VERSION "HNNBNNNYNNNNNNNNNNNNNNNNNNNNNNNNNNNNNNNNNN/4/%%%/4/'%**4NNN///"

NS_ :

BS_:

BU_: BAP_Tester BCM1 Gateway Gateway_PAG Klima_MSB Lift_VA VAS_L VAS_R

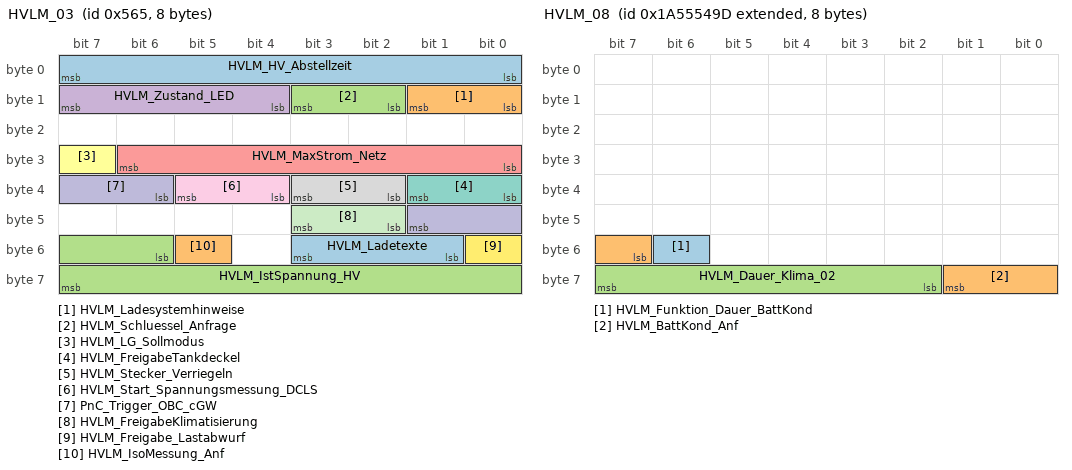
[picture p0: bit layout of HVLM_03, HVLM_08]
BO_ 1381 HVLM_03: 8 Gateway
 SG_ HVLM_HV_Abstellzeit : 0|8@1+ (4,0) [0|1012] "Unit_Minut"  Vector__XXX
 SG_ HVLM_Ladesystemhinweise : 8|2@1+ (1.0,0.0) [0.0|3] ""  Vector__XXX
 SG_ HVLM_Schluessel_Anfrage : 10|2@1+ (1.0,0.0) [0.0|3] ""  Vector__XXX
 SG_ HVLM_Zustand_LED : 12|4@1+ (1.0,0.0) [0.0|15] ""  Vector__XXX
 SG_ HVLM_MaxStrom_Netz : 24|7@1+ (0.5,0) [0.0|62.5] "Unit_Amper"  Vector__XXX
 SG_ HVLM_LG_Sollmodus : 31|1@1+ (1.0,0.0) [0.0|1] ""  Vector__XXX
 SG_ HVLM_FreigabeTankdeckel : 32|2@1+ (1.0,0.0) [0.0|3] ""  Vector__XXX
 SG_ HVLM_Stecker_Verriegeln : 34|2@1+ (1.0,0.0) [0.0|3] ""  Vector__XXX
 SG_ HVLM_Start_Spannungsmessung_DCLS : 36|2@1+ (1.0,0.0) [0.0|3] ""  Vector__XXX
 SG_ PnC_Trigger_OBC_cGW : 38|4@1+ (1.0,0.0) [0.0|15] ""  Vector__XXX
 SG_ HVLM_FreigabeKlimatisierung : 42|2@1+ (1.0,0.0) [0.0|3] ""  BCM1,Klima_MSB
 SG_ HVLM_Freigabe_Lastabwurf : 48|1@1+ (1.0,0.0) [0.0|1] ""  Vector__XXX
 SG_ HVLM_Ladetexte : 49|3@1+ (1.0,0.0) [0.0|7] ""  Vector__XXX
 SG_ HVLM_IsoMessung_Anf : 53|1@1+ (1.0,0.0) [0.0|1] ""  Vector__XXX
 SG_ HVLM_IstSpannung_HV : 54|10@1+ (1,0) [0|1021] "Unit_Volt"  Vector__XXX

BO_ 1340 HVLM_04: 8 Gateway
 SG_ HVLM_04_CRC : 0|8@1+ (1,0) [0|255] ""  Vector__XXX
 SG_ HVLM_04_BZ : 8|4@1+ (1,0) [0|15] ""  Vector__XXX
 SG_ HVLM_STH_Betriebsmodus : 12|3@1+ (1.0,0.0) [0.0|7] ""  BCM1,Klima_MSB
 SG_ HVLM_Standklima_Timer_Status : 15|1@1+ (1.0,0.0) [0.0|1] ""  BCM1,Klima_MSB
 SG_ HVLM_HVEM_MaxLeistung : 16|9@1+ (50,0) [0|25450] "Unit_Watt"  Vector__XXX
 SG_ HVLM_Status_Netz : 25|1@1+ (1.0,0.0) [0.0|1] ""  Vector__XXX
 SG_ HVLM_Anf_Ladescreen : 26|1@1+ (1.0,0.0) [0.0|1] ""  Vector__XXX
 SG_ HVLM_Ladeart : 27|2@1+ (1.0,0.0) [0.0|3] ""  Vector__XXX
 SG_ HVLM_VK_STH_Einsatz : 29|3@1+ (1.0,0.0) [0.0|7] ""  BCM1
 SG_ HVLM_VK_Modus : 32|2@1+ (1.0,0.0) [0.0|3] ""  BCM1,Klima_MSB
 SG_ HVLM_IstModus_02 : 34|2@1+ (1.0,0.0) [0.0|3] ""  Vector__XXX
 SG_ HVLM_HV_Anf : 36|2@1+ (1.0,0.0) [0.0|3] ""  Vector__XXX
 SG_ HVLM_Fehlerstatus : 38|3@1+ (1.0,0.0) [0.0|7] ""  Vector__XXX
 SG_ HVLM_Anforderung_HMS : 41|3@1+ (1.0,0.0) [0.0|7] ""  Vector__XXX
 SG_ HVLM_Parken_beibehalten_HMS : 44|2@1+ (1.0,0.0) [0.0|3] ""  Vector__XXX
 SG_ HVLM_Status_Tankklappe : 46|2@1+ (1.0,0.0) [0.0|3] ""  Vector__XXX
 SG_ HVLM_AWC_Sollmodus : 48|3@1+ (1.0,0.0) [0.0|7] ""  Vector__XXX
 SG_ HVLM_Stecker_Status : 51|2@1+ (1.0,0.0) [0.0|3] ""  Vector__XXX
 SG_ HVLM_LadeAnforderung : 53|3@1+ (1.0,0.0) [0.0|7] ""  Vector__XXX
 SG_ HVLM_MaxBatLadestromHV : 56|8@1+ (1,0) [0|253] "Unit_Amper"  Vector__XXX

BO_ 2589283485 HVLM_08: 8 Gateway
 SG_ HVLM_Funktion_Dauer_BattKond : 54|1@1+ (1.0,0.0) [0.0|1] ""  Vector__XXX
 SG_ HVLM_BattKond_Anf : 55|3@1+ (1.0,0.0) [0.0|7] ""  Vector__XXX
 SG_ HVLM_Dauer_Klima_02 : 58|6@1+ (1,0) [0|60] "Unit_Minut"  BCM1,Klima_MSB

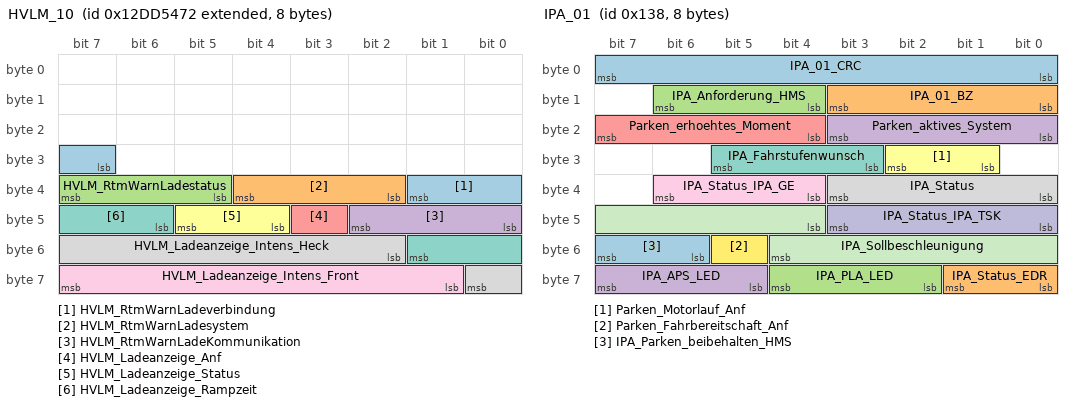
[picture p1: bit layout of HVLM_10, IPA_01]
BO_ 2463978610 HVLM_10: 8 Gateway
 SG_ HVLM_RtmWarnLadeverbindung : 31|3@1+ (1.0,0.0) [0.0|7] ""  Vector__XXX
 SG_ HVLM_RtmWarnLadesystem : 34|3@1+ (1.0,0.0) [0.0|7] ""  Vector__XXX
 SG_ HVLM_RtmWarnLadestatus : 37|3@1+ (1.0,0.0) [0.0|7] ""  Vector__XXX
 SG_ HVLM_RtmWarnLadeKommunikation : 40|3@1+ (1.0,0.0) [0.0|7] ""  Vector__XXX
 SG_ HVLM_Ladeanzeige_Anf : 43|1@1+ (1.0,0.0) [0.0|1] ""  BCM1
 SG_ HVLM_Ladeanzeige_Status : 44|2@1+ (1.0,0.0) [0.0|3] ""  BCM1
 SG_ HVLM_Ladeanzeige_Rampzeit : 46|4@1+ (50,0) [0|750] "Unit_MilliSecon"  Vector__XXX
 SG_ HVLM_Ladeanzeige_Intens_Heck : 50|7@1+ (1,0) [0|100] "Unit_PerCent"  Vector__XXX
 SG_ HVLM_Ladeanzeige_Intens_Front : 57|7@1+ (1,0) [0|100] "Unit_PerCent"  Vector__XXX

BO_ 1524 Innenlicht_11: 8 BCM1
 SG_ IL_Dimmung_V_Tuerkontur : 0|8@1+ (1,0) [0|100] "Unit_PerCent"  Gateway,Gateway_PAG
 SG_ IL_Dimmung_H_Tuerkontur : 8|8@1+ (1,0) [0|100] "Unit_PerCent"  Gateway,Gateway_PAG
 SG_ IL_Dimmung_Tuerinnengriff : 16|8@1+ (1,0) [0|100] "Unit_PerCent"  Gateway,Gateway_PAG
 SG_ IL_Dimmung_Umfeldbel : 24|8@1+ (1,0) [0|100] "Unit_PerCent"  Gateway,Gateway_PAG
 SG_ IL_Bel_FS_Ausstieg : 32|1@1+ (1.0,0.0) [0.0|1] ""  Gateway,Gateway_PAG
 SG_ IL_Bel_BFS_Ausstieg : 33|1@1+ (1.0,0.0) [0.0|1] ""  Gateway,Gateway_PAG
 SG_ IL_Bel_HFS_Ausstieg : 34|1@1+ (1.0,0.0) [0.0|1] ""  Gateway,Gateway_PAG
 SG_ IL_Bel_HBFS_Ausstieg : 35|1@1+ (1.0,0.0) [0.0|1] ""  Gateway,Gateway_PAG
 SG_ BCM1_Innenlicht_gedimmt_V : 36|1@1+ (1.0,0.0) [0.0|1] ""  Gateway,Gateway_PAG
 SG_ BCM1_Innenlicht_gedimmt_H : 37|1@1+ (1.0,0.0) [0.0|1] ""  Gateway,Gateway_PAG
 SG_ IL_Innenlicht_aktiv : 38|1@1+ (1.0,0.0) [0.0|1] ""  Gateway,Gateway_PAG
 SG_ IL_Klemme_30G_aktiv : 39|1@1+ (1.0,0.0) [0.0|1] ""  Gateway,Gateway_PAG
 SG_ BCM1_DI_Rampe_Innenlicht : 40|1@1+ (1.0,0.0) [0.0|1] ""  Gateway,Gateway_PAG
 SG_ BCM1_DI_Rampe_Leselicht : 41|1@1+ (1.0,0.0) [0.0|1] ""  Gateway,Gateway_PAG
 SG_ BCM1_Innenlicht_H : 42|1@1+ (1.0,0.0) [0.0|1] ""  Gateway,Gateway_PAG
 SG_ BCM1_Innenlicht_V : 43|1@1+ (1.0,0.0) [0.0|1] ""  Gateway,Gateway_PAG
 SG_ BCM1_Leselicht_Anf_hl : 44|1@1+ (1.0,0.0) [0.0|1] ""  Gateway,Gateway_PAG
 SG_ BCM1_Leselicht_Anf_hr : 45|1@1+ (1.0,0.0) [0.0|1] ""  Gateway,Gateway_PAG
 SG_ BCM1_Leselicht_Anf_vl : 46|1@1+ (1.0,0.0) [0.0|1] ""  Gateway,Gateway_PAG
 SG_ BCM1_Leselicht_Anf_vr : 47|1@1+ (1.0,0.0) [0.0|1] ""  Gateway,Gateway_PAG
 SG_ BCM1_Leuchten_Aus : 48|1@1+ (1.0,0.0) [0.0|1] ""  Gateway,Gateway_PAG
 SG_ AMB_Charisma_FahrPr : 49|4@1+ (1.0,0.0) [0.0|15] ""  Gateway,Gateway_PAG
 SG_ AMB_Charisma_Status : 53|2@1+ (1.0,0.0) [0.0|3] ""  Gateway,Gateway_PAG
 SG_ IL_Dimmung_Lautspr : 56|8@1+ (1,0) [0|100] "Unit_PerCent"  Gateway,Gateway_PAG

BO_ 312 IPA_01: 8 Gateway
 SG_ IPA_01_CRC : 0|8@1+ (1,0) [0|255] ""  Vector__XXX
 SG_ IPA_01_BZ : 8|4@1+ (1,0) [0|15] ""  Vector__XXX
 SG_ IPA_Anforderung_HMS : 12|3@1+ (1.0,0.0) [0.0|7] ""  Vector__XXX
 SG_ Parken_aktives_System : 16|4@1+ (1.0,0.0) [0.0|15] ""  BCM1
 SG_ Parken_erhoehtes_Moment : 20|4@1+ (1.0,0.0) [0.0|15] ""  Vector__XXX
 SG_ Parken_Motorlauf_Anf : 25|2@1+ (1.0,0.0) [0.0|3] ""  Vector__XXX
 SG_ IPA_Fahrstufenwunsch : 27|3@1+ (1.0,0.0) [0.0|7] ""  Vector__XXX
 SG_ IPA_Status : 32|4@1+ (1.0,0.0) [0.0|15] ""  Vector__XXX
 SG_ IPA_Status_IPA_GE : 36|3@1+ (1.0,0.0) [0.0|7] ""  Vector__XXX
 SG_ IPA_Status_IPA_TSK : 40|4@1+ (1.0,0.0) [0.0|15] ""  BCM1
 SG_ IPA_Sollbeschleunigung : 44|9@1+ (0.01,-4.11) [-4.10|1.00] "Unit_MeterPerSeconSquar"  Vector__XXX
 SG_ Parken_Fahrbereitschaft_Anf : 53|1@1+ (1.0,0.0) [0.0|1] ""  Vector__XXX
 SG_ IPA_Parken_beibehalten_HMS : 54|2@1+ (1.0,0.0) [0.0|3] ""  Vector__XXX
 SG_ IPA_Status_EDR : 56|2@1+ (1.0,0.0) [0.0|3] ""  Vector__XXX
 SG_ IPA_PLA_LED : 58|3@1+ (1.0,0.0) [0.0|7] ""  BCM1
 SG_ IPA_APS_LED : 61|3@1+ (1.0,0.0) [0.0|7] ""  BCM1

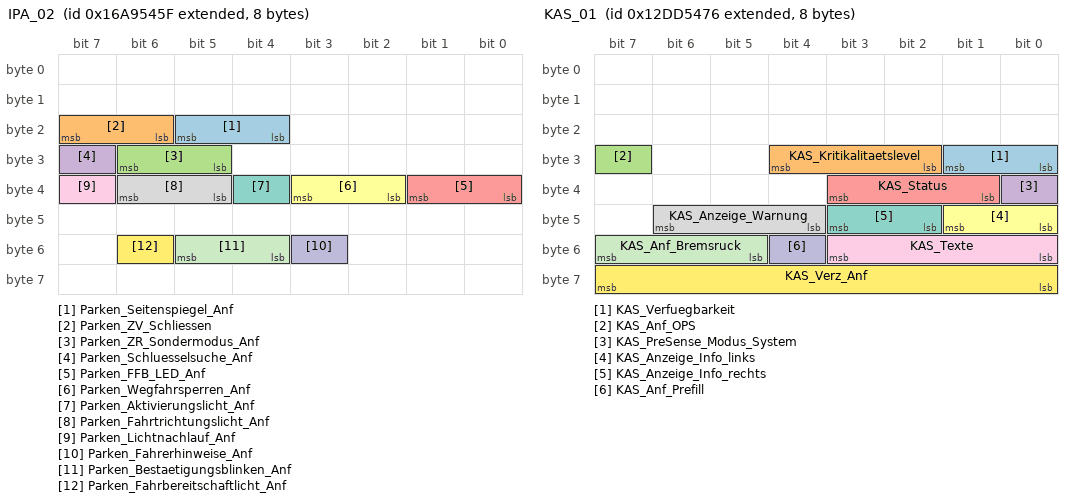
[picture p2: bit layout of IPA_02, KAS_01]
BO_ 2527679583 IPA_02: 8 Gateway
 SG_ Parken_Seitenspiegel_Anf : 20|2@1+ (1.0,0.0) [0.0|3] ""  Vector__XXX
 SG_ Parken_ZV_Schliessen : 22|2@1+ (1.0,0.0) [0.0|3] ""  Vector__XXX
 SG_ Parken_ZR_Sondermodus_Anf : 29|2@1+ (1.0,0.0) [0.0|3] ""  Vector__XXX
 SG_ Parken_Schluesselsuche_Anf : 31|1@1+ (1.0,0.0) [0.0|1] ""  Vector__XXX
 SG_ Parken_FFB_LED_Anf : 32|2@1+ (1.0,0.0) [0.0|3] ""  Vector__XXX
 SG_ Parken_Wegfahrsperren_Anf : 34|2@1+ (1.0,0.0) [0.0|3] ""  Vector__XXX
 SG_ Parken_Aktivierungslicht_Anf : 36|1@1+ (1.0,0.0) [0.0|1] ""  BCM1
 SG_ Parken_Fahrtrichtungslicht_Anf : 37|2@1+ (1.0,0.0) [0.0|3] ""  BCM1
 SG_ Parken_Lichtnachlauf_Anf : 39|1@1+ (1.0,0.0) [0.0|1] ""  BCM1
 SG_ Parken_Fahrerhinweise_Anf : 51|1@1+ (1.0,0.0) [0.0|1] ""  Vector__XXX
 SG_ Parken_Bestaetigungsblinken_Anf : 52|2@1+ (1.0,0.0) [0.0|3] ""  BCM1
 SG_ Parken_Fahrbereitschaftlicht_Anf : 54|1@1+ (1.0,0.0) [0.0|1] ""  BCM1

BO_ 1806 ISO_BCM1_Req: 8 Gateway
 SG_ ISO_BCM1_Req_Data : 0|64@1+ (1.0,0.0) [0.0|18446744073709551615] ""  BCM1

BO_ 1912 ISO_BCM1_Resp: 8 BCM1
 SG_ ISO_BCM1_Resp_Data : 0|64@1+ (1.0,0.0) [0.0|18446744073709551615] ""  Gateway,Gateway_PAG

BO_ 1792 ISO_Funktionaler_Req_All: 8 Gateway
 SG_ ISO_ALL_01_Req_Data : 0|64@1+ (1.0,0.0) [0.0|18446744073709551615] ""  BCM1,Klima_MSB,Lift_VA,VAS_L,VAS_R

BO_ 1862 ISO_Klima_Req: 8 Gateway
 SG_ ISO_Klima_Req_Data : 0|64@1+ (1.0,0.0) [0.0|18446744073709551615] ""  Klima_MSB

BO_ 1968 ISO_Klima_Resp: 8 Klima_MSB
 SG_ ISO_Klima_Resp_Data : 0|64@1+ (1.0,0.0) [0.0|18446744073709551615] ""  Gateway,Gateway_PAG

BO_ 1881 ISO_Lift_Req: 8 Gateway
 SG_ ISO_Lift_Req_Data : 0|64@1+ (1,0) [0|18446744073709551615] "Unit_None"  Lift_VA

BO_ 1987 ISO_Lift_Resp: 8 Lift_VA
 SG_ ISO_Lift_Resp_Data : 0|64@1+ (1,0) [0|18446744073709551615] "Unit_None"  Gateway,Gateway_PAG

BO_ 2549874840 ISOx_DMD_L_Req: 8 Gateway
 SG_ ISOx_DMD_L_Req_Data : 0|64@1+ (1.0,0.0) [0.0|18446744073709551615] ""  BCM1

BO_ 2550005912 ISOx_DMD_L_Resp: 8 BCM1
 SG_ ISOx_DMD_L_Resp_Data : 0|64@1+ (1.0,0.0) [0.0|18446744073709551615] ""  Gateway,Gateway_PAG

BO_ 2549874841 ISOx_DMD_R_Req: 8 Gateway
 SG_ ISOx_DMD_R_Req_Data : 0|64@1+ (1.0,0.0) [0.0|18446744073709551615] ""  BCM1

BO_ 2550005913 ISOx_DMD_R_Resp: 8 BCM1
 SG_ ISOx_DMD_R_Resp_Data : 0|64@1+ (1.0,0.0) [0.0|18446744073709551615] ""  Gateway,Gateway_PAG

BO_ 2549874818 ISOx_LCM_L_Req: 8 Gateway
 SG_ ISOx_LCM_L_Req_Data : 0|64@1+ (1.0,0.0) [0.0|18446744073709551615] ""  BCM1

BO_ 2550005890 ISOx_LCM_L_Resp: 8 BCM1
 SG_ ISOx_LCM_L_Resp_Data : 0|64@1+ (1.0,0.0) [0.0|18446744073709551615] ""  Gateway,Gateway_PAG

BO_ 2549874819 ISOx_LCM_R_Req: 8 Gateway
 SG_ ISOx_LCM_R_Req_Data : 0|64@1+ (1.0,0.0) [0.0|18446744073709551615] ""  BCM1

BO_ 2550005891 ISOx_LCM_R_Resp: 8 BCM1
 SG_ ISOx_LCM_R_Resp_Data : 0|64@1+ (1.0,0.0) [0.0|18446744073709551615] ""  Gateway,Gateway_PAG

BO_ 2549874838 ISOx_LED_LM_L_Req: 8 Gateway
 SG_ ISOx_LED_LM_L_Req_Data : 0|64@1+ (1.0,0.0) [0.0|18446744073709551615] ""  BCM1

BO_ 2550005910 ISOx_LED_LM_L_Resp: 8 BCM1
 SG_ ISOx_LED_LM_L_Resp_Data : 0|64@1+ (1.0,0.0) [0.0|18446744073709551615] ""  Gateway,Gateway_PAG

BO_ 2549874839 ISOx_LED_LM_R_Req: 8 Gateway
 SG_ ISOx_LED_LM_R_Req_Data : 0|64@1+ (1.0,0.0) [0.0|18446744073709551615] ""  BCM1

BO_ 2550005911 ISOx_LED_LM_R_Resp: 8 BCM1
 SG_ ISOx_LED_LM_R_Resp_Data : 0|64@1+ (1.0,0.0) [0.0|18446744073709551615] ""  Gateway,Gateway_PAG

BO_ 2549874884 ISOx_VAS_L_Req: 8 Gateway
 SG_ ISOx_VAS_L_Req_Data : 0|64@1+ (1.0,0.0) [0.0|18446744073709551615] ""  VAS_L

BO_ 2550005956 ISOx_VAS_L_Resp: 8 VAS_L
 SG_ ISOx_VAS_L_Resp_Data : 0|64@1+ (1.0,0.0) [0.0|18446744073709551615] ""  Gateway,Gateway_PAG

BO_ 2549874885 ISOx_VAS_R_Req: 8 Gateway
 SG_ ISOx_VAS_R_Req_Data : 0|64@1+ (1.0,0.0) [0.0|18446744073709551615] ""  VAS_R

BO_ 2550005957 ISOx_VAS_R_Resp: 8 VAS_R
 SG_ ISOx_VAS_R_Resp_Data : 0|64@1+ (1.0,0.0) [0.0|18446744073709551615] ""  Gateway,Gateway_PAG

BO_ 2549874843 ISOx_zDML_Req: 8 Gateway
 SG_ ISOx_zDML_Req_Data : 0|64@1+ (1.0,0.0) [0.0|18446744073709551615] ""  BCM1

BO_ 2550005915 ISOx_zDML_Resp: 8 BCM1
 SG_ ISOx_zDML_Resp_Data : 0|64@1+ (1.0,0.0) [0.0|18446744073709551615] ""  Gateway,Gateway_PAG

BO_ 2463978614 KAS_01: 8 Gateway
 SG_ KAS_Verfuegbarkeit : 24|2@1+ (1.0,0.0) [0.0|3] ""  Vector__XXX
 SG_ KAS_Kritikalitaetslevel : 26|3@1+ (1.0,0.0) [0.0|7] ""  BCM1
 SG_ KAS_Anf_OPS : 31|1@1+ (1.0,0.0) [0.0|1] ""  BCM1
 SG_ KAS_PreSense_Modus_System : 32|1@1+ (1.0,0.0) [0.0|1] ""  Vector__XXX
 SG_ KAS_Status : 33|3@1+ (1.0,0.0) [0.0|7] ""  Vector__XXX
 SG_ KAS_Anzeige_Info_links : 40|2@1+ (1.0,0.0) [0.0|3] ""  Vector__XXX
 SG_ KAS_Anzeige_Info_rechts : 42|2@1+ (1.0,0.0) [0.0|3] ""  Vector__XXX
 SG_ KAS_Anzeige_Warnung : 44|3@1+ (1.0,0.0) [0.0|7] ""  Vector__XXX
 SG_ KAS_Texte : 48|4@1+ (1.0,0.0) [0.0|15] ""  Vector__XXX
 SG_ KAS_Anf_Prefill : 52|1@1+ (1.0,0.0) [0.0|1] ""  Vector__XXX
 SG_ KAS_Anf_Bremsruck : 53|3@1+ (1.0,0.0) [0.0|7] ""  Vector__XXX
 SG_ KAS_Verz_Anf : 56|8@1+ (0.079,-19.987) [-19.987|0.000] "Unit_MeterPerSeconSquar"  Vector__XXX

BO_ 497 Kessy_11: 8 Gateway
 SG_ KY_IDG_in_Reichweite : 12|1@1+ (1.0,0.0) [0.0|1] ""  Vector__XXX
 SG_ KY_Auf_Taste : 13|1@1+ (1.0,0.0) [0.0|1] ""  Vector__XXX
 SG_ KY_HDF_Taste : 14|1@1+ (1.0,0.0) [0.0|1] ""  BCM1
 SG_ KY_Panik_Taste : 15|1@1+ (1.0,0.0) [0.0|1] ""  Vector__XXX
 SG_ KY_Zu_Taste : 16|1@1+ (1.0,0.0) [0.0|1] ""  Vector__XXX
 SG_ KY_FT_Entriegelung_Autorisiert : 17|1@1+ (1.0,0.0) [0.0|1] ""  BCM1
 SG_ KY_FT_Verriegelung_Autorisiert : 18|1@1+ (1.0,0.0) [0.0|1] ""  Vector__XXX
 SG_ KY_BT_Entriegelung_Autorisiert : 19|1@1+ (1.0,0.0) [0.0|1] ""  Vector__XXX
 SG_ KY_BT_Verriegelung_Autorisiert : 20|1@1+ (1.0,0.0) [0.0|1] ""  Vector__XXX
 SG_ KY_HFS_Entriegelung_Autorisiert : 21|1@1+ (1.0,0.0) [0.0|1] ""  Vector__XXX
 SG_ KY_HFS_Verriegelung_Autorisiert : 22|1@1+ (1.0,0.0) [0.0|1] ""  Vector__XXX
 SG_ KY_HBFS_Entriegelung_Autorisiert : 23|1@1+ (1.0,0.0) [0.0|1] ""  Vector__XXX
 SG_ KY_HBFS_Verriegelung_Autorisiert : 24|1@1+ (1.0,0.0) [0.0|1] ""  Vector__XXX
 SG_ KY_Front_Entr_Autorisiert : 25|1@1+ (1.0,0.0) [0.0|1] ""  BCM1
 SG_ KY_Front_Verr_Autorisiert : 26|1@1+ (1.0,0.0) [0.0|1] ""  BCM1
 SG_ KY_HD_Entriegelung_Autorisiert : 27|1@1+ (1.0,0.0) [0.0|1] ""  Vector__XXX
 SG_ KY_HD_Verriegelung_Autorisiert : 28|1@1+ (1.0,0.0) [0.0|1] ""  Vector__XXX
 SG_ KY_Bereich : 29|3@1+ (1.0,0.0) [0.0|7] ""  BCM1
 SG_ KY_Position : 32|3@1+ (1.0,0.0) [0.0|7] ""  BCM1
 SG_ KY_ZV_Signatur : 35|11@1+ (1,0) [0|2047] "Unit_None"  Vector__XXX
 SG_ Schluesselnr_Personalisierung : 46|4@1+ (1.0,0.0) [0.0|15] ""  BCM1,Klima_MSB
 SG_ FFB_FDF_Taste : 50|1@1+ (1.0,0.0) [0.0|1] ""  BCM1
 SG_ FFB_Joker_Taste : 51|1@1+ (1.0,0.0) [0.0|1] ""  BCM1
 SG_ FFB_Park_Taste : 52|1@1+ (1.0,0.0) [0.0|1] ""  Vector__XXX
 SG_ FFB_Remotestart_Taste : 53|1@1+ (1.0,0.0) [0.0|1] ""  Vector__XXX
 SG_ FBS_Aktivierung_Pilot_Parken : 54|1@1+ (1.0,0.0) [0.0|1] ""  Vector__XXX
 SG_ KY_Schluessel_im_Fzg : 55|1@1+ (1.0,0.0) [0.0|1] ""  Vector__XXX
 SG_ KY_EasyClose_Abbruch : 56|1@1+ (1.0,0.0) [0.0|1] ""  Vector__XXX
 SG_ KY_EasyClose_Status : 57|3@1+ (1.0,0.0) [0.0|7] ""  Vector__XXX
 SG_ KY_HD_Auffahrt : 60|1@1+ (1.0,0.0) [0.0|1] ""  Vector__XXX
 SG_ KY_HD_Zufahrt : 61|1@1+ (1.0,0.0) [0.0|1] ""  Vector__XXX
 SG_ KY_LKL_1_Autorisierung : 62|1@1+ (1.0,0.0) [0.0|1] ""  Vector__XXX
 SG_ KY_LKL_2_Autorisierung : 63|1@1+ (1.0,0.0) [0.0|1] ""  Vector__XXX

BO_ 1424 Kessy_12: 8 Gateway
 SG_ FBS_Warn_Schluessel_Batt : 12|1@1+ (1.0,0.0) [0.0|1] ""  Vector__XXX
 SG_ KY_FFB_Frequenz : 13|2@1+ (1.0,0.0) [0.0|3] ""  Vector__XXX
 SG_ KY_HF_Aktiv : 15|1@1+ (1.0,0.0) [0.0|1] ""  Vector__XXX
 SG_ KY_LF_Aktiv : 16|1@1+ (1.0,0.0) [0.0|1] ""  Vector__XXX
 SG_ KY_KYL_Fahrer_Hinweise : 17|3@1+ (1.0,0.0) [0.0|7] ""  Vector__XXX
 SG_ KY_StartStopp_Info : 20|2@1+ (1.0,0.0) [0.0|3] ""  Vector__XXX
 SG_ KY_Keyless_Verbau : 22|1@1+ (1.0,0.0) [0.0|1] ""  Vector__XXX
 SG_ KY_Keyless_Go_Verbau : 23|1@1+ (1.0,0.0) [0.0|1] ""  Vector__XXX
 SG_ KY_Transponder_aktiv : 24|1@1+ (1.0,0.0) [0.0|1] ""  BCM1
 SG_ KYL_Warn_kein_Schluessel : 25|1@1+ (1.0,0.0) [0.0|1] ""  Vector__XXX
 SG_ KYL_Warn_Kessy_defekt : 26|1@1+ (1.0,0.0) [0.0|1] ""  Vector__XXX
 SG_ KYL_Warn_Notzuendschloss : 27|1@1+ (1.0,0.0) [0.0|1] ""  Vector__XXX
 SG_ KY_Fzg_Verlassen_erkannt : 28|1@1+ (1.0,0.0) [0.0|1] ""  Vector__XXX
 SG_ KY_Fzg_Zugang_erkannt : 29|1@1+ (1.0,0.0) [0.0|1] ""  Vector__XXX
 SG_ KY_Indikator_Mehrere_Schluessel : 30|1@1+ (1.0,0.0) [0.0|1] ""  Vector__XXX
 SG_ KY_NFC_Fahrer_Hinweise : 41|3@1+ (1.0,0.0) [0.0|7] ""  Vector__XXX
 SG_ KST_Wegstrecke_Challenge : 44|20@1+ (1.0,0.0) [0.0|1048575] ""  Vector__XXX

BO_ 960 Klemmen_Status_01: 4 BCM1
 SG_ Klemmen_Status_01_CRC : 0|8@1+ (1,0) [0|255] ""  BCM1,Gateway,Gateway_PAG
 SG_ Klemmen_Status_01_BZ : 8|4@1+ (1,0) [0|15] ""  BCM1,Gateway,Gateway_PAG,Lift_VA
 SG_ RSt_Fahrerhinweise : 12|4@1+ (1.0,0.0) [0.0|15] ""  Gateway,Gateway_PAG
 SG_ ZAS_Kl_S : 16|1@1+ (1.0,0.0) [0.0|1] ""  BCM1,Gateway,Gateway_PAG,Klima_MSB,VAS_L,VAS_R
 SG_ ZAS_Kl_15 : 17|1@1+ (1.0,0.0) [0.0|1] ""  BCM1,Gateway,Gateway_PAG,Klima_MSB,Lift_VA,VAS_L,VAS_R
 SG_ ZAS_Kl_X : 18|1@1+ (1.0,0.0) [0.0|1] ""  Gateway,Gateway_PAG
 SG_ ZAS_Kl_50_Startanforderung : 19|1@1+ (1.0,0.0) [0.0|1] ""  BCM1,Gateway,Gateway_PAG,Klima_MSB
 SG_ BCM_Remotestart_Betrieb : 20|1@1+ (1.0,0.0) [0.0|1] ""  BCM1,Gateway,Gateway_PAG,Klima_MSB
 SG_ ZAS_Kl_Infotainment : 21|1@1+ (1.0,0.0) [0.0|1] ""  Gateway,Gateway_PAG
 SG_ BCM_Remotestart_KL15_Anf : 22|1@1+ (1.0,0.0) [0.0|1] ""  BCM1,Gateway,Gateway_PAG
 SG_ BCM_Remotestart_MO_Start : 23|1@1+ (1.0,0.0) [0.0|1] ""  Gateway,Gateway_PAG
 SG_ KST_Warn_P1_ZST_def : 24|1@1+ (1.0,0.0) [0.0|1] ""  Gateway,Gateway_PAG
 SG_ KST_Warn_P2_ZST_def : 25|1@1+ (1.0,0.0) [0.0|1] ""  Gateway,Gateway_PAG
 SG_ KST_Fahrerhinweis_1 : 26|1@1+ (1.0,0.0) [0.0|1] ""  Gateway,Gateway_PAG
 SG_ KST_Fahrerhinweis_2 : 27|1@1+ (1.0,0.0) [0.0|1] ""  Gateway,Gateway_PAG
 SG_ BCM_Ausparken_Betrieb : 28|1@1+ (1.0,0.0) [0.0|1] ""  Gateway,Gateway_PAG
 SG_ KST_Fahrerhinweis_4 : 29|1@1+ (1.0,0.0) [0.0|1] ""  Gateway,Gateway_PAG
 SG_ KST_Fahrerhinweis_5 : 30|1@1+ (1.0,0.0) [0.0|1] ""  Gateway,Gateway_PAG
 SG_ KST_Fahrerhinweis_6 : 31|1@1+ (1.0,0.0) [0.0|1] ""  Gateway,Gateway_PAG

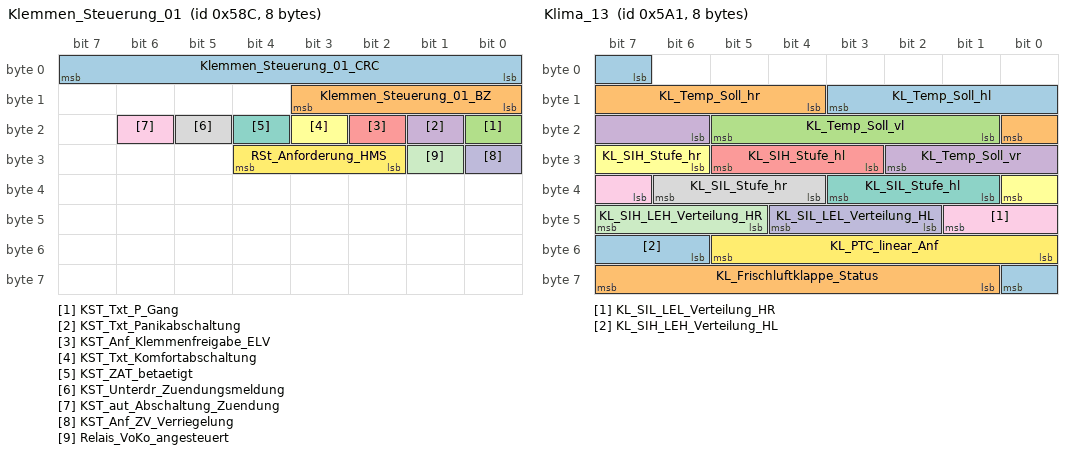
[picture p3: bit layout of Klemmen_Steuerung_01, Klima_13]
BO_ 1420 Klemmen_Steuerung_01: 8 Gateway
 SG_ Klemmen_Steuerung_01_CRC : 0|8@1+ (1,0) [0|255] ""  Vector__XXX
 SG_ Klemmen_Steuerung_01_BZ : 8|4@1+ (1,0) [0|15] ""  Vector__XXX
 SG_ KST_Txt_P_Gang : 16|1@1+ (1.0,0.0) [0.0|1] ""  Vector__XXX
 SG_ KST_Txt_Panikabschaltung : 17|1@1+ (1.0,0.0) [0.0|1] ""  Vector__XXX
 SG_ KST_Anf_Klemmenfreigabe_ELV : 18|1@1+ (1.0,0.0) [0.0|1] ""  Vector__XXX
 SG_ KST_Txt_Komfortabschaltung : 19|1@1+ (1.0,0.0) [0.0|1] ""  Vector__XXX
 SG_ KST_ZAT_betaetigt : 20|1@1+ (1.0,0.0) [0.0|1] ""  Vector__XXX
 SG_ KST_Unterdr_Zuendungsmeldung : 21|1@1+ (1.0,0.0) [0.0|1] ""  Vector__XXX
 SG_ KST_aut_Abschaltung_Zuendung : 22|1@1+ (1.0,0.0) [0.0|1] ""  BCM1
 SG_ KST_Anf_ZV_Verriegelung : 24|1@1+ (1.0,0.0) [0.0|1] ""  Vector__XXX
 SG_ Relais_VoKo_angesteuert : 25|1@1+ (1.0,0.0) [0.0|1] ""  BCM1
 SG_ RSt_Anforderung_HMS : 26|3@1+ (1.0,0.0) [0.0|7] ""  Vector__XXX

BO_ 1646 Klima_03: 8 BCM1
 SG_ KL_STL_aktiv : 0|1@1+ (1.0,0.0) [0.0|1] ""  Gateway,Gateway_PAG
 SG_ KL_STH_aktiv : 1|1@1+ (1.0,0.0) [0.0|1] ""  BCM1,Gateway,Gateway_PAG
 SG_ KL_Solarluefter_aktiv : 2|1@1+ (1.0,0.0) [0.0|1] ""  Gateway,Gateway_PAG
 SG_ KL_Umluft_Taste : 3|1@1+ (1.0,0.0) [0.0|1] ""  Gateway,Gateway_PAG
 SG_ KL_Geblaese_Fond_Status : 4|4@1+ (1.0,0.0) [0.0|15] ""  BCM1,Gateway,Gateway_PAG
 SG_ KL_STH_Ansteuerung : 8|2@1+ (1.0,0.0) [0.0|3] ""  Gateway,Gateway_PAG
 SG_ KL_STH_Betriebsdauer : 10|6@1+ (1,0) [0|60] "Unit_Minut"  Gateway,Gateway_PAG
 SG_ KL_Magnetventil : 16|1@1+ (1.0,0.0) [0.0|1] ""  Gateway,Gateway_PAG
 SG_ KL_WaPu : 17|1@1+ (1.0,0.0) [0.0|1] ""  Gateway,Gateway_PAG
 SG_ KL_Geblaese_Status : 18|4@1+ (1.0,0.0) [0.0|15] ""  BCM1,Gateway,Gateway_PAG
 SG_ KL_Restwaerme_aktiv : 22|1@1+ (1.0,0.0) [0.0|1] ""  Gateway,Gateway_PAG
 SG_ KL_Kompressorkupplung : 23|1@1+ (1.0,0.0) [0.0|1] ""  BCM1,Gateway,Gateway_PAG
 SG_ KL_BCmE_Livetip_Freigabe : 24|1@1+ (1.0,0.0) [0.0|1] ""  Gateway,Gateway_PAG
 SG_ KL_HYB_ASV_hinten_schliessen_Anf : 25|1@1+ (1.0,0.0) [0.0|1] ""  Gateway,Gateway_PAG
 SG_ KL_HYB_ASV_vorne_schliessen_Anf : 26|1@1+ (1.0,0.0) [0.0|1] ""  Gateway,Gateway_PAG
 SG_ KL_ErwVK_Zusatzrelais : 27|1@1+ (1.0,0.0) [0.0|1] ""  Gateway,Gateway_PAG
 SG_ KL_Status_Beduftung : 28|1@1+ (1.0,0.0) [0.0|1] ""  Gateway,Gateway_PAG
 SG_ KL_Status_Ionisator_Front : 29|1@1+ (1.0,0.0) [0.0|1] ""  Gateway,Gateway_PAG
 SG_ KL_STH_Timer_Status : 30|1@1+ (1.0,0.0) [0.0|1] ""  Gateway,Gateway_PAG
 SG_ KL_ErwVK_Anf : 31|1@1+ (1.0,0.0) [0.0|1] ""  BCM1,Gateway,Gateway_PAG
 SG_ KL_Innen_Temp : 32|8@1+ (0.5,-50) [-50.0|76.0] "Unit_DegreCelsi"  BCM1,Gateway,Gateway_PAG
 SG_ KL_I_Geblaese_Fond : 40|8@1+ (0.25,0) [0.00|63.50] "Unit_Amper"  Gateway,Gateway_PAG
 SG_ KL_Anf_AussenspiegelHzg : 48|1@1+ (1.0,0.0) [0.0|1] ""  Gateway,Gateway_PAG,VAS_L,VAS_R
 SG_ KL_Heizkreisventilstellung : 49|2@1+ (1.0,0.0) [0.0|3] ""  Gateway,Gateway_PAG
 SG_ KL_FSH_Automatikbetrieb : 51|1@1+ (1.0,0.0) [0.0|1] ""  Gateway,Gateway_PAG
 SG_ KL_SIH_LEH_Verteilung_VL : 52|3@1+ (1.0,0.0) [0.0|7] ""  Gateway,Gateway_PAG
 SG_ KL_SIH_LEL_Verteilung_VL : 55|3@1+ (1.0,0.0) [0.0|7] ""  BCM1,Gateway,Gateway_PAG
 SG_ KL_SIH_LEH_Verteilung_VR : 58|3@1+ (1.0,0.0) [0.0|7] ""  BCM1,Gateway,Gateway_PAG
 SG_ KL_SIH_LEL_Verteilung_VR : 61|3@1+ (1.0,0.0) [0.0|7] ""  Gateway,Gateway_PAG

BO_ 1663 Klima_05: 8 BCM1
 SG_ KL_Mod_Display_li : 0|4@1+ (1.0,0.0) [0.0|15] ""  Gateway,Gateway_PAG
 SG_ KL_Mod_Display_re : 4|4@1+ (1.0,0.0) [0.0|15] ""  Gateway,Gateway_PAG
 SG_ KL_Fondbed_vorne_aktiv : 8|1@1+ (1.0,0.0) [0.0|1] ""  Gateway,Gateway_PAG
 SG_ KL_Fond_re_reduziert : 9|1@1+ (1.0,0.0) [0.0|1] ""  Gateway,Gateway_PAG
 SG_ KL_Fond_li_reduziert : 10|1@1+ (1.0,0.0) [0.0|1] ""  Gateway,Gateway_PAG
 SG_ KL_Absperrventil_Fond : 11|1@1+ (1.0,0.0) [0.0|1] ""  Gateway,Gateway_PAG
 SG_ KL_SH_HL_Lastabschaltung : 12|2@1+ (1.0,0.0) [0.0|3] ""  Gateway,Gateway_PAG
 SG_ KL_SH_HR_Lastabschaltung : 14|2@1+ (1.0,0.0) [0.0|3] ""  Gateway,Gateway_PAG
 SG_ KL_Sollausblastemp_HL : 16|10@1+ (0.1,0) [0.0|102.2] "Unit_DegreCelsi"  Gateway,Gateway_PAG
 SG_ KL_Einheiten : 26|1@1+ (1.0,0.0) [0.0|1] ""  Gateway,Gateway_PAG
 SG_ KL_Kindersicherung : 27|1@1+ (1.0,0.0) [0.0|1] ""  Gateway,Gateway_PAG
 SG_ KL_Heizverbraucher_aus : 28|1@1+ (1.0,0.0) [0.0|1] ""  Gateway,Gateway_PAG
 SG_ KL_Heizverbraucher_Notaus : 29|1@1+ (1.0,0.0) [0.0|1] ""  Gateway,Gateway_PAG
 SG_ KL_Gebl_Verst_Abs_Modus : 30|1@1+ (1.0,0.0) [0.0|1] ""  Gateway,Gateway_PAG
 SG_ KL_Sollausblastemp_HR : 32|10@1+ (0.1,0) [0.0|102.2] "Unit_DegreCelsi"  Gateway,Gateway_PAG
 SG_ KL_ICO2_Sensor_defekt : 42|2@1+ (1.0,0.0) [0.0|3] ""  Gateway,Gateway_PAG
 SG_ KL_Umluft : 48|8@1+ (0.5,0) [0.0|100.0] "Unit_PerCent"  Gateway,Gateway_PAG
 SG_ KL_Geblaesespg_Fond : 56|8@1+ (0.1,0) [0.0|25.5] "Unit_Volt"  Gateway,Gateway_PAG

BO_ 1649 Klima_06: 8 BCM1
 SG_ KL_ZZ_Minute : 0|6@1+ (1,0) [0|59] "Unit_Minut"  Gateway,Gateway_PAG
 SG_ KL_ZZ_Status_Timer : 6|2@1+ (1.0,0.0) [0.0|3] ""  Gateway,Gateway_PAG
 SG_ KL_ZZ_Monat : 8|4@1+ (1,0) [1|12] "Unit_Month"  Gateway,Gateway_PAG
 SG_ KL_ZZ_Stunde : 16|5@1+ (1,0) [0|23] "Unit_Hours"  Gateway,Gateway_PAG
 SG_ KL_ZZ_Betriebsmodus : 21|3@1+ (1.0,0.0) [0.0|7] ""  Gateway,Gateway_PAG
 SG_ KL_ZZ_Tag : 24|5@1+ (1,0) [1|31] "Unit_Day"  Gateway,Gateway_PAG
 SG_ KL_Betriebsmodus_FH : 29|3@1+ (1.0,0.0) [0.0|7] ""  Gateway,Gateway_PAG
 SG_ KL_Stopp_Wiederstart_Anz_01 : 32|1@1+ (1.0,0.0) [0.0|1] ""  Gateway,Gateway_PAG
 SG_ KL_Stopp_Wiederstart_Anz_02 : 33|1@1+ (1.0,0.0) [0.0|1] ""  Gateway,Gateway_PAG
 SG_ KL_Stopp_Wiederstart_Anz_03 : 34|1@1+ (1.0,0.0) [0.0|1] ""  Gateway,Gateway_PAG
 SG_ KL_Stopp_Wiederstart_Anz_04 : 35|1@1+ (1.0,0.0) [0.0|1] ""  Gateway,Gateway_PAG
 SG_ KL_Stopp_Wiederstart_Anz_05 : 36|1@1+ (1.0,0.0) [0.0|1] ""  Gateway,Gateway_PAG
 SG_ KL_Stopp_Wiederstart_Anz_06 : 37|1@1+ (1.0,0.0) [0.0|1] ""  Gateway,Gateway_PAG
 SG_ KL_Stopp_Wiederstart_Anz_07 : 38|1@1+ (1.0,0.0) [0.0|1] ""  Gateway,Gateway_PAG
 SG_ KL_Stopp_Wiederstart_Anz_08 : 39|1@1+ (1.0,0.0) [0.0|1] ""  Gateway,Gateway_PAG
 SG_ KL_Stopp_Wiederstart_Anz_09 : 40|1@1+ (1.0,0.0) [0.0|1] ""  Gateway,Gateway_PAG
 SG_ KL_Stopp_Wiederstart_Anz_Std1 : 41|1@1+ (1.0,0.0) [0.0|1] ""  Gateway,Gateway_PAG
 SG_ KL_Stopp_Wiederstart_Anz_Std2 : 42|1@1+ (1.0,0.0) [0.0|1] ""  Gateway,Gateway_PAG

BO_ 1608 Klima_07: 8 BCM1
 SG_ KL_AUTO_HL_Soll : 0|1@1+ (1.0,0.0) [0.0|1] ""  Gateway,Gateway_PAG
 SG_ KL_AUTO_HR_Soll : 1|1@1+ (1.0,0.0) [0.0|1] ""  Gateway,Gateway_PAG
 SG_ KL_AC_Fond_Soll : 2|1@1+ (1.0,0.0) [0.0|1] ""  Gateway,Gateway_PAG
 SG_ KL_Fondbedienung_aktiv : 3|1@1+ (1.0,0.0) [0.0|1] ""  Gateway,Gateway_PAG
 SG_ KL_Status_Soll : 4|1@1+ (1.0,0.0) [0.0|1] ""  Gateway,Gateway_PAG
 SG_ KL_Befehlszaehler_FH : 5|3@1+ (1,0) [0|7] ""  Gateway,Gateway_PAG
 SG_ KL_Luftmenge_HR_Soll : 8|4@1+ (1,0) [0|12] ""  Gateway,Gateway_PAG
 SG_ KL_Luftmenge_HL_Soll : 12|4@1+ (1,0) [0|12] ""  Gateway,Gateway_PAG
 SG_ KL_Luftverteilung_HR_Soll : 16|4@1+ (1.0,0.0) [0.0|15] ""  Gateway,Gateway_PAG
 SG_ KL_Luftverteilung_HL_Soll : 20|4@1+ (1.0,0.0) [0.0|15] ""  Gateway,Gateway_PAG
 SG_ KL_SL_HL_Soll : 24|3@1+ (1,0) [0|6] ""  BCM1,Gateway,Gateway_PAG
 SG_ KL_SL_HR_Soll : 27|3@1+ (1,0) [0|6] ""  BCM1,Gateway,Gateway_PAG
 SG_ KL_SH_HR_Soll : 30|3@1+ (1,0) [0|6] ""  BCM1,Gateway,Gateway_PAG
 SG_ KL_SH_HL_Soll : 33|3@1+ (1,0) [0|6] ""  BCM1,Gateway,Gateway_PAG
 SG_ KL_Temp_HL_Soll : 36|5@1+ (0.5,15.5) [15.5|30.0] "Unit_DegreCelsi"  Gateway,Gateway_PAG
 SG_ KL_Temp_HR_Soll : 41|5@1+ (0.5,15.5) [15.5|30.0] "Unit_DegreCelsi"  Gateway,Gateway_PAG
 SG_ KL_Luftmenge_HR_max : 46|4@1+ (1,0) [0|12] ""  Gateway,Gateway_PAG
 SG_ KL_Luftmenge_HL_max : 50|4@1+ (1,0) [0|12] ""  Gateway,Gateway_PAG
 SG_ KL_Luftmenge_HR_offset : 54|5@1+ (1,-12) [-12|12] ""  Gateway,Gateway_PAG
 SG_ KL_Luftmenge_HL_offset : 59|5@1+ (1,-12) [-12|12] ""  Gateway,Gateway_PAG

BO_ 949 Klima_11: 8 BCM1
 SG_ KL_Drehz_Anh : 0|1@1+ (1.0,0.0) [0.0|1] ""  Gateway,Gateway_PAG
 SG_ KL_Vorwarn_Komp_ein : 1|1@1+ (1.0,0.0) [0.0|1] ""  Gateway,Gateway_PAG
 SG_ KL_AC_Schalter : 2|1@1+ (1.0,0.0) [0.0|1] ""  Gateway,Gateway_PAG
 SG_ KL_Komp_Moment_alt : 3|1@1+ (1.0,0.0) [0.0|1] ""  Gateway,Gateway_PAG
 SG_ KL_Vorwarn_Zuheizer_ein : 6|1@1+ (1.0,0.0) [0.0|1] ""  Gateway,Gateway_PAG
 SG_ KL_Zustand : 7|1@1+ (1.0,0.0) [0.0|1] ""  Gateway,Gateway_PAG
 SG_ KL_Kompressorkupplung_linear : 8|8@1+ (20,0) [0|4000] "Unit_MilliAmper"  BCM1,Gateway,Gateway_PAG
 SG_ KL_Charisma_FahrPr : 16|4@1+ (1.0,0.0) [0.0|15] ""  Gateway,Gateway_PAG
 SG_ KL_Charisma_Status : 20|2@1+ (1.0,0.0) [0.0|3] ""  Gateway,Gateway_PAG
 SG_ KL_nachtr_Stopp_Anf : 22|1@1+ (1.0,0.0) [0.0|1] ""  Gateway,Gateway_PAG
 SG_ KL_T_Charge : 23|1@1+ (1.0,0.0) [0.0|1] ""  Gateway,Gateway_PAG
 SG_ KL_Last_Kompr : 24|8@1+ (0.25,0) [0.00|63.50] "Unit_NewtoMeter"  Gateway,Gateway_PAG
 SG_ KL_Spannungs_Anf : 32|2@1+ (1.0,0.0) [0.0|3] ""  Gateway,Gateway_PAG
 SG_ KL_Thermomanagement : 34|2@1+ (1.0,0.0) [0.0|3] ""  Gateway,Gateway_PAG
 SG_ KL_StartStopp_Info : 36|2@1+ (1.0,0.0) [0.0|3] ""  Gateway,Gateway_PAG
 SG_ KL_Freilauf_Info : 38|2@1+ (1.0,0.0) [0.0|3] ""  Gateway,Gateway_PAG
 SG_ KL_Anf_KL : 40|8@1+ (0.4,0) [0.0|101.6] "Unit_PerCent"  Gateway,Gateway_PAG
 SG_ KL_el_Zuheizer_Stufe : 48|3@1+ (1.0,0.0) [0.0|7] ""  BCM1,Gateway,Gateway_PAG
 SG_ KL_Ausstattung_Klima : 51|3@1+ (1.0,0.0) [0.0|7] ""  BCM1,Gateway,Gateway_PAG
 SG_ KL_Variante_Standheizung : 54|2@1+ (1.0,0.0) [0.0|3] ""  Gateway,Gateway_PAG

BO_ 1640 Klima_12: 8 BCM1
 SG_ KL_LRH_Taster : 0|1@1+ (1.0,0.0) [0.0|1] ""  Gateway,Gateway_PAG
 SG_ KL_LRH_Stufe : 1|2@1+ (1.0,0.0) [0.0|3] ""  Gateway,Gateway_PAG
 SG_ HSH_Taster : 3|2@1+ (1.0,0.0) [0.0|3] ""  Gateway,Gateway_PAG,VAS_L,VAS_R
 SG_ FSH_Taster : 5|1@1+ (1.0,0.0) [0.0|1] ""  Gateway,Gateway_PAG,VAS_L,VAS_R
 SG_ KL_Zuheizer_Freigabe : 6|1@1+ (1.0,0.0) [0.0|1] ""  Gateway,Gateway_PAG
 SG_ KL_Beschlagsgefahr : 7|1@1+ (1.0,0.0) [0.0|1] ""  Gateway,Gateway_PAG
 SG_ KL_SIH_Soll_li : 8|3@1+ (1,0) [0|6] ""  BCM1,Gateway,Gateway_PAG
 SG_ KL_SIH_Soll_re : 11|3@1+ (1,0) [0|6] ""  BCM1,Gateway,Gateway_PAG
 SG_ KRH_Soll_li : 14|2@1+ (1.0,0.0) [0.0|3] ""  Gateway,Gateway_PAG
 SG_ KL_SIL_Soll_li : 16|3@1+ (1,0) [0|6] ""  BCM1,Gateway,Gateway_PAG
 SG_ KL_SIL_Soll_re : 19|3@1+ (1,0) [0|6] ""  BCM1,Gateway,Gateway_PAG
 SG_ KRH_Soll_re : 22|2@1+ (1.0,0.0) [0.0|3] ""  Gateway,Gateway_PAG
 SG_ KL_Geblspng_Soll : 24|8@1+ (0.05,1.45) [1.50|14.00] "Unit_Volt"  Gateway,Gateway_PAG
 SG_ KL_Geblspng_Fond_Soll : 32|8@1+ (0.05,1.45) [1.50|14.00] "Unit_Volt"  Gateway,Gateway_PAG
 SG_ KL_I_Geblaese : 40|8@1+ (0.25,0) [0.00|63.50] "Unit_Amper"  Gateway,Gateway_PAG
 SG_ KL_Kompressorstrom_soll : 48|10@1+ (1,0) [0|1021] ""  BCM1,Gateway,Gateway_PAG
 SG_ KL_Umluftklappe_Status : 58|4@1+ (1.0,0.0) [0.0|15] ""  Gateway,Gateway_PAG
 SG_ KL_PTC_Verbauinfo : 62|2@1+ (1.0,0.0) [0.0|3] ""  Gateway,Gateway_PAG

BO_ 1441 Klima_13: 8 BCM1
 SG_ KL_Temp_Soll_hl : 7|5@1+ (0.5,15.5) [15.5|30.0] "Unit_DegreCelsi"  BCM1,Gateway,Gateway_PAG
 SG_ KL_Temp_Soll_hr : 12|5@1+ (0.5,15.5) [15.5|30.0] "Unit_DegreCelsi"  BCM1,Gateway,Gateway_PAG
 SG_ KL_Temp_Soll_vl : 17|5@1+ (0.5,15.5) [15.5|30.0] "Unit_DegreCelsi"  BCM1,Gateway,Gateway_PAG
 SG_ KL_Temp_Soll_vr : 22|5@1+ (0.5,15.5) [15.5|30.0] "Unit_DegreCelsi"  BCM1,Gateway,Gateway_PAG
 SG_ KL_SIH_Stufe_hl : 27|3@1+ (1,0) [0|6] ""  Gateway,Gateway_PAG
 SG_ KL_SIH_Stufe_hr : 30|3@1+ (1,0) [0|6] ""  Gateway,Gateway_PAG
 SG_ KL_SIL_Stufe_hl : 33|3@1+ (1,0) [0|6] ""  Gateway,Gateway_PAG
 SG_ KL_SIL_Stufe_hr : 36|3@1+ (1,0) [0|6] ""  Gateway,Gateway_PAG
 SG_ KL_SIL_LEL_Verteilung_HR : 39|3@1+ (1.0,0.0) [0.0|7] ""  BCM1,Gateway,Gateway_PAG
 SG_ KL_SIL_LEL_Verteilung_HL : 42|3@1+ (1.0,0.0) [0.0|7] ""  BCM1,Gateway,Gateway_PAG
 SG_ KL_SIH_LEH_Verteilung_HR : 45|3@1+ (1.0,0.0) [0.0|7] ""  BCM1,Gateway,Gateway_PAG
 SG_ KL_PTC_linear_Anf : 48|6@1+ (50,0) [0|3100] "Unit_Watt"  Gateway,Gateway_PAG
 SG_ KL_SIH_LEH_Verteilung_HL : 54|3@1+ (1.0,0.0) [0.0|7] ""  BCM1,Gateway,Gateway_PAG
 SG_ KL_Frischluftklappe_Status : 57|7@1+ (1,0) [0|100] "Unit_PerCent"  Gateway,Gateway_PAG

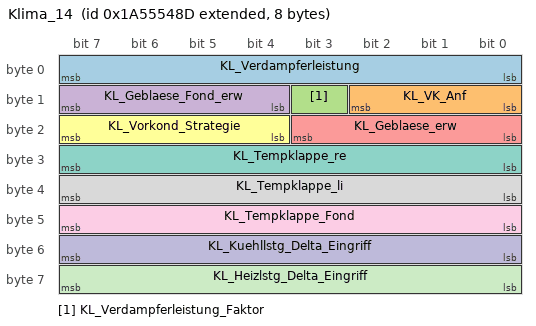
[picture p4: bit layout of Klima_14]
BO_ 2589283469 Klima_14: 8 BCM1
 SG_ KL_Verdampferleistung : 0|8@1+ (25,0) [0|6325] "Unit_Watt"  Gateway,Gateway_PAG
 SG_ KL_VK_Anf : 8|3@1+ (1.0,0.0) [0.0|7] ""  Gateway,Gateway_PAG
 SG_ KL_Verdampferleistung_Faktor : 11|1@1+ (1.0,0.0) [0.0|1] ""  Gateway,Gateway_PAG
 SG_ KL_Geblaese_Fond_erw : 12|4@1+ (1.0,0.0) [0.0|15] ""  Gateway,Gateway_PAG
 SG_ KL_Geblaese_erw : 16|4@1+ (1.0,0.0) [0.0|15] ""  Gateway,Gateway_PAG
 SG_ KL_Vorkond_Strategie : 20|4@1+ (1.0,0.0) [0.0|15] ""  Gateway,Gateway_PAG
 SG_ KL_Tempklappe_re : 24|8@1+ (0.5,0) [0.0|100.0] "Unit_PerCent"  Gateway,Gateway_PAG
 SG_ KL_Tempklappe_li : 32|8@1+ (0.5,0) [0.0|100.0] "Unit_PerCent"  Gateway,Gateway_PAG
 SG_ KL_Tempklappe_Fond : 40|8@1+ (0.5,0) [0.0|100.0] "Unit_PerCent"  Gateway,Gateway_PAG
 SG_ KL_Kuehllstg_Delta_Eingriff : 48|8@1+ (50,-6300) [-6300|6350] "Unit_Watt"  Gateway,Gateway_PAG
 SG_ KL_Heizlstg_Delta_Eingriff : 56|8@1+ (50,-6300) [-6300|6350] "Unit_Watt"  Gateway,Gateway_PAG

BO_TX_BU_ 1381 :Gateway,Gateway_PAG;
BO_TX_BU_ 1340 :Gateway,Gateway_PAG;
BO_TX_BU_ 2589283485 :Gateway,Gateway_PAG;
BO_TX_BU_ 2463978610 :Gateway,Gateway_PAG;
BO_TX_BU_ 312 :Gateway,Gateway_PAG;
BO_TX_BU_ 2527679583 :Gateway,Gateway_PAG;
BO_TX_BU_ 1806 :Gateway,Gateway_PAG;
BO_TX_BU_ 1792 :Gateway,Gateway_PAG;
BO_TX_BU_ 1862 :Gateway,Gateway_PAG;
BO_TX_BU_ 1881 :Gateway,Gateway_PAG;
BO_TX_BU_ 2549874840 :Gateway,Gateway_PAG;
BO_TX_BU_ 2549874841 :Gateway,Gateway_PAG;
BO_TX_BU_ 2549874818 :Gateway,Gateway_PAG;
BO_TX_BU_ 2549874819 :Gateway,Gateway_PAG;
BO_TX_BU_ 2549874838 :Gateway,Gateway_PAG;
BO_TX_BU_ 2549874839 :Gateway,Gateway_PAG;
BO_TX_BU_ 2549874884 :Gateway,Gateway_PAG;
BO_TX_BU_ 2549874885 :Gateway,Gateway_PAG;
BO_TX_BU_ 2549874843 :Gateway,Gateway_PAG;
BO_TX_BU_ 2463978614 :Gateway,Gateway_PAG;
BO_TX_BU_ 497 :Gateway,Gateway_PAG;
BO_TX_BU_ 1424 :Gateway,Gateway_PAG;
BO_TX_BU_ 960 :BCM1,Gateway,Gateway_PAG;
BO_TX_BU_ 1420 :Gateway,Gateway_PAG;
BO_TX_BU_ 1646 :BCM1,Klima_MSB;
BO_TX_BU_ 1649 :BCM1,Klima_MSB;
BO_TX_BU_ 1608 :BCM1,Klima_MSB;
BO_TX_BU_ 949 :BCM1,Klima_MSB;
BO_TX_BU_ 1640 :BCM1,Klima_MSB;
BO_TX_BU_ 1441 :BCM1,Klima_MSB;
BO_TX_BU_ 2589283469 :BCM1,Klima_MSB;
CM_ BO_ 1340 "CAN-Botschaft";
CM_ BO_ 2527679583 "ehemals ZFAS_01";
CM_ BO_ 2549874818 "Lichtsteuerung links am Frontlicht-CAN";
CM_ BO_ 2550005890 "Lichtsteuerung links am Frontlicht-CAN";
CM_ BO_ 2549874819 "Lichtsteuerung rechts am Frontlicht-CAN";
CM_ BO_ 2550005891 "Lichtsteuerung rechts am Frontlicht-CAN";
CM_ BO_ 2549874838 "Lichtsteuerung links am Frontlicht-CAN";
CM_ BO_ 2550005910 "Lichtsteuerung links am Frontlicht-CAN";
CM_ BO_ 2549874839 "Lichtsteuerung rechts am Frontlicht-CAN";
CM_ BO_ 2550005911 "Lichtsteuerung rechts am Frontlicht-CAN";
CM_ BO_ 960 "MQB";
CM_ BO_ 1646 "ab MQB 7.3";
CM_ BO_ 1663 "Klima";
CM_ BO_ 949 "ab MQB 7.4";
CM_ BO_ 1640 "ab MQB IS-4";

CM_ SG_ 1381 HVLM_Freigabe_Lastabwurf "Für die PHEV’s 2.0 (ertüchtigtes HV-System für Emission/Reichweite) muss zur Reduzierung von Leistungsvorhalten eine Laständerung im HV-System erkannt und ausgeregelt werden:

Im Ladebetrieb muss eine negative Laständerung der Nebenverbraucher (z.B. Hei";
CM_ SG_ 1381 HVLM_FreigabeKlimatisierung "Klimatisierung freigeben";
CM_ SG_ 1381 HVLM_FreigabeTankdeckel "Tankdeckelfreigabe";
CM_ SG_ 1381 HVLM_HV_Abstellzeit "Zeitraum zwischen HV-Deaktiviert und HV-Aktiviert";
CM_ SG_ 1381 HVLM_IsoMessung_Anf "Signalisierung an den HVK, ob während des Ladens eine Iso-Messung durchgeführt werden muss.
0 = Laden mit Isomessung
1 = Laden ohne Isomessung";
CM_ SG_ 1381 HVLM_IstSpannung_HV "Ausgangsspannung des Ladegerätes und DC-Spannung der Ladesäule. Messung zwischen den DC HV-Leitungen. ";
CM_ SG_ 1381 HVLM_Ladesystemhinweise "Anzeigen von Hinweisen zum Ladesystem.
Anzeigen, dass das Ladesystem defekt ist.";
CM_ SG_ 1381 HVLM_Ladetexte "Anzeige, ob AC- oder DC-Laden nicht möglich ist";
CM_ SG_ 1381 HVLM_LG_Sollmodus "Sollmodus AC Ladegerät";
CM_ SG_ 1381 HVLM_MaxStrom_Netz "maximal zulässiger Strom auf Primärseite (AC) des Ladegerätes
Minima aus
Vorgabe z.B. über
- intelligente Kommunikation
- Control Pilot Duty Cycle
- Widerstandskodierung Kabel (Proximity)
- Vorgabe MMI, o.ä.";
CM_ SG_ 1381 HVLM_Schluessel_Anfrage "Anforderung HVLM an BCM für Schlüsselsuche über Kessy";
CM_ SG_ 1381 HVLM_Start_Spannungsmessung_DCLS "Meldung an das BMS, dass an der DC-Ladesäule eine Messspannung aufgeschaltet wird.";
CM_ SG_ 1381 HVLM_Stecker_Verriegeln "Anforderung Steckerverriegelung";
CM_ SG_ 1381 HVLM_Zustand_LED "Zustand der Lade-LED im Kombi und Dosenbeleuchtung";
CM_ SG_ 1381 PnC_Trigger_OBC_cGW "Trigger-Signal für die UDS-Kommunikation zwischen cGW und OBC für die Funktion Plug & Charge Online";

CM_ SG_ 1340 HVLM_04_BZ "Fortlaufender Botschaftszaehler";
CM_ SG_ 1340 HVLM_04_CRC "Für MLB:
'Berechnung siehe Lastenheft 'Kommunikationsabsicherung für FlexRay und CAN''

Ab MQB und MLBevo:
'Berechnung siehe Lastenheft 'End-to-End Kommunikationsabsicherung''

Endwerte siehe Begleitdokument 'S-PDU Kennungsfolgen'";
CM_ SG_ 1340 HVLM_Anf_Ladescreen "Anforderung für Ladescreen (BEV)";
CM_ SG_ 1340 HVLM_Anforderung_HMS "Anforderung zur Verriegelung des Triebstrangs";
CM_ SG_ 1340 HVLM_AWC_Sollmodus "Sollmodus AWC Ladegerät";
CM_ SG_ 1340 HVLM_Fehlerstatus "aktueller Fehlerstatus des Ladegerätes
";
CM_ SG_ 1340 HVLM_HV_Anf "HV-Aktivierung Anforderung und Grund der Anforderung";
CM_ SG_ 1340 HVLM_HVEM_MaxLeistung "Maximal zulässige Leistung, die das HVEM vom Lader nutzen darf. Wenn das Fzg nicht über einen Lader mit dem AC Netz verbunden ist ist dieser Wert 0.";
CM_ SG_ 1340 HVLM_IstModus_02 "aktueller Modus";
CM_ SG_ 1340 HVLM_LadeAnforderung "Mitteilung des Lademanagements an das MSG ob Stecker erkannt wurde, Laden gestartet, ein autonomer Betriebszustand aktiviert, eine Relaxing Phase für die Batterie angefordert werden soll";
CM_ SG_ 1340 HVLM_Ladeart "Anzeige, ob Strom in das Fzg. fließt und wofür er verwendet wird.";
CM_ SG_ 1340 HVLM_MaxBatLadestromHV "Empfohlener HV Batterieladestrom bei einer geplanten Ladung";
CM_ SG_ 1340 HVLM_Parken_beibehalten_HMS "Anforderung den Triebstrang verriegelt zu halten";
CM_ SG_ 1340 HVLM_Standklima_Timer_Status "Signalisierung an das KBT ob mind. ein Timer zur Standklimatisierung programmiert ist";
CM_ SG_ 1340 HVLM_Status_Netz "Information, ob das Fahrzeug mit einem Stromnetz verbunden ist.";
CM_ SG_ 1340 HVLM_Status_Tankklappe "Signal zeigt aktuellen Status der Tankklappe für FuelCellUnit an.";
CM_ SG_ 1340 HVLM_Stecker_Status "Status der Steckererkennung unabhängig vom Lademodus (AC oder DC)";
CM_ SG_ 1340 HVLM_STH_Betriebsmodus "Betriebsmodus der Standheizung für Vorkonditionierung und Timerklimatisierung";
CM_ SG_ 1340 HVLM_VK_Modus "Übermittlung des aktuellen Konditionierungs-Status für HMI, Mobile Online Dienste";
CM_ SG_ 1340 HVLM_VK_STH_Einsatz "Auswahl der PHEV Standheizung";

CM_ SG_ 2589283485 HVLM_BattKond_Anf "Anforderung Batteriekonditionierung";
CM_ SG_ 2589283485 HVLM_Dauer_Klima_02 "Dauer der Innenraumklimatisierung.";
CM_ SG_ 2589283485 HVLM_Funktion_Dauer_BattKond "Funktion Dauerkonditionierung HV-Batterie.";

CM_ SG_ 2463978610 HVLM_Ladeanzeige_Anf "Lichtmuster für Charge Check
Sendeart = On Change, Zykluszeit = 500ms, Inhibitzeit = 10ms anlog des Signals im MQB (HVLM_10) auf dem A CAN";
CM_ SG_ 2463978610 HVLM_Ladeanzeige_Intens_Front "aktuelle Helligkeit für die Anzeige des Ladestatus über Front-Fahrzeug-Lichtelemente ";
CM_ SG_ 2463978610 HVLM_Ladeanzeige_Intens_Heck "aktuelle Helligkeit für die Anzeige des Ladestatus über Heck-Fahrzeug-Lichtelemente";
CM_ SG_ 2463978610 HVLM_Ladeanzeige_Rampzeit "Zeit innerhalb der die gesendet Intensität für die Ladeanzeige erreicht werden soll";
CM_ SG_ 2463978610 HVLM_Ladeanzeige_Status "Funktionsstatus ChargeCheck
Sendeart = On Change, Zykluszeit = 500ms, Inhibitzeit = 10ms anlog des Signals im MQB (HVLM_10) auf dem A CAN";
CM_ SG_ 2463978610 HVLM_RtmWarnLadeKommunikation "RTM Warning of charging communction fault";
CM_ SG_ 2463978610 HVLM_RtmWarnLadestatus "RTM Warning of charging status fault";
CM_ SG_ 2463978610 HVLM_RtmWarnLadesystem "RTM Electrical machine CAN communication fault";
CM_ SG_ 2463978610 HVLM_RtmWarnLadeverbindung "RTM Charging connection fault";

CM_ SG_ 1524 AMB_Charisma_FahrPr "MLBevo: Aktuelles Fahrprogramm des Charisma-Teilnehmers (siehe Systemlastenheft Drive Select)
MQB: Istwert der Kennlinie (siehe Systemlastenheft MQB FPA)";
CM_ SG_ 1524 AMB_Charisma_Status "Systemstatus des Charismateilnehmers

Wert 0x3 ist nur für Fahrzeuge ab MQB relevant";
CM_ SG_ 1524 BCM1_DI_Rampe_Innenlicht "Dimmrampe Innenlicht";
CM_ SG_ 1524 BCM1_DI_Rampe_Leselicht "Dimmrampe Leselicht";
CM_ SG_ 1524 BCM1_Innenlicht_gedimmt_H "Steuerung von BCM_Innenlicht_H";
CM_ SG_ 1524 BCM1_Innenlicht_gedimmt_V "Steuerung von BCM_Innenlicht_V";
CM_ SG_ 1524 BCM1_Innenlicht_H "Anforderung Innenlicht hinten";
CM_ SG_ 1524 BCM1_Innenlicht_V "Anforderung Innenlicht vorne";
CM_ SG_ 1524 BCM1_Leselicht_Anf_hl " Leselicht hinten links Anforderung";
CM_ SG_ 1524 BCM1_Leselicht_Anf_hr "Leselicht hinten rechts Anforderung";
CM_ SG_ 1524 BCM1_Leselicht_Anf_vl "Leselicht vorne links Anforderung";
CM_ SG_ 1524 BCM1_Leselicht_Anf_vr "Leselicht vorne rechts Anforderung";
CM_ SG_ 1524 BCM1_Leuchten_Aus "Innenbeleuchtung ausschalten (keine Änderung / ausschalten)";
CM_ SG_ 1524 IL_Bel_BFS_Ausstieg "Einschalten der Ausstiegsleuchten oder Türwarnleuchten in Tür oder im Schweller";
CM_ SG_ 1524 IL_Bel_FS_Ausstieg "Einschalten der Ausstiegsleuchten oder Türwarnleuchten in Tür oder im Schweller";
CM_ SG_ 1524 IL_Bel_HBFS_Ausstieg "Einschalten der Ausstiegsleuchten oder Türwarnleuchten in Tür oder im Schweller";
CM_ SG_ 1524 IL_Bel_HFS_Ausstieg "Einschalten der Ausstiegsleuchten oder Türwarnleuchten in Tür oder im Schweller";
CM_ SG_ 1524 IL_Dimmung_H_Tuerkontur "Dimmung Türkontur hinten (bei Änderung im 30 ms Raster)";
CM_ SG_ 1524 IL_Dimmung_Lautspr "Dimmung Umfeldbeleuchtung an Türaußenseite oder Außenspiegel";
CM_ SG_ 1524 IL_Dimmung_Tuerinnengriff "Dimmung Türinnengriff";
CM_ SG_ 1524 IL_Dimmung_Umfeldbel "Dimmung Umfeldbeleuchtung an Türaußenseite oder Außenspiegel";
CM_ SG_ 1524 IL_Dimmung_V_Tuerkontur "Dimmung Türkontur vorne (bei Änderung im 30 ms Raster)";
CM_ SG_ 1524 IL_Innenlicht_aktiv "Status Innenlicht";
CM_ SG_ 1524 IL_Klemme_30G_aktiv "Synchrones Abschalten";

CM_ SG_ 312 IPA_01_BZ "Fehlende Beschreibung (Import)
Botschaft asynchron geroutet. Zählerwert kann springen.";
CM_ SG_ 312 IPA_01_CRC "Für MLB:
'Berechnung siehe Lastenheft 'Kommunikationsabsicherung für FlexRay und CAN''

Ab MQB und MLBevo:
'Berechnung siehe Lastenheft 'End-to-End Kommunikationsabsicherung''

Endwerte siehe Begleitdokument 'S-PDU Kennungsfolgen'";
CM_ SG_ 312 IPA_Anforderung_HMS "Anforderung vom IPA (Intelligent Park Assist) an das HMS (Haltemanagement System)";
CM_ SG_ 312 IPA_APS_LED "Ansteuerung der APS Funktions-LED durch das BCM.
0 = LED aus
1 = LED ein
2 = LED blinken
3 = Funktion gesperrt, LED aus
4 = frei
5 = frei
6 = Init
7 = frei";
CM_ SG_ 312 IPA_Fahrstufenwunsch "Flankengesteuerter Fahrstufenwunsch von IPA/PiloPa an das Getriebe";
CM_ SG_ 312 IPA_Parken_beibehalten_HMS "Anforderung seitens Pilotiertem Parken bzw. Manövrierassistent das Lösen der EPB bzw. das Auslegen der Parksperre zu blockieren";
CM_ SG_ 312 IPA_PLA_LED "Ansteuerung der PLA Funktions-LED durch das BCM.
0 = LED aus
1 = LED ein
2 = LED blinken
3 = Funktion gesperrt, LED aus
4 = frei
5 = frei
6 = Init
7 = frei";
CM_ SG_ 312 IPA_Sollbeschleunigung "Anforderung vom IPA an den TSK, das Fahrzeug zu beschleunigen.";
CM_ SG_ 312 IPA_Status "Zustand der IPA-Statusmaschine";
CM_ SG_ 312 IPA_Status_EDR "Statusinformation von IPA/PiloPa für EDR";
CM_ SG_ 312 IPA_Status_IPA_GE "Statusinformation von IPA/PiloPa für Handshakemechanismus mit dem Getriebe-SG";
CM_ SG_ 312 IPA_Status_IPA_TSK "Statusinformation vom IPA für Handshakemechanismus mit TSK";
CM_ SG_ 312 Parken_aktives_System "Das Signal zeigt an, welches der Parksysteme auf dem zFAS gerade aktiv ist.";
CM_ SG_ 312 Parken_erhoehtes_Moment "Anforderung einer spezifizierten Motormomenten-Rampe seitens IPA/PiloPa für das Überfahren einer Schwelle oder eines Bordsteins.";
CM_ SG_ 312 Parken_Fahrbereitschaft_Anf "Anforderung seitens iPA/pilotiertes Parken, die Fahrbereitschaft aufrecht zu erhalten und das Verlassenskonzept im MSG beim „automatischen Parkvorgang“ zu deaktivieren.";
CM_ SG_ 312 Parken_Motorlauf_Anf "Anforderung Motorlauf seitens PiloPa";

CM_ SG_ 2527679583 Parken_Aktivierungslicht_Anf "Anforderung des Aktivierungslichts nach erfolgreicher Aktivierungshandlung seitens Pilotiertem Parken.";
CM_ SG_ 2527679583 Parken_Bestaetigungsblinken_Anf "Anforderung seitens Pilotiertem Parken für ein Erfolgsblinken nach dem Erreichen der Zielposition bzw. für ein Abbruchsblinken bei Eintreten einer Abbruchsbedingung.";
CM_ SG_ 2527679583 Parken_Fahrbereitschaftlicht_Anf "Anforderung des Fahrbereitschaftslichts";
CM_ SG_ 2527679583 Parken_Fahrerhinweise_Anf "Anforderung zur erneuten Lampenaufprüfung und Anzeige von Warnhinweisen nach einem pilotierten Ausparkvorgang.";
CM_ SG_ 2527679583 Parken_Fahrtrichtungslicht_Anf "Anforderung seitens Pilotiertem Parken für die Anzeige der initialen Fahrtrichtung nach Systemaktivierung.";
CM_ SG_ 2527679583 Parken_FFB_LED_Anf "Statusinformation des Pilotierten Parkens für die Ansteuerung der LED auf der Funkfernbedienung.";
CM_ SG_ 2527679583 Parken_Lichtnachlauf_Anf "Anforderung des Lichtnachlaufs beim BCM1 (analog Verlassenskonzept) für das Pilotierte Parken. ";
CM_ SG_ 2527679583 Parken_Schluesselsuche_Anf "Ansteuerung der Schlüsselsuche für das pilotierte Parken.";
CM_ SG_ 2527679583 Parken_Seitenspiegel_Anf "Anforderung für Seitenspiegel an- oder abklappen beim PiloPa";
CM_ SG_ 2527679583 Parken_Wegfahrsperren_Anf "Ansteuerung der Wegfahrsperren Komponenten für das pilotierte Parken.  ";
CM_ SG_ 2527679583 Parken_ZR_Sondermodus_Anf "Anforderung Sondermodus, um beim „pilotierten Parken“ spezielle Funktionsanpassungen im Infotainment-Bereich zu ermöglichen (u.a. schnellerer Startup, Abschaltung BT)";
CM_ SG_ 2527679583 Parken_ZV_Schliessen "Anforderung für Zentralverriegelung verriegeln oder safen beim PiloPa";

CM_ SG_ 1806 ISO_BCM1_Req_Data "OffBoard Tester Diagnose Request BCM1";

CM_ SG_ 1912 ISO_BCM1_Resp_Data "OffBoard Tester Diagnose Response BCM1";

CM_ SG_ 1792 ISO_ALL_01_Req_Data "Funktionaler Request ALL";

CM_ SG_ 1862 ISO_Klima_Req_Data "Diagnose Request Klima Vorne";

CM_ SG_ 1968 ISO_Klima_Resp_Data "Diagnose Response Klima Vorne";

CM_ SG_ 1881 ISO_Lift_Req_Data "Diagnose Request Lift_VA";

CM_ SG_ 1987 ISO_Lift_Resp_Data "Diagnose Response Lift";

CM_ SG_ 2549874840 ISOx_DMD_L_Req_Data "OffBoard Tester Diagnose Request DMD_L";

CM_ SG_ 2550005912 ISOx_DMD_L_Resp_Data "OffBoard Tester Diagnose Response DMD_L";

CM_ SG_ 2549874841 ISOx_DMD_R_Req_Data "OffBoard Tester Diagnose Request DMD_R";

CM_ SG_ 2550005913 ISOx_DMD_R_Resp_Data "OffBoard Tester Diagnose Response DMD_R";

CM_ SG_ 2549874818 ISOx_LCM_L_Req_Data "Diagnose Request Light Control Module links";

CM_ SG_ 2550005890 ISOx_LCM_L_Resp_Data "OffBoard Tester Diagnose Response LCM_L";

CM_ SG_ 2549874819 ISOx_LCM_R_Req_Data "OffBoard Tester Diagnose Request LCM_R";

CM_ SG_ 2550005891 ISOx_LCM_R_Resp_Data "Diagnose Response Light Control Module rechts";

CM_ SG_ 2549874838 ISOx_LED_LM_L_Req_Data "Diagnose Resquest Steuergeraet für LED-Scheinwerfer links";

CM_ SG_ 2550005910 ISOx_LED_LM_L_Resp_Data "OffBoard Tester Diagnose Response LED_LM_L";

CM_ SG_ 2549874839 ISOx_LED_LM_R_Req_Data "Diagnose Request Steuergeraet für LED-Scheinwerfer rechts";

CM_ SG_ 2550005911 ISOx_LED_LM_R_Resp_Data "OffBoard Tester Diagnose Response LED_LM_R";

CM_ SG_ 2549874884 ISOx_VAS_L_Req_Data "OffBoard Tester Diagnose Request VAS_L";

CM_ SG_ 2550005956 ISOx_VAS_L_Resp_Data "OffBoard Tester Diagnose Response VAS_L";

CM_ SG_ 2549874885 ISOx_VAS_R_Req_Data "OffBoard Tester Diagnose Request VAS_R";

CM_ SG_ 2550005957 ISOx_VAS_R_Resp_Data "OffBoard Tester Diagnose Response VAS_R";

CM_ SG_ 2549874843 ISOx_zDML_Req_Data "OffBoard Tester Diagnose Request zDML";

CM_ SG_ 2550005915 ISOx_zDML_Resp_Data "OffBoard Tester Diagnose Response zDML";

CM_ SG_ 2463978614 KAS_Anf_Bremsruck "Anforderung Warnruck";
CM_ SG_ 2463978614 KAS_Anf_OPS "Anforderung des OPS durch den Kreuzungsassistenten";
CM_ SG_ 2463978614 KAS_Anf_Prefill "Anforderung Prefill";
CM_ SG_ 2463978614 KAS_Anzeige_Info_links "Anzeige für Inforelevantes Objekt links";
CM_ SG_ 2463978614 KAS_Anzeige_Info_rechts "Anzeige für Inforelevantes Objekt rechts";
CM_ SG_ 2463978614 KAS_Anzeige_Warnung "Anzeige der Warnung";
CM_ SG_ 2463978614 KAS_Kritikalitaetslevel "Mit dem Signal wird das Kritikalitätslevel der Funktion KA dargestellt. Je höher das Kritikalitätslevel ist, desto höher die Wahrscheinlichkeit einer Kollision mit Querverkehr.
wird auch befüllt wenn KA vor Kunde deaktiviert ist.

Benötigt zur Kommunik";
CM_ SG_ 2463978614 KAS_PreSense_Modus_System "Signal zur Realisierung der BAP-Kommunikation für PreSense";
CM_ SG_ 2463978614 KAS_Status "Statusausgabe der Funktion";
CM_ SG_ 2463978614 KAS_Texte "Anzeige der KAS Texte";
CM_ SG_ 2463978614 KAS_Verfuegbarkeit "Signal zur Realisierung der BAP-Kommunikation für PreSense.
Kommunikation des Kreuzungsassistent (zFAS) mit dem BAP-Koordinator (SC).

Damit wird die Verfügbarkeit der Funktion KA übermittelt, um vor Kunde die Verfügbarkeit mindestens einer Funktion de";
CM_ SG_ 2463978614 KAS_Verz_Anf "Verzögerungsanforderung von KAS an VZM";

CM_ SG_ 497 FBS_Aktivierung_Pilot_Parken "Aktivierung der Funktion pilotiertes Parken";
CM_ SG_ 497 FFB_FDF_Taste "FDF Taste am Funkschluessel";
CM_ SG_ 497 FFB_Joker_Taste "Frei konfigurierbare Taste auf der Funkfernbedienung (für Verdecktaste, UGDO Taste).
";
CM_ SG_ 497 FFB_Park_Taste "Parktaste Funkschluessel";
CM_ SG_ 497 FFB_Remotestart_Taste "Remotestart Taste Funkschluessel";
CM_ SG_ 497 KY_Auf_Taste "Auf-Taste Funkschluessel";
CM_ SG_ 497 KY_Bereich "Schlüsselentfernung für Funktionen Annäherungslicht, automatisches Entriegeln";
CM_ SG_ 497 KY_BT_Entriegelung_Autorisiert "Erkennung / Authorisierung Keyless BT
";
CM_ SG_ 497 KY_BT_Verriegelung_Autorisiert "Authorisierung Verriegelungssensor Keyless BT
";
CM_ SG_ 497 KY_EasyClose_Abbruch "ID-Geber während HD-Zufahrt im Nahbereich EasyClose erkannt";
CM_ SG_ 497 KY_EasyClose_Status "Signal zur LED Ansteuerung im HD-Verriegelungstaster für die Funktion EasyClose.";
CM_ SG_ 497 KY_Front_Entr_Autorisiert "Erkennung / Authorisierung Keyless Front";
CM_ SG_ 497 KY_Front_Verr_Autorisiert "Authorisierung Verriegelungssensor Keyless Front";
CM_ SG_ 497 KY_FT_Entriegelung_Autorisiert "Erkennung / Authorisierung Keyless FT
";
CM_ SG_ 497 KY_FT_Verriegelung_Autorisiert "Authorisierung Verriegelungssensor Keyless FT
";
CM_ SG_ 497 KY_HBFS_Entriegelung_Autorisiert "Erkennung / Authorisierung Keyless HBFS
";
CM_ SG_ 497 KY_HBFS_Verriegelung_Autorisiert "Authorisierung Verriegelungssensor Keyless HBFS


";
CM_ SG_ 497 KY_HD_Auffahrt "Auffahrt HD nach Wiedereintritt ID-Geber in EasyClose Nahbereich";
CM_ SG_ 497 KY_HD_Entriegelung_Autorisiert "Erkennung / Authorisierung Keyless Heck
";
CM_ SG_ 497 KY_HD_Verriegelung_Autorisiert "Autorisierung der Schließanforderung über Verriegelungsinnentaster";
CM_ SG_ 497 KY_HD_Zufahrt "Zufahrt HD nach erfolgreicher Funktion EasyClose";
CM_ SG_ 497 KY_HDF_Taste "HDF Taste am Funkschluessel";
CM_ SG_ 497 KY_HFS_Entriegelung_Autorisiert "Erkennung / Authorisierung Keyless HFS
";
CM_ SG_ 497 KY_HFS_Verriegelung_Autorisiert "Authorisierung Verriegelungssensor Keyless HFS

";
CM_ SG_ 497 KY_IDG_in_Reichweite "Für elektrisch betätigte Türen und Klappen muss für eine Betätigung über Funk eine Reichweitenbegrenzung eingeführt werden. Diese Bit zeigt an, dass sich der Funkschlüssel innerhalb der geforderten Reichweite befindet";
CM_ SG_ 497 KY_LKL_1_Autorisierung "Schlüsselstatus für Anfragen der Ladeklappe 1";
CM_ SG_ 497 KY_LKL_2_Autorisierung "Schlüsselstatus für Anfragen der Ladeklappe 2";
CM_ SG_ 497 KY_Panik_Taste "Panik Taste Funkschluessel";
CM_ SG_ 497 KY_Position "Schlüsselposition für Funktionen Annäherungslicht, automatisches Entriegeln";
CM_ SG_ 497 KY_Schluessel_im_Fzg "Zeigt einen erkannten Schlüssel im Fzg an.";
CM_ SG_ 497 KY_Zu_Taste "Zu-Taste Funkschluessel";
CM_ SG_ 497 KY_ZV_Signatur "Signatur der ZV";
CM_ SG_ 497 Schluesselnr_Personalisierung "Signal gibt die jewels aktuelle Schlüsselnummer für die Personalisierung wieder";

CM_ SG_ 1424 FBS_Warn_Schluessel_Batt "Kombi Prio Warnung Schluessel Batterie
'Bitte Schlüsselbatterie wechseln!'";
CM_ SG_ 1424 KST_Wegstrecke_Challenge "Wegstreckenchallenge ans Kombi und ESC";
CM_ SG_ 1424 KY_FFB_Frequenz "Frequenz FFB";
CM_ SG_ 1424 KY_Fzg_Verlassen_erkannt "Fahrer/Schlüssel hat das Fahrzeug verlassen und FT wurde geschlossen";
CM_ SG_ 1424 KY_Fzg_Zugang_erkannt "Fahrer/Schlüssel hat Fahrzeug betreten und die FT geschlossen";
CM_ SG_ 1424 KY_HF_Aktiv "HF Funkempfang
";
CM_ SG_ 1424 KY_Indikator_Mehrere_Schluessel "Indikator für u.a. Sitzmemory, dass sich mehr als ein Schlüssel im Fahrzeug befinden.";
CM_ SG_ 1424 KY_Keyless_Go_Verbau "Verbauinfo Keyless Go
";
CM_ SG_ 1424 KY_Keyless_Verbau "Verbauinfo Keyless 
";
CM_ SG_ 1424 KY_KYL_Fahrer_Hinweise "Kombi Fahrer Hinweise Keyless";
CM_ SG_ 1424 KY_LF_Aktiv "LF Schluesselkommunikation
";
CM_ SG_ 1424 KY_NFC_Fahrer_Hinweise "Kombi Fahrer Hinweise Keyless / NFC";
CM_ SG_ 1424 KY_StartStopp_Info "Stopp-Freigabe und Start-Anforderung an den Start-Stopp-Koordinator";
CM_ SG_ 1424 KY_Transponder_aktiv "Notspule bzw, Nottransponder wird angesteuert";
CM_ SG_ 1424 KYL_Warn_kein_Schluessel "Kombi Prio Warnung Keyless 
'Schlüssel nicht im Fahrzeug!'
";
CM_ SG_ 1424 KYL_Warn_Kessy_defekt "Kombi Prio Warnung Keyless
'Keyless Go defekt, Zündschloß benutzen'";
CM_ SG_ 1424 KYL_Warn_Notzuendschloss "Aufforderung an den Benutzer, den Schlüsssel an die Notspule zu halten, wenn Kessy den Schlüssel nicht finden kann
'Keyless Go defekt. Zum Starten den Schlüssel vor das Symbol halten!'";

CM_ SG_ 960 BCM_Ausparken_Betrieb "Anforderung zur erneuten Lampenaufprüfung und Anzeige von Warnhinweisen nach einem pilotierten Ausparkvorgang (Trigger: fallende Flanke)";
CM_ SG_ 960 BCM_Remotestart_Betrieb "Zeigt den Status des RemoteStarts an, d.h. KL15_RSt ist aktiviert und der Motorlauf ist im RSt-Betrieb aktiv.";
CM_ SG_ 960 BCM_Remotestart_KL15_Anf "Zeigt den Status der Aktivierung der KL15_RST durch das BCM an.";
CM_ SG_ 960 BCM_Remotestart_MO_Start "Nachdem das BCM die Remotestart MSG Freigabe sicher erkannt hat, fordert das BCM wiederum über dieses Signal vom MSG einen Motorstart durchzuführen.";
CM_ SG_ 960 Klemmen_Status_01_BZ "4bit Botschaftszaehler; wird in jeder Sendebotschaft inkrementiert";
CM_ SG_ 960 Klemmen_Status_01_CRC "Für MLB:
'Berechnung siehe Lastenheft 'Kommunikationsabsicherung für FlexRay und CAN''

Ab MQB und MLBevo:
'Berechnung siehe Lastenheft 'End-to-End Kommunikationsabsicherung''

Endwerte siehe Begleitdokument 'S-PDU Kennungsfolgen'";
CM_ SG_ 960 KST_Fahrerhinweis_1 "Signalisierung Fahrerhinweis 1 der Klemmensteuerung an das Kombi";
CM_ SG_ 960 KST_Fahrerhinweis_2 "Signalisierung Fahrerhinweis 2 der Klemmensteuerung an das Kombi";
CM_ SG_ 960 KST_Fahrerhinweis_4 "Signalisierung Fahrerhinweis 4 der Klemmensteuerung an das Kombi";
CM_ SG_ 960 KST_Fahrerhinweis_5 "Anzeigesignal für RemoteStart";
CM_ SG_ 960 KST_Fahrerhinweis_6 "Signal aktiviert die Kombi-Anzeigeinstrumente (Drehzahl, Tankinhalt, Kühlmitteltemperatur) während aktiviertem RemoteStart-Betrieb";
CM_ SG_ 960 KST_Warn_P1_ZST_def "Kombi Prio Warnung Klemmensteuerung 
Zündschloß defekt, Service aufsuchen!";
CM_ SG_ 960 KST_Warn_P2_ZST_def "Kombi Prio Warnung Klemmensteuerung
Zündschloß defekt!
";
CM_ SG_ 960 RSt_Fahrerhinweise "Über das Signal fordert das BCM Fahrerhinweise im Kombi für die Funktion RemoteStart an.";
CM_ SG_ 960 ZAS_Kl_15 "Klemme 15: Zuendung (SW-Kl.15)
";
CM_ SG_ 960 ZAS_Kl_50_Startanforderung "Klemme 50: Startwunsch Fahrer
";
CM_ SG_ 960 ZAS_Kl_Infotainment "Separate Klemmeninformation für das Infotainment. Signal entspricht im wesentlichen einer Klemme S Information, kann aber über einen Vor - bzw. Nachlauf zu Klemme S verfügen. 
Ein konkreter Anwendungsfall für einen Nachlauf ist die Abschaltung der Klemme";
CM_ SG_ 960 ZAS_Kl_S "Klemme S: S-Kontakt (Schluessel steckt)
";
CM_ SG_ 960 ZAS_Kl_X "Klemme 75
";

CM_ SG_ 1420 Klemmen_Steuerung_01_BZ "4bit Botschaftszaehler; wird in jeder Sendebotschaft inkrementiert";
CM_ SG_ 1420 Klemmen_Steuerung_01_CRC "Ab MQB und MLBevo:
'Berechnung siehe Lastenheft 'End-to-End Kommunikationsabsicherung''

Endwerte siehe Begleitdokument 'S-PDU Kennungsfolgen'";
CM_ SG_ 1420 KST_Anf_Klemmenfreigabe_ELV "Klemmensteuerung fordert Klemmen-Freigabe durch die ELV an.";
CM_ SG_ 1420 KST_Anf_ZV_Verriegelung "Neuer Verriegelungstrigger für die ZV nach der automatischen Klemmenabschaltung.

Wird bei Kessyfahrzeugen mit StartStop ein aktiver Stop-Mode und Fahrerverlassen erkannt, startet ein 30 Sekunden-Timer. Innerhalb dieser 30 Sekunden hat der Fahrer die Mö";
CM_ SG_ 1420 KST_aut_Abschaltung_Zuendung "Falls bei eingeschalteter Zündung das Abblendlicht aktiv war, muss nach der automatischen Abschaltung der Kl_15 & Kl_S, dass Standlicht aktiv bleiben. Das Signal sendet die Information, dass eine automatische Abschaltung der Kl_15 und Kl_S erfogt.";
CM_ SG_ 1420 KST_Txt_Komfortabschaltung "Dieses Signal fordert im Kombi die Meldung an, die den Fahrer über die ausgeführte automatische Zündungsabschaltung informiert. Signal wird für10s gesendet.";
CM_ SG_ 1420 KST_Txt_P_Gang "Text: 'Wählhebel in Position P bringen!'";
CM_ SG_ 1420 KST_Txt_Panikabschaltung "Text: 'Notabschaltung''";
CM_ SG_ 1420 KST_Unterdr_Zuendungsmeldung "Bei aktivem Signal soll die Zündungsmeldung durch das Kombi unterdrückt werden.";
CM_ SG_ 1420 KST_ZAT_betaetigt "Zündanlass-Taster (ZAT) betätigt";
CM_ SG_ 1420 Relais_VoKo_angesteuert "Signal zur Rückmeldung, ob das Relais für die Verbraucher von erweiterte Voko / RemoteStart angesteuert wird.";
CM_ SG_ 1420 RSt_Anforderung_HMS "Anforderung vom RSt (Remote Start) an das HMS (Haltemanagement System)";

CM_ SG_ 1646 KL_Anf_AussenspiegelHzg "Anforderung Außenspiegelheizung seitens Klimafunktion (z.B. bei Erweiterter VoKo)";
CM_ SG_ 1646 KL_BCmE_Livetip_Freigabe "Status der Klimaanlage. 
Zeigt an, ob der Livetip 'Fenster schließen wegen Ineffizienz Klimaanlage' sinvollerweise angezeigt werden soll";
CM_ SG_ 1646 KL_ErwVK_Anf "Erweiterte Voko angefordertert / aktiv";
CM_ SG_ 1646 KL_ErwVK_Zusatzrelais "Steuerung Zusatzrelais für Erweiterte Voko";
CM_ SG_ 1646 KL_FSH_Automatikbetrieb "Ermöglicht eine Unterscheidung von Anforderung FSH durch Kundenwunsch und Anforderung FSH durch Regelung des Klimasteuergeräts.
Das Signal liegt als Pegel an.";
CM_ SG_ 1646 KL_Geblaese_Fond_Status "Status Geblaese









";
CM_ SG_ 1646 KL_Geblaese_Status "Status Geblaese









";
CM_ SG_ 1646 KL_Heizkreisventilstellung "Bei MQB PHEV: Stellung Heizkreisventil Motor";
CM_ SG_ 1646 KL_HYB_ASV_hinten_schliessen_Anf "Anforderung der Klima an das BMS, das Absperrventil des Kältemittelkreislaufs zur Batteriekühlung zu schliessen";
CM_ SG_ 1646 KL_HYB_ASV_vorne_schliessen_Anf "Anforderung der Klima an das BMS, das Absperrventil des Kältemittelkreislaufs der Klimaanlage zu schliessen";
CM_ SG_ 1646 KL_I_Geblaese_Fond "Stromaufnahme Gebläse Heck";
CM_ SG_ 1646 KL_Innen_Temp "Innentemperatur

";
CM_ SG_ 1646 KL_Kompressorkupplung "Signal zur Aktivierung/Deaktivierung der Kompressorkupplung";
CM_ SG_ 1646 KL_Magnetventil "Anforderung des Bypassventils.";
CM_ SG_ 1646 KL_Restwaerme_aktiv "Signal zur Aktivierung/Deaktivierung der Wasserpumpe bei Restwärme; 
reduzierte IRÜ Empfindlichkeit";
CM_ SG_ 1646 KL_SIH_LEH_Verteilung_VL "Vom Kunden eingestellte Aufteilung der Heizleistung auf Sitzfläche und Lehnefläche für Sitz vorne links";
CM_ SG_ 1646 KL_SIH_LEH_Verteilung_VR "Vom Kunden eingestellte Aufteilung der Heizleistung auf Sitzfläche und Lehnefläche für Sitz vorne rechts";
CM_ SG_ 1646 KL_SIH_LEL_Verteilung_VL "Vom Kunden eingestellte Aufteilung der Lüftungsleistung auf Sitzfläche und Lehnenfläche für Sitz vorne links";
CM_ SG_ 1646 KL_SIH_LEL_Verteilung_VR "Vom Kunden eingestellte Aufteilung der Lüftungsleistung auf Sitzfläche und Lehnenfläche für Sitz vorne rechts";
CM_ SG_ 1646 KL_Solarluefter_aktiv "Betriebsstatus Solarluefter
";
CM_ SG_ 1646 KL_Status_Beduftung "Status der Beduftung";
CM_ SG_ 1646 KL_Status_Ionisator_Front "Status des Ionisator Front";
CM_ SG_ 1646 KL_STH_aktiv "Betriebsstatus Standheizung
";
CM_ SG_ 1646 KL_STH_Ansteuerung "Ansteuerung STH

";
CM_ SG_ 1646 KL_STH_Betriebsdauer "Betriebsdauer STH";
CM_ SG_ 1646 KL_STH_Timer_Status "Status des Standheizungstimers (für VW621 initial zur Übermittelung der Information von KlimaMSB zu Kombi)
Zur Anzeige im Kombi für 10 Sekunden nach Kl.15 aus;";
CM_ SG_ 1646 KL_STL_aktiv "Betriebsstatus Standlueftung
";
CM_ SG_ 1646 KL_Umluft_Taste "Betaetigung Umlufttaste
";
CM_ SG_ 1646 KL_WaPu "Ansteuerung der Standheizungswasserpumpe";

CM_ SG_ 1663 KL_Absperrventil_Fond "nur im D4 verwendet";
CM_ SG_ 1663 KL_Fond_li_reduziert "Vorhalt fuer VW, nicht B8";
CM_ SG_ 1663 KL_Fond_re_reduziert "Vorhalt fuer VW, nicht B8";
CM_ SG_ 1663 KL_Fondbed_vorne_aktiv "Fondbedienung von vorne
Im D4 nicht unterstützt    siehe Klima_07, Synchronisierunganforderung
";
CM_ SG_ 1663 KL_Gebl_Verst_Abs_Modus "Gebläseverstellung im Absolutmodus";
CM_ SG_ 1663 KL_Geblaesespg_Fond "Geläsespannung Fond";
CM_ SG_ 1663 KL_Heizverbraucher_aus "Signal ans Fondgerät, alle Heizverbraucher zu deaktivieren";
CM_ SG_ 1663 KL_Heizverbraucher_Notaus "Signal ans Fondgerät, alle Heizverbraucher zu deaktivieren";
CM_ SG_ 1663 KL_ICO2_Sensor_defekt "Funktionszustand vom CO2 Sensor";
CM_ SG_ 1663 KL_Mod_Display_li "Modus des Display links";
CM_ SG_ 1663 KL_Mod_Display_re "Modus des Display rechts
";
CM_ SG_ 1663 KL_SH_HL_Lastabschaltung "Abschaltung der Sitzheizung hinten links wegen BEM, auch Taktung möglich
";
CM_ SG_ 1663 KL_SH_HR_Lastabschaltung "Abschaltung der Sitzheizung hinten rechts wegen BEM, auch Taktung möglich
";
CM_ SG_ 1663 KL_Sollausblastemp_HL "Sollausblastemperatur hinten links (0°C .. 85°C)

Vorhalt";
CM_ SG_ 1663 KL_Sollausblastemp_HR "Sollausblastemperatur hinten rechts (0°C .. 85°C)

Vorhalt";
CM_ SG_ 1663 KL_Umluft "Sollwert für Umluftklappe Fondraum";

CM_ SG_ 1649 KL_Betriebsmodus_FH "Synchronisation des Betriebsmodus zwischen Front und Fond";
CM_ SG_ 1649 KL_Stopp_Wiederstart_Anz_01 "Dieses Signal gibt die detaillierte Begründung für eine Stoppverbot-/Wiederstartanfrage der Klima-SG an.";
CM_ SG_ 1649 KL_Stopp_Wiederstart_Anz_02 "Dieses Signal gibt die detaillierte Begründung für eine Stoppverbot-/Wiederstartanfrage der Klima-SG an.";
CM_ SG_ 1649 KL_Stopp_Wiederstart_Anz_03 "Dieses Signal gibt die detaillierte Begründung für eine Stoppverbot-/Wiederstartanfrage der Klima-SG an.";
CM_ SG_ 1649 KL_Stopp_Wiederstart_Anz_04 "Dieses Signal gibt die detaillierte Begründung für eine Stoppverbot-/Wiederstartanfrage der Klima-SG an.";
CM_ SG_ 1649 KL_Stopp_Wiederstart_Anz_05 "Dieses Signal gibt die detaillierte Begründung für eine Stoppverbot-/Wiederstartanfrage der Klima-SG an.";
CM_ SG_ 1649 KL_Stopp_Wiederstart_Anz_06 "Dieses Signal gibt die detaillierte Begründung für eine Stoppverbot-/Wiederstartanfrage der Klima-SG an.";
CM_ SG_ 1649 KL_Stopp_Wiederstart_Anz_07 "Dieses Signal gibt die detaillierte Begründung für eine Stoppverbot-/Wiederstartanfrage der Klima-SG an.";
CM_ SG_ 1649 KL_Stopp_Wiederstart_Anz_08 "Dieses Signal gibt die detaillierte Begründung für eine Stoppverbot-/Wiederstartanfrage der Klima-SG an.";
CM_ SG_ 1649 KL_Stopp_Wiederstart_Anz_09 "Dieses Signal gibt die detaillierte Begründung für eine Stoppverbot-/Wiederstartanfrage der Klima-SG an.";
CM_ SG_ 1649 KL_Stopp_Wiederstart_Anz_Std1 "Dieses Signal gibt die detaillierte Begründung für eine Stoppverbot-/Wiederstartanfrage der Klima-SG an.";
CM_ SG_ 1649 KL_Stopp_Wiederstart_Anz_Std2 "Dieses Signal gibt die detaillierte Begründung für eine Stoppverbot-/Wiederstartanfrage der Klima-SG an.";
CM_ SG_ 1649 KL_ZZ_Betriebsmodus "Betriebsdauerberechnung anhand Aussentemperaturauswertung mit Faktor 'ZZ_Betriebsmodus'";
CM_ SG_ 1649 KL_ZZ_Minute "Zielzeittimeranzeige im Display der Funkfernbedienung (Minute); Initwert ist der zuletzt gültige Wert";
CM_ SG_ 1649 KL_ZZ_Monat "Zielzeittimeranzeige im Display der Funkfernbedienung (Datum, Monat); Initwert ist der zuletzt gültige Wert";
CM_ SG_ 1649 KL_ZZ_Status_Timer "Timerstatusanzeige im Display der Funkfernbedienung (Timer aktiv/n.aktiv)";
CM_ SG_ 1649 KL_ZZ_Stunde "Zielzeittimeranzeige im Display der Funkfernbedienung (Stunde); Initwert ist der zuletzt gültige Wert";
CM_ SG_ 1649 KL_ZZ_Tag "Zielzeittimeranzeige im Display der Funkfernbedienung (Datum, Tag); Initwert ist der zuletzt gültige Wert";

CM_ SG_ 1608 KL_Befehlszaehler_FH "Befehlszähler zur Synchronisation Front & Fond";
CM_ SG_ 1608 KL_Luftmenge_HL_max "Vorgabe der maximal auswählbaren Gebläsestufe für Zone HL";
CM_ SG_ 1608 KL_Luftmenge_HL_offset "Abweichung der Gebläsespannung bei manueller Gebläsevorgabe zum Arbeitspunkt im Auto-Modus für Zone HL";
CM_ SG_ 1608 KL_Luftmenge_HL_Soll "Sollwertvorgabe für Luftmenge hinten links";
CM_ SG_ 1608 KL_Luftmenge_HR_max "Vorgabe der maximal auswählbaren Gebläsestufe für Zone HR";
CM_ SG_ 1608 KL_Luftmenge_HR_offset "Abweichung der Gebläsespannung bei manueller Gebläsevorgabe zum Arbeitspunkt im Auto-Modus für Zone HR";
CM_ SG_ 1608 KL_Luftmenge_HR_Soll "Sollwertvorgabe für Luftmenge hinten rechts";
CM_ SG_ 1608 KL_SH_HL_Soll "Sollwertvorgabe für Sitzheizung hinten links";
CM_ SG_ 1608 KL_SH_HR_Soll "Sollwertvorgabe für Sitzheizung hinten rechts";
CM_ SG_ 1608 KL_SL_HL_Soll "Sollwertvorgabe für Sitzlüftung hinten links";
CM_ SG_ 1608 KL_SL_HR_Soll "Sollwertvorgabe für Sitzlüftung hinten rechts";
CM_ SG_ 1608 KL_Temp_HL_Soll "Audi  bis   28°C
VW    bis   29,5°C";
CM_ SG_ 1608 KL_Temp_HR_Soll "Audi  bis   28°C
VW    bis   29,5°C";

CM_ SG_ 949 KL_AC_Schalter "AC Schalter
";
CM_ SG_ 949 KL_Anf_KL "Anforderung Kühlerlüfter der Klimaanlage in Prozent

";
CM_ SG_ 949 KL_Ausstattung_Klima "Austtattungsart der Klimabedienung";
CM_ SG_ 949 KL_Charisma_FahrPr "MLBevo: Aktuelles Fahrprogramm des Charisma-Teilnehmers (siehe Systemlastenheft Drive Select)
MQB: Istwert der Kennlinie (siehe Systemlastenheft MQB FPA)";
CM_ SG_ 949 KL_Charisma_Status "Charisma Systemstatus des Charisma-Teilnehmers

Wert 0x3 ist nur für Fahrzeuge ab MQB relevant";
CM_ SG_ 949 KL_Drehz_Anh "Drehzahlanhebung vom Motor angefordert

";
CM_ SG_ 949 KL_el_Zuheizer_Stufe "Vorgabe für Motorsteuergeraet PTC-Stufe; im MLB-B8 und MQB nur Stufe 0...3

";
CM_ SG_ 949 KL_Freilauf_Info "Freilauf Informationssignal von Klima zum Freilaufkoordinator. Klima kann über dieses Signal den Freilauf freigeben, verhindern bzw. explizit anfordern.";
CM_ SG_ 949 KL_Kompressorkupplung_linear "Sollwert zur Ansteuerung der Kompressorkupplung";
CM_ SG_ 949 KL_Last_Kompr "Aktuelles Verlustmoment der Klimaanlage bezogen auf die Kurbelwelle. Wird der Klimakompressor nicht angesteuert, ist das Schleppmoment bezogen auf die Kurbelwelle zu senden.";
CM_ SG_ 949 KL_nachtr_Stopp_Anf "Dieses Signal dient dem Motor als Trigger, dass ein nachträglicher Motorstopp eingeleitet werden kann, wenn es die Bedingungen des StSt Koordinators dies zulassen. ";
CM_ SG_ 949 KL_Spannungs_Anf "Forderung des Klima-SG's zur Spannungsanhebung.";
CM_ SG_ 949 KL_StartStopp_Info "Stopp-Freigabe und Start-Anforderung an den Start-Stopp-Koordinator";
CM_ SG_ 949 KL_T_Charge "Signal für Tastenbetätigung Charge-Taste (SOC Increasing)";
CM_ SG_ 949 KL_Thermomanagement "Stufen des Thermomanagements;
Bei Klemme 15 AUS und erkannten Timeout zum Klimabedienteil (z.B. Klimabedienteil während des Motorsteuergeräte-Kommunikations-Nachlaufs bereits im NM-Zustand ¿Bus Sleep¿)
erfolgt keine Ansteuerung der Wasserpumpe durch die";
CM_ SG_ 949 KL_Variante_Standheizung "Identifikation der Variante der Standheizungen zur Berechnung der energetischen Zielzeit";
CM_ SG_ 949 KL_Vorwarn_Komp_ein "Vorwarnung Kompressor ein; 140ms vorher; Information für Motor zum Aufbau Momentenreserve";
CM_ SG_ 949 KL_Vorwarn_Zuheizer_ein "Vorwarnung Zuheizerbetrieb
";
CM_ SG_ 949 KL_Zustand "Beschreibt den Zustand des Klima-/Heizungsbedienteils. (OFF-Mode Bedienteil)

PAG (MLB): Beschreibt den Zustand des Kompressors";

CM_ SG_ 1640 FSH_Taster "Tasterbetätigung Frontscheibenheizung
";
CM_ SG_ 1640 HSH_Taster "An-/Abforderung Heckscheibenheizung über spezielles Tastersignal
";
CM_ SG_ 1640 KL_Beschlagsgefahr "Beschlagsgefahr auf der Frontscheibe im Bereich des Spiegelfusses. Dient zur präventiven Ansteuerung der  Kamera-Scheibenheizung, um Kamera-Blindheit zu vermeiden
PHEV: volle Leistungsfreigabe 
HV Heizer und HV EKK bei Scheibenbeschlag ";
CM_ SG_ 1640 KL_Geblspng_Fond_Soll "Ausgabe des Sollwertes für die Spannung des Klimagebläsemotores hinten.






";
CM_ SG_ 1640 KL_Geblspng_Soll "Ausgabe des Sollwertes für die Spannung des Klimagebläsemotores vorne.







";
CM_ SG_ 1640 KL_I_Geblaese "Stromaufnahme Gebläse";
CM_ SG_ 1640 KL_Kompressorstrom_soll "Sollvorgabe Klima-Kompressorstrom";
CM_ SG_ 1640 KL_LRH_Stufe "Eingestellte Temperaturstufe der Lenkradheizung";
CM_ SG_ 1640 KL_LRH_Taster "Tasterbetätigung Lenkradheizung";
CM_ SG_ 1640 KL_PTC_Verbauinfo "Im Klima- bzw. Heizungsbedienteil wird der Verbau eines PTCs und dessen elektr. Leistungsklasse codiert";
CM_ SG_ 1640 KL_SIH_Soll_li "Einstellung Sitzheizung Fahrer (0...6)";
CM_ SG_ 1640 KL_SIH_Soll_re "Einstellung Sitzheizung Beifahrer (0...6)";
CM_ SG_ 1640 KL_SIL_Soll_li "Einstellung Sitzlüftung Fahrer (0...6)";
CM_ SG_ 1640 KL_SIL_Soll_re "Einstellung Sitzlüftung Beifahrer (0...6)";
CM_ SG_ 1640 KL_Umluftklappe_Status "Status Umluftklappe";
CM_ SG_ 1640 KL_Zuheizer_Freigabe "Freigabe Zuheizer
";
CM_ SG_ 1640 KRH_Soll_li "Ausgabe des Sollwertes für die Kopfraumheizung links.";
CM_ SG_ 1640 KRH_Soll_re "Ausgabe des Sollwertes für die Kopfraumheizung rechts.";

CM_ SG_ 1441 KL_Frischluftklappe_Status "Aktuelle Position der Frischluftklappe";
CM_ SG_ 1441 KL_PTC_linear_Anf "Kundenanforderung des PTC (linear)";
CM_ SG_ 1441 KL_SIH_LEH_Verteilung_HL "Vom Kunden eingestellte Aufteilung der Heizleistung auf Sitz und Lehne für Sitz hinten links";
CM_ SG_ 1441 KL_SIH_LEH_Verteilung_HR "Vom Kunden eingestellte Aufteilung der Heizleistung auf Sitz und Lehne für Sitz hinten rechts.";
CM_ SG_ 1441 KL_SIH_Stufe_hl "Eingestellte Sitzheizungsstufe hinten links für verteilte Komfortfunktionen";
CM_ SG_ 1441 KL_SIH_Stufe_hr "Eingestellte Sitzheizungsstufe hinten rechts für verteilte Komfortfunktionen";
CM_ SG_ 1441 KL_SIL_LEL_Verteilung_HL "Vom Kunden eingestellte Aufteilung der Lüftungsleistung auf Sitzfläche und Lehnenfläche für Sitz hinten links";
CM_ SG_ 1441 KL_SIL_LEL_Verteilung_HR "Vom Kunden eingestellte Aufteilung der Lüftungsleistung auf Sitzfläche und Lehnenfläche für Sitz hinten rechts";
CM_ SG_ 1441 KL_SIL_Stufe_hl "Eingestellte Sitzlüftungsstufe hinten links für verteilte Komfortfunktionen";
CM_ SG_ 1441 KL_SIL_Stufe_hr "Eingestellte Sitzlüftungsstufe hinten rechts für verteilte Komfortfunktionen";
CM_ SG_ 1441 KL_Temp_Soll_hl "Eingestellte Solltemperatur hinten links für verteilte Komfortfunktionen";
CM_ SG_ 1441 KL_Temp_Soll_hr "Eingestellte Solltemperatur hinten rechts für verteilte Komfortfunktionen";
CM_ SG_ 1441 KL_Temp_Soll_vl "Eingestellte Solltemperatur vorne links für verteilte Komfortfunktionen";
CM_ SG_ 1441 KL_Temp_Soll_vr "Eingestellte Solltemperatur vorne rechts für verteilte Komfortfunktionen";

CM_ SG_ 2589283469 KL_Geblaese_erw "Erwarteter Gebläsestatus im eingeschwungenen Zustand";
CM_ SG_ 2589283469 KL_Geblaese_Fond_erw "Erwarteter Fond-Gebläsestatus im eingeschwungenen Zustand";
CM_ SG_ 2589283469 KL_Heizlstg_Delta_Eingriff "Durch Kundeneingriff erwartete Veränderung der  Heizleistung bei aktuellen klimatischen Bedingungen";
CM_ SG_ 2589283469 KL_Kuehllstg_Delta_Eingriff "Durch Kundeneingriff erwartete Veränderung der  Kühlleistung bei aktuellen klimatischen Bedingungen";
CM_ SG_ 2589283469 KL_Tempklappe_Fond "Sollwert der Temperaturklappe Fond";
CM_ SG_ 2589283469 KL_Tempklappe_li "Sollwert der Temperaturklappe links (2 zonig)
Sollwert der Temperaturklappe (1-zonig)";
CM_ SG_ 2589283469 KL_Tempklappe_re "Sollwert der Temperaturklappe rechts";
CM_ SG_ 2589283469 KL_Verdampferleistung "Ist-Kühlleistung am Verdampfer
Bei KL_Verdampferleistung_Faktor = 1 wird der Signalwert mit dem Faktor 2 multipliziert.";
CM_ SG_ 2589283469 KL_Verdampferleistung_Faktor "Faktor für Signal KL_Verdampferleistung, 
Bei Signalwert 1 wird das Signal KL_Verdampferleistung mit dem Faktor 2 Multipliziert";
CM_ SG_ 2589283469 KL_VK_Anf "Starten einer Standklimatisierung ausgehend von der Climatronic Richtung Lademanagment.";
CM_ SG_ 2589283469 KL_Vorkond_Strategie "Strategie der Vorkonditionierung des Innenraums";
BA_DEF_REL_ BU_SG_REL_  "GenSigTimeoutTime" INT 0 65535;
BA_DEF_ BO_  "DiagRequest" ENUM "No", "Yes";
BA_DEF_ BO_  "DiagResponse" ENUM "No", "Yes";
BA_DEF_ BO_  "DiagState" ENUM "No", "Yes";
BA_DEF_ BO_  "GenMsgChkConstant" HEX 0 4095;
BA_DEF_ BO_  "GenMsgCycleTime" INT 0 65535;
BA_DEF_ BO_  "GenMsgCycleTimeFast" INT 0 65535;
BA_DEF_ BO_  "GenMsgDelayTime" INT 0 100000;
BA_DEF_ BO_  "GenMsgILSupport" ENUM "No", "Yes";
BA_DEF_ BO_  "GenMsgNrOfRepetition" INT 0 100;
BA_DEF_ BO_  "GenMsgPDUConstants" STRING;
BA_DEF_ BO_  "GenMsgSendType" ENUM "Cyclic", "not_used", "not_used", "not_used", "not_used", "not_used", "not_used", "IfActive", "NoMsgSendType";
BA_DEF_ BO_  "GenMsgStartDelayTime" INT 0 100000;
BA_DEF_ BO_  "NmMessage" ENUM "No", "Yes";
BA_DEF_ BO_  "NmhMessage" ENUM "No", "Yes";
BA_DEF_ BO_  "MsgType" ENUM "Application", "NM ", "NMH", "TP2.0", "ISO-TP ", "BAP", "EID", "KS", "XCP_PRE_CONFIGURED", "XCP_RUNTIME_CONFIGURED";
BA_DEF_ BO_  "VAGTP20_API" HEX 0 255;
BA_DEF_ BO_  "VAGTP20_DynConnection" ENUM "No", "Yes";
BA_DEF_ BO_  "VAGTP20_DynSetup" ENUM "No", "Yes";
BA_DEF_ BO_  "VAGTP20_StatConnection" ENUM "No", "Yes";
BA_DEF_ SG_  "GenSigActiveRepetitions" INT -2147483648 2147483647;
BA_DEF_ SG_  "GenSigInactiveValue" INT -2147483648 2147483647;
BA_DEF_ SG_  "GenSigSendType" ENUM "Cyclic", "OnWrite", "OnWriteWithRepetition", "OnChange", "OnChangeWithRepetition", "IfActive", "IfActiveWithRepetition", "NoSigSendType", "OnChangeAndIfActive", "OnChangeAndIfActiveWithRepetition";
BA_DEF_ SG_  "GenSigStartValue" INT -2147483648 2147483647;
BA_DEF_ SG_  "NWM-WakeupAllowed" ENUM "No", "Yes";
BA_DEF_ SG_  "GenSigFuncType" ENUM "NoFunction", "MsgCounter", "CRC-8", "XOR", "XOR-2", "DatedBit", "SW-Kl15", "CHK", "Constant", "Protocol", "CRC-8-SAE_J1850", "CRC-32", "DataLength", "DataID", "MsgCounter16", "SOK-Signatur", "Cluster";
BA_DEF_ SG_  "GenSigSwitchedByIgnition" ENUM "No", "Yes";
BA_DEF_ SG_  "Fehlerwert" HEX 0 2147483647;
BA_DEF_ SG_  "GenSigMissingSourceValue" HEX 0 2147483647;
BA_DEF_DEF_REL_  "GenSigTimeoutTime" 0;
BA_DEF_DEF_  "DiagRequest" "No";
BA_DEF_DEF_  "DiagResponse" "No";
BA_DEF_DEF_  "DiagState" "No";
BA_DEF_DEF_  "GenMsgChkConstant" 0;
BA_DEF_DEF_  "GenMsgCycleTime" 0;
BA_DEF_DEF_  "GenMsgCycleTimeFast" 0;
BA_DEF_DEF_  "GenMsgDelayTime" 0;
BA_DEF_DEF_  "GenMsgILSupport" "No";
BA_DEF_DEF_  "GenMsgNrOfRepetition" 0;
BA_DEF_DEF_  "GenMsgPDUConstants" "";
BA_DEF_DEF_  "GenMsgSendType" "NoMsgSendType";
BA_DEF_DEF_  "GenMsgStartDelayTime" 0;
BA_DEF_DEF_  "NmMessage" "No";
BA_DEF_DEF_  "NmhMessage" "No";
BA_DEF_DEF_  "MsgType" "Application";
BA_DEF_DEF_  "VAGTP20_API" 0;
BA_DEF_DEF_  "VAGTP20_DynConnection" "No";
BA_DEF_DEF_  "VAGTP20_DynSetup" "No";
BA_DEF_DEF_  "VAGTP20_StatConnection" "No";
BA_DEF_DEF_  "GenSigActiveRepetitions" 0;
BA_DEF_DEF_  "GenSigInactiveValue" 0;
BA_DEF_DEF_  "GenSigSendType" "NoSigSendType";
BA_DEF_DEF_  "GenSigStartValue" 0;
BA_DEF_DEF_  "NWM-WakeupAllowed" "No";
BA_DEF_DEF_  "GenSigFuncType" "NoFunction";
BA_DEF_DEF_  "GenSigSwitchedByIgnition" "Yes";
BA_DEF_DEF_  "Fehlerwert" 0;
BA_DEF_DEF_  "GenSigMissingSourceValue" 0;
BA_ "GenMsgCycleTime" BO_ 1381 100;
BA_ "GenMsgDelayTime" BO_ 1381 50;
BA_ "GenMsgILSupport" BO_ 1381 1;
BA_ "GenMsgSendType" BO_ 1381 0;
BA_ "GenMsgCycleTime" BO_ 1340 100;
BA_ "GenMsgILSupport" BO_ 1340 1;
BA_ "GenMsgPDUConstants" BO_ 1340 "0x8e,0xf9,0xe1,0x2e,0x83,0x34,0xd0,0xf1,0xaa,0x2c,0xbb,0x81,0x17,0x60,0x11,0x37";
BA_ "GenMsgSendType" BO_ 1340 0;
BA_ "GenMsgCycleTime" BO_ 2589283485 2000;
BA_ "GenMsgDelayTime" BO_ 2589283485 200;
BA_ "GenMsgILSupport" BO_ 2589283485 1;
BA_ "GenMsgSendType" BO_ 2589283485 0;
BA_ "GenMsgCycleTime" BO_ 2463978610 500;
BA_ "GenMsgDelayTime" BO_ 2463978610 10;
BA_ "GenMsgILSupport" BO_ 2463978610 1;
BA_ "GenMsgSendType" BO_ 2463978610 0;
BA_ "GenMsgCycleTime" BO_ 1524 500;
BA_ "GenMsgDelayTime" BO_ 1524 50;
BA_ "GenMsgILSupport" BO_ 1524 1;
BA_ "GenMsgSendType" BO_ 1524 0;
BA_ "GenMsgCycleTime" BO_ 312 200;
BA_ "GenMsgDelayTime" BO_ 312 20;
BA_ "GenMsgILSupport" BO_ 312 1;
BA_ "GenMsgPDUConstants" BO_ 312 "0x77,0x4e,0x14,0x87,0xf2,0xf8,0xb2,0x61,0xf6,0xa4,0x52,0x94,0xd4,0x81,0x2a,0xb1";
BA_ "GenMsgSendType" BO_ 312 0;
BA_ "GenMsgCycleTime" BO_ 2527679583 960;
BA_ "GenMsgCycleTimeFast" BO_ 2527679583 160;
BA_ "GenMsgDelayTime" BO_ 2527679583 80;
BA_ "GenMsgILSupport" BO_ 2527679583 1;
BA_ "GenMsgNrOfRepetition" BO_ 2527679583 5;
BA_ "GenMsgPDUConstants" BO_ 2527679583 "0xc6,0x7f,0x85,0xb6,0xe6,0xae,0xf8,0x26,0xb0,0x8c,0x19,0x10,0x5b,0x33,0x64,0x6c";
BA_ "GenMsgSendType" BO_ 2527679583 0;
BA_ "DiagRequest" BO_ 1806 1;
BA_ "MsgType" BO_ 1806 4;
BA_ "DiagResponse" BO_ 1912 1;
BA_ "MsgType" BO_ 1912 4;
BA_ "DiagState" BO_ 1792 1;
BA_ "MsgType" BO_ 1792 4;
BA_ "DiagRequest" BO_ 1862 1;
BA_ "MsgType" BO_ 1862 4;
BA_ "DiagResponse" BO_ 1968 1;
BA_ "MsgType" BO_ 1968 4;
BA_ "DiagRequest" BO_ 1881 1;
BA_ "MsgType" BO_ 1881 4;
BA_ "DiagResponse" BO_ 1987 1;
BA_ "MsgType" BO_ 1987 4;
BA_ "DiagRequest" BO_ 2549874840 1;
BA_ "MsgType" BO_ 2549874840 4;
BA_ "DiagResponse" BO_ 2550005912 1;
BA_ "MsgType" BO_ 2550005912 4;
BA_ "DiagRequest" BO_ 2549874841 1;
BA_ "MsgType" BO_ 2549874841 4;
BA_ "DiagResponse" BO_ 2550005913 1;
BA_ "MsgType" BO_ 2550005913 4;
BA_ "DiagRequest" BO_ 2549874818 1;
BA_ "MsgType" BO_ 2549874818 4;
BA_ "DiagResponse" BO_ 2550005890 1;
BA_ "MsgType" BO_ 2550005890 4;
BA_ "DiagRequest" BO_ 2549874819 1;
BA_ "MsgType" BO_ 2549874819 4;
BA_ "DiagResponse" BO_ 2550005891 1;
BA_ "MsgType" BO_ 2550005891 4;
BA_ "DiagRequest" BO_ 2549874838 1;
BA_ "MsgType" BO_ 2549874838 4;
BA_ "DiagResponse" BO_ 2550005910 1;
BA_ "MsgType" BO_ 2550005910 4;
BA_ "DiagRequest" BO_ 2549874839 1;
BA_ "MsgType" BO_ 2549874839 4;
BA_ "DiagResponse" BO_ 2550005911 1;
BA_ "MsgType" BO_ 2550005911 4;
BA_ "DiagRequest" BO_ 2549874884 1;
BA_ "MsgType" BO_ 2549874884 4;
BA_ "DiagResponse" BO_ 2550005956 1;
BA_ "MsgType" BO_ 2550005956 4;
BA_ "DiagRequest" BO_ 2549874885 1;
BA_ "MsgType" BO_ 2549874885 4;
BA_ "DiagResponse" BO_ 2550005957 1;
BA_ "MsgType" BO_ 2550005957 4;
BA_ "DiagRequest" BO_ 2549874843 1;
BA_ "MsgType" BO_ 2549874843 4;
BA_ "DiagResponse" BO_ 2550005915 1;
BA_ "MsgType" BO_ 2550005915 4;
BA_ "GenMsgCycleTime" BO_ 2463978614 200;
BA_ "GenMsgDelayTime" BO_ 2463978614 20;
BA_ "GenMsgILSupport" BO_ 2463978614 1;
BA_ "GenMsgSendType" BO_ 2463978614 0;
BA_ "GenMsgCycleTime" BO_ 497 500;
BA_ "GenMsgCycleTimeFast" BO_ 497 40;
BA_ "GenMsgDelayTime" BO_ 497 20;
BA_ "GenMsgILSupport" BO_ 497 1;
BA_ "GenMsgNrOfRepetition" BO_ 497 7;
BA_ "GenMsgSendType" BO_ 497 0;
BA_ "GenMsgCycleTime" BO_ 1424 200;
BA_ "GenMsgDelayTime" BO_ 1424 50;
BA_ "GenMsgILSupport" BO_ 1424 1;
BA_ "GenMsgSendType" BO_ 1424 0;
BA_ "GenMsgChkConstant" BO_ 960 195;
BA_ "GenMsgCycleTime" BO_ 960 100;
BA_ "GenMsgDelayTime" BO_ 960 10;
BA_ "GenMsgILSupport" BO_ 960 1;
BA_ "GenMsgPDUConstants" BO_ 960 "0xc3,0xc3,0xc3,0xc3,0xc3,0xc3,0xc3,0xc3,0xc3,0xc3,0xc3,0xc3,0xc3,0xc3,0xc3,0xc3";
BA_ "GenMsgSendType" BO_ 960 0;
BA_ "GenMsgCycleTime" BO_ 1420 1000;
BA_ "GenMsgCycleTimeFast" BO_ 1420 100;
BA_ "GenMsgDelayTime" BO_ 1420 50;
BA_ "GenMsgILSupport" BO_ 1420 1;
BA_ "GenMsgNrOfRepetition" BO_ 1420 3;
BA_ "GenMsgPDUConstants" BO_ 1420 "0x9b,0xb5,0x9d,0x06,0x01,0xe7,0x8f,0xc1,0xd0,0x10,0x47,0xe9,0xd3,0xca,0x05,0xf0";
BA_ "GenMsgSendType" BO_ 1420 0;
BA_ "GenMsgCycleTime" BO_ 1646 2000;
BA_ "GenMsgDelayTime" BO_ 1646 200;
BA_ "GenMsgILSupport" BO_ 1646 1;
BA_ "GenMsgSendType" BO_ 1646 0;
BA_ "GenMsgCycleTime" BO_ 1663 1000;
BA_ "GenMsgDelayTime" BO_ 1663 50;
BA_ "GenMsgILSupport" BO_ 1663 1;
BA_ "GenMsgSendType" BO_ 1663 0;
BA_ "GenMsgCycleTime" BO_ 1649 2000;
BA_ "GenMsgDelayTime" BO_ 1649 200;
BA_ "GenMsgILSupport" BO_ 1649 1;
BA_ "GenMsgSendType" BO_ 1649 0;
BA_ "GenMsgCycleTime" BO_ 1608 1000;
BA_ "GenMsgDelayTime" BO_ 1608 50;
BA_ "GenMsgILSupport" BO_ 1608 1;
BA_ "GenMsgSendType" BO_ 1608 0;
BA_ "GenMsgCycleTime" BO_ 949 100;
BA_ "GenMsgILSupport" BO_ 949 1;
BA_ "GenMsgSendType" BO_ 949 0;
BA_ "GenMsgCycleTime" BO_ 1640 200;
BA_ "GenMsgCycleTimeFast" BO_ 1640 100;
BA_ "GenMsgDelayTime" BO_ 1640 25;
BA_ "GenMsgILSupport" BO_ 1640 1;
BA_ "GenMsgNrOfRepetition" BO_ 1640 5;
BA_ "GenMsgSendType" BO_ 1640 0;
BA_ "GenMsgCycleTime" BO_ 1441 500;
BA_ "GenMsgILSupport" BO_ 1441 1;
BA_ "GenMsgSendType" BO_ 1441 0;
BA_ "GenMsgCycleTime" BO_ 2589283469 1000;
BA_ "GenMsgDelayTime" BO_ 2589283469 100;
BA_ "GenMsgILSupport" BO_ 2589283469 1;
BA_ "GenMsgSendType" BO_ 2589283469 0;
BA_ "GenSigSendType" SG_ 1381 HVLM_Freigabe_Lastabwurf 0;
BA_ "GenSigSwitchedByIgnition" SG_ 1381 HVLM_Freigabe_Lastabwurf 0;
BA_ "GenSigSendType" SG_ 1381 HVLM_FreigabeKlimatisierung 0;
BA_ "GenSigStartValue" SG_ 1381 HVLM_FreigabeKlimatisierung 2;
BA_ "GenSigSwitchedByIgnition" SG_ 1381 HVLM_FreigabeKlimatisierung 0;
BA_ "Fehlerwert" SG_ 1381 HVLM_FreigabeKlimatisierung 3;
BA_ "GenSigSendType" SG_ 1381 HVLM_FreigabeTankdeckel 3;
BA_ "GenSigStartValue" SG_ 1381 HVLM_FreigabeTankdeckel 2;
BA_ "GenSigSwitchedByIgnition" SG_ 1381 HVLM_FreigabeTankdeckel 0;
BA_ "Fehlerwert" SG_ 1381 HVLM_FreigabeTankdeckel 3;
BA_ "GenSigSendType" SG_ 1381 HVLM_HV_Abstellzeit 0;
BA_ "GenSigStartValue" SG_ 1381 HVLM_HV_Abstellzeit 254;
BA_ "GenSigSwitchedByIgnition" SG_ 1381 HVLM_HV_Abstellzeit 0;
BA_ "Fehlerwert" SG_ 1381 HVLM_HV_Abstellzeit 255;
BA_ "GenSigSendType" SG_ 1381 HVLM_IsoMessung_Anf 3;
BA_ "GenSigSwitchedByIgnition" SG_ 1381 HVLM_IsoMessung_Anf 0;
BA_ "GenSigSendType" SG_ 1381 HVLM_IstSpannung_HV 0;
BA_ "GenSigStartValue" SG_ 1381 HVLM_IstSpannung_HV 1022;
BA_ "GenSigSwitchedByIgnition" SG_ 1381 HVLM_IstSpannung_HV 0;
BA_ "Fehlerwert" SG_ 1381 HVLM_IstSpannung_HV 1023;
BA_ "GenSigSendType" SG_ 1381 HVLM_Ladesystemhinweise 0;
BA_ "GenSigSwitchedByIgnition" SG_ 1381 HVLM_Ladesystemhinweise 0;
BA_ "GenSigSendType" SG_ 1381 HVLM_Ladetexte 3;
BA_ "GenSigSwitchedByIgnition" SG_ 1381 HVLM_Ladetexte 0;
BA_ "GenSigSendType" SG_ 1381 HVLM_LG_Sollmodus 3;
BA_ "GenSigSwitchedByIgnition" SG_ 1381 HVLM_LG_Sollmodus 0;
BA_ "GenSigSendType" SG_ 1381 HVLM_MaxStrom_Netz 3;
BA_ "GenSigStartValue" SG_ 1381 HVLM_MaxStrom_Netz 126;
BA_ "GenSigSwitchedByIgnition" SG_ 1381 HVLM_MaxStrom_Netz 0;
BA_ "Fehlerwert" SG_ 1381 HVLM_MaxStrom_Netz 127;
BA_ "GenSigSendType" SG_ 1381 HVLM_Schluessel_Anfrage 3;
BA_ "GenSigSwitchedByIgnition" SG_ 1381 HVLM_Schluessel_Anfrage 0;
BA_ "GenSigSendType" SG_ 1381 HVLM_Start_Spannungsmessung_DCLS 3;
BA_ "GenSigSwitchedByIgnition" SG_ 1381 HVLM_Start_Spannungsmessung_DCLS 0;
BA_ "GenSigSendType" SG_ 1381 HVLM_Stecker_Verriegeln 3;
BA_ "GenSigStartValue" SG_ 1381 HVLM_Stecker_Verriegeln 2;
BA_ "GenSigSwitchedByIgnition" SG_ 1381 HVLM_Stecker_Verriegeln 0;
BA_ "GenSigSendType" SG_ 1381 HVLM_Zustand_LED 3;
BA_ "GenSigStartValue" SG_ 1381 HVLM_Zustand_LED 14;
BA_ "GenSigSwitchedByIgnition" SG_ 1381 HVLM_Zustand_LED 0;
BA_ "Fehlerwert" SG_ 1381 HVLM_Zustand_LED 15;
BA_ "GenSigSendType" SG_ 1381 PnC_Trigger_OBC_cGW 3;
BA_ "GenSigSwitchedByIgnition" SG_ 1381 PnC_Trigger_OBC_cGW 0;
BA_ "GenSigSendType" SG_ 1340 HVLM_04_BZ 0;
BA_ "GenSigFuncType" SG_ 1340 HVLM_04_BZ 1;
BA_ "GenSigSwitchedByIgnition" SG_ 1340 HVLM_04_BZ 0;
BA_ "GenSigSendType" SG_ 1340 HVLM_04_CRC 0;
BA_ "GenSigFuncType" SG_ 1340 HVLM_04_CRC 2;
BA_ "GenSigSwitchedByIgnition" SG_ 1340 HVLM_04_CRC 0;
BA_ "GenSigSendType" SG_ 1340 HVLM_Anf_Ladescreen 0;
BA_ "GenSigSwitchedByIgnition" SG_ 1340 HVLM_Anf_Ladescreen 0;
BA_ "GenSigSendType" SG_ 1340 HVLM_Anforderung_HMS 0;
BA_ "GenSigSwitchedByIgnition" SG_ 1340 HVLM_Anforderung_HMS 0;
BA_ "GenSigSendType" SG_ 1340 HVLM_AWC_Sollmodus 0;
BA_ "GenSigSwitchedByIgnition" SG_ 1340 HVLM_AWC_Sollmodus 0;
BA_ "Fehlerwert" SG_ 1340 HVLM_AWC_Sollmodus 7;
BA_ "GenSigSendType" SG_ 1340 HVLM_Fehlerstatus 0;
BA_ "GenSigStartValue" SG_ 1340 HVLM_Fehlerstatus 7;
BA_ "GenSigSwitchedByIgnition" SG_ 1340 HVLM_Fehlerstatus 0;
BA_ "GenSigSendType" SG_ 1340 HVLM_HV_Anf 0;
BA_ "GenSigSwitchedByIgnition" SG_ 1340 HVLM_HV_Anf 0;
BA_ "GenSigSendType" SG_ 1340 HVLM_HVEM_MaxLeistung 0;
BA_ "GenSigStartValue" SG_ 1340 HVLM_HVEM_MaxLeistung 510;
BA_ "GenSigSwitchedByIgnition" SG_ 1340 HVLM_HVEM_MaxLeistung 0;
BA_ "Fehlerwert" SG_ 1340 HVLM_HVEM_MaxLeistung 511;
BA_ "GenSigSendType" SG_ 1340 HVLM_IstModus_02 0;
BA_ "GenSigStartValue" SG_ 1340 HVLM_IstModus_02 2;
BA_ "GenSigSwitchedByIgnition" SG_ 1340 HVLM_IstModus_02 0;
BA_ "Fehlerwert" SG_ 1340 HVLM_IstModus_02 3;
BA_ "GenSigSendType" SG_ 1340 HVLM_LadeAnforderung 0;
BA_ "GenSigStartValue" SG_ 1340 HVLM_LadeAnforderung 6;
BA_ "GenSigSwitchedByIgnition" SG_ 1340 HVLM_LadeAnforderung 0;
BA_ "Fehlerwert" SG_ 1340 HVLM_LadeAnforderung 7;
BA_ "GenSigSendType" SG_ 1340 HVLM_Ladeart 0;
BA_ "GenSigSwitchedByIgnition" SG_ 1340 HVLM_Ladeart 0;
BA_ "GenSigSendType" SG_ 1340 HVLM_MaxBatLadestromHV 0;
BA_ "GenSigStartValue" SG_ 1340 HVLM_MaxBatLadestromHV 254;
BA_ "GenSigSwitchedByIgnition" SG_ 1340 HVLM_MaxBatLadestromHV 0;
BA_ "Fehlerwert" SG_ 1340 HVLM_MaxBatLadestromHV 255;
BA_ "GenSigSendType" SG_ 1340 HVLM_Parken_beibehalten_HMS 0;
BA_ "GenSigStartValue" SG_ 1340 HVLM_Parken_beibehalten_HMS 2;
BA_ "GenSigSwitchedByIgnition" SG_ 1340 HVLM_Parken_beibehalten_HMS 0;
BA_ "Fehlerwert" SG_ 1340 HVLM_Parken_beibehalten_HMS 3;
BA_ "GenSigSendType" SG_ 1340 HVLM_Standklima_Timer_Status 0;
BA_ "GenSigSwitchedByIgnition" SG_ 1340 HVLM_Standklima_Timer_Status 0;
BA_ "GenSigSendType" SG_ 1340 HVLM_Status_Netz 0;
BA_ "GenSigSwitchedByIgnition" SG_ 1340 HVLM_Status_Netz 0;
BA_ "GenSigSendType" SG_ 1340 HVLM_Status_Tankklappe 0;
BA_ "GenSigStartValue" SG_ 1340 HVLM_Status_Tankklappe 2;
BA_ "GenSigSwitchedByIgnition" SG_ 1340 HVLM_Status_Tankklappe 0;
BA_ "Fehlerwert" SG_ 1340 HVLM_Status_Tankklappe 3;
BA_ "GenSigSendType" SG_ 1340 HVLM_Stecker_Status 0;
BA_ "GenSigSwitchedByIgnition" SG_ 1340 HVLM_Stecker_Status 0;
BA_ "GenSigSendType" SG_ 1340 HVLM_STH_Betriebsmodus 0;
BA_ "GenSigStartValue" SG_ 1340 HVLM_STH_Betriebsmodus 6;
BA_ "GenSigSwitchedByIgnition" SG_ 1340 HVLM_STH_Betriebsmodus 0;
BA_ "Fehlerwert" SG_ 1340 HVLM_STH_Betriebsmodus 7;
BA_ "GenSigSendType" SG_ 1340 HVLM_VK_Modus 0;
BA_ "GenSigSwitchedByIgnition" SG_ 1340 HVLM_VK_Modus 0;
BA_ "Fehlerwert" SG_ 1340 HVLM_VK_Modus 3;
BA_ "GenSigSendType" SG_ 1340 HVLM_VK_STH_Einsatz 0;
BA_ "GenSigStartValue" SG_ 1340 HVLM_VK_STH_Einsatz 6;
BA_ "GenSigSwitchedByIgnition" SG_ 1340 HVLM_VK_STH_Einsatz 0;
BA_ "Fehlerwert" SG_ 1340 HVLM_VK_STH_Einsatz 7;
BA_ "GenSigSendType" SG_ 2589283485 HVLM_BattKond_Anf 3;
BA_ "GenSigStartValue" SG_ 2589283485 HVLM_BattKond_Anf 6;
BA_ "GenSigSwitchedByIgnition" SG_ 2589283485 HVLM_BattKond_Anf 0;
BA_ "Fehlerwert" SG_ 2589283485 HVLM_BattKond_Anf 7;
BA_ "GenSigSendType" SG_ 2589283485 HVLM_Dauer_Klima_02 3;
BA_ "GenSigStartValue" SG_ 2589283485 HVLM_Dauer_Klima_02 62;
BA_ "GenSigSwitchedByIgnition" SG_ 2589283485 HVLM_Dauer_Klima_02 0;
BA_ "Fehlerwert" SG_ 2589283485 HVLM_Dauer_Klima_02 63;
BA_ "GenSigSendType" SG_ 2589283485 HVLM_Funktion_Dauer_BattKond 0;
BA_ "GenSigSwitchedByIgnition" SG_ 2589283485 HVLM_Funktion_Dauer_BattKond 0;
BA_ "GenSigSendType" SG_ 2463978610 HVLM_Ladeanzeige_Anf 3;
BA_ "GenSigSwitchedByIgnition" SG_ 2463978610 HVLM_Ladeanzeige_Anf 0;
BA_ "GenSigSendType" SG_ 2463978610 HVLM_Ladeanzeige_Intens_Front 3;
BA_ "GenSigStartValue" SG_ 2463978610 HVLM_Ladeanzeige_Intens_Front 126;
BA_ "GenSigSwitchedByIgnition" SG_ 2463978610 HVLM_Ladeanzeige_Intens_Front 0;
BA_ "Fehlerwert" SG_ 2463978610 HVLM_Ladeanzeige_Intens_Front 127;
BA_ "GenSigSendType" SG_ 2463978610 HVLM_Ladeanzeige_Intens_Heck 3;
BA_ "GenSigStartValue" SG_ 2463978610 HVLM_Ladeanzeige_Intens_Heck 126;
BA_ "GenSigSwitchedByIgnition" SG_ 2463978610 HVLM_Ladeanzeige_Intens_Heck 0;
BA_ "Fehlerwert" SG_ 2463978610 HVLM_Ladeanzeige_Intens_Heck 127;
BA_ "GenSigSendType" SG_ 2463978610 HVLM_Ladeanzeige_Rampzeit 3;
BA_ "GenSigSwitchedByIgnition" SG_ 2463978610 HVLM_Ladeanzeige_Rampzeit 0;
BA_ "GenSigSendType" SG_ 2463978610 HVLM_Ladeanzeige_Status 3;
BA_ "GenSigSwitchedByIgnition" SG_ 2463978610 HVLM_Ladeanzeige_Status 0;
BA_ "GenSigSendType" SG_ 2463978610 HVLM_RtmWarnLadeKommunikation 3;
BA_ "GenSigSwitchedByIgnition" SG_ 2463978610 HVLM_RtmWarnLadeKommunikation 0;
BA_ "GenSigSendType" SG_ 2463978610 HVLM_RtmWarnLadestatus 3;
BA_ "GenSigSwitchedByIgnition" SG_ 2463978610 HVLM_RtmWarnLadestatus 0;
BA_ "GenSigSendType" SG_ 2463978610 HVLM_RtmWarnLadesystem 3;
BA_ "GenSigSwitchedByIgnition" SG_ 2463978610 HVLM_RtmWarnLadesystem 0;
BA_ "GenSigSendType" SG_ 2463978610 HVLM_RtmWarnLadeverbindung 3;
BA_ "GenSigSwitchedByIgnition" SG_ 2463978610 HVLM_RtmWarnLadeverbindung 0;
BA_ "GenSigSendType" SG_ 1524 AMB_Charisma_FahrPr 3;
BA_ "GenSigSwitchedByIgnition" SG_ 1524 AMB_Charisma_FahrPr 0;
BA_ "GenSigSendType" SG_ 1524 AMB_Charisma_Status 3;
BA_ "GenSigSwitchedByIgnition" SG_ 1524 AMB_Charisma_Status 0;
BA_ "GenSigSendType" SG_ 1524 BCM1_DI_Rampe_Innenlicht 3;
BA_ "GenSigSwitchedByIgnition" SG_ 1524 BCM1_DI_Rampe_Innenlicht 0;
BA_ "GenSigSendType" SG_ 1524 BCM1_DI_Rampe_Leselicht 3;
BA_ "GenSigSwitchedByIgnition" SG_ 1524 BCM1_DI_Rampe_Leselicht 0;
BA_ "GenSigSendType" SG_ 1524 BCM1_Innenlicht_gedimmt_H 3;
BA_ "GenSigSwitchedByIgnition" SG_ 1524 BCM1_Innenlicht_gedimmt_H 0;
BA_ "GenSigSendType" SG_ 1524 BCM1_Innenlicht_gedimmt_V 3;
BA_ "GenSigSwitchedByIgnition" SG_ 1524 BCM1_Innenlicht_gedimmt_V 0;
BA_ "GenSigSendType" SG_ 1524 BCM1_Innenlicht_H 3;
BA_ "GenSigSwitchedByIgnition" SG_ 1524 BCM1_Innenlicht_H 0;
BA_ "GenSigSendType" SG_ 1524 BCM1_Innenlicht_V 3;
BA_ "GenSigSwitchedByIgnition" SG_ 1524 BCM1_Innenlicht_V 0;
BA_ "GenSigSendType" SG_ 1524 BCM1_Leselicht_Anf_hl 3;
BA_ "GenSigSwitchedByIgnition" SG_ 1524 BCM1_Leselicht_Anf_hl 0;
BA_ "GenSigSendType" SG_ 1524 BCM1_Leselicht_Anf_hr 3;
BA_ "GenSigSwitchedByIgnition" SG_ 1524 BCM1_Leselicht_Anf_hr 0;
BA_ "GenSigSendType" SG_ 1524 BCM1_Leselicht_Anf_vl 3;
BA_ "GenSigSwitchedByIgnition" SG_ 1524 BCM1_Leselicht_Anf_vl 0;
BA_ "GenSigSendType" SG_ 1524 BCM1_Leselicht_Anf_vr 3;
BA_ "GenSigSwitchedByIgnition" SG_ 1524 BCM1_Leselicht_Anf_vr 0;
BA_ "GenSigSendType" SG_ 1524 BCM1_Leuchten_Aus 3;
BA_ "GenSigSwitchedByIgnition" SG_ 1524 BCM1_Leuchten_Aus 0;
BA_ "GenSigSendType" SG_ 1524 IL_Bel_BFS_Ausstieg 3;
BA_ "GenSigSwitchedByIgnition" SG_ 1524 IL_Bel_BFS_Ausstieg 0;
BA_ "GenSigSendType" SG_ 1524 IL_Bel_FS_Ausstieg 3;
BA_ "GenSigSwitchedByIgnition" SG_ 1524 IL_Bel_FS_Ausstieg 0;
BA_ "GenSigSendType" SG_ 1524 IL_Bel_HBFS_Ausstieg 3;
BA_ "GenSigSwitchedByIgnition" SG_ 1524 IL_Bel_HBFS_Ausstieg 0;
BA_ "GenSigSendType" SG_ 1524 IL_Bel_HFS_Ausstieg 3;
BA_ "GenSigSwitchedByIgnition" SG_ 1524 IL_Bel_HFS_Ausstieg 0;
BA_ "GenSigSendType" SG_ 1524 IL_Dimmung_H_Tuerkontur 3;
BA_ "GenSigSwitchedByIgnition" SG_ 1524 IL_Dimmung_H_Tuerkontur 0;
BA_ "GenSigSendType" SG_ 1524 IL_Dimmung_Lautspr 3;
BA_ "GenSigSwitchedByIgnition" SG_ 1524 IL_Dimmung_Lautspr 0;
BA_ "GenSigSendType" SG_ 1524 IL_Dimmung_Tuerinnengriff 3;
BA_ "GenSigSwitchedByIgnition" SG_ 1524 IL_Dimmung_Tuerinnengriff 0;
BA_ "GenSigSendType" SG_ 1524 IL_Dimmung_Umfeldbel 3;
BA_ "GenSigSwitchedByIgnition" SG_ 1524 IL_Dimmung_Umfeldbel 0;
BA_ "GenSigSendType" SG_ 1524 IL_Dimmung_V_Tuerkontur 3;
BA_ "GenSigSwitchedByIgnition" SG_ 1524 IL_Dimmung_V_Tuerkontur 0;
BA_ "GenSigSendType" SG_ 1524 IL_Innenlicht_aktiv 3;
BA_ "GenSigStartValue" SG_ 1524 IL_Innenlicht_aktiv 1;
BA_ "GenSigSwitchedByIgnition" SG_ 1524 IL_Innenlicht_aktiv 0;
BA_ "GenSigSendType" SG_ 1524 IL_Klemme_30G_aktiv 3;
BA_ "GenSigSwitchedByIgnition" SG_ 1524 IL_Klemme_30G_aktiv 0;
BA_ "GenSigSendType" SG_ 312 IPA_01_BZ 0;
BA_ "GenSigFuncType" SG_ 312 IPA_01_BZ 1;
BA_ "GenSigSwitchedByIgnition" SG_ 312 IPA_01_BZ 0;
BA_ "GenSigSendType" SG_ 312 IPA_01_CRC 0;
BA_ "GenSigFuncType" SG_ 312 IPA_01_CRC 2;
BA_ "GenSigSwitchedByIgnition" SG_ 312 IPA_01_CRC 0;
BA_ "GenSigSendType" SG_ 312 IPA_Anforderung_HMS 0;
BA_ "GenSigSwitchedByIgnition" SG_ 312 IPA_Anforderung_HMS 0;
BA_ "GenSigSendType" SG_ 312 IPA_APS_LED 3;
BA_ "GenSigStartValue" SG_ 312 IPA_APS_LED 6;
BA_ "GenSigSendType" SG_ 312 IPA_Fahrstufenwunsch 0;
BA_ "GenSigSendType" SG_ 312 IPA_Parken_beibehalten_HMS 0;
BA_ "GenSigStartValue" SG_ 312 IPA_Parken_beibehalten_HMS 2;
BA_ "Fehlerwert" SG_ 312 IPA_Parken_beibehalten_HMS 3;
BA_ "GenSigSendType" SG_ 312 IPA_PLA_LED 3;
BA_ "GenSigStartValue" SG_ 312 IPA_PLA_LED 6;
BA_ "GenSigSendType" SG_ 312 IPA_Sollbeschleunigung 0;
BA_ "GenSigSendType" SG_ 312 IPA_Status 3;
BA_ "GenSigSwitchedByIgnition" SG_ 312 IPA_Status 0;
BA_ "GenSigSendType" SG_ 312 IPA_Status_EDR 3;
BA_ "GenSigStartValue" SG_ 312 IPA_Status_EDR 1;
BA_ "GenSigSwitchedByIgnition" SG_ 312 IPA_Status_EDR 0;
BA_ "GenSigSendType" SG_ 312 IPA_Status_IPA_GE 0;
BA_ "Fehlerwert" SG_ 312 IPA_Status_IPA_GE 7;
BA_ "GenSigSendType" SG_ 312 IPA_Status_IPA_TSK 3;
BA_ "GenSigStartValue" SG_ 312 IPA_Status_IPA_TSK 1;
BA_ "GenSigSendType" SG_ 312 Parken_aktives_System 3;
BA_ "GenSigSendType" SG_ 312 Parken_erhoehtes_Moment 0;
BA_ "GenSigSwitchedByIgnition" SG_ 312 Parken_erhoehtes_Moment 0;
BA_ "GenSigSendType" SG_ 312 Parken_Fahrbereitschaft_Anf 3;
BA_ "GenSigSendType" SG_ 312 Parken_Motorlauf_Anf 3;
BA_ "GenSigActiveRepetitions" SG_ 2527679583 Parken_Aktivierungslicht_Anf 5;
BA_ "GenSigSendType" SG_ 2527679583 Parken_Aktivierungslicht_Anf 4;
BA_ "GenSigSwitchedByIgnition" SG_ 2527679583 Parken_Aktivierungslicht_Anf 0;
BA_ "GenSigActiveRepetitions" SG_ 2527679583 Parken_Bestaetigungsblinken_Anf 5;
BA_ "GenSigSendType" SG_ 2527679583 Parken_Bestaetigungsblinken_Anf 4;
BA_ "GenSigSwitchedByIgnition" SG_ 2527679583 Parken_Bestaetigungsblinken_Anf 0;
BA_ "GenSigActiveRepetitions" SG_ 2527679583 Parken_Fahrbereitschaftlicht_Anf 5;
BA_ "GenSigSendType" SG_ 2527679583 Parken_Fahrbereitschaftlicht_Anf 4;
BA_ "GenSigActiveRepetitions" SG_ 2527679583 Parken_Fahrerhinweise_Anf 5;
BA_ "GenSigSendType" SG_ 2527679583 Parken_Fahrerhinweise_Anf 4;
BA_ "GenSigSwitchedByIgnition" SG_ 2527679583 Parken_Fahrerhinweise_Anf 0;
BA_ "GenSigActiveRepetitions" SG_ 2527679583 Parken_Fahrtrichtungslicht_Anf 5;
BA_ "GenSigSendType" SG_ 2527679583 Parken_Fahrtrichtungslicht_Anf 4;
BA_ "GenSigActiveRepetitions" SG_ 2527679583 Parken_FFB_LED_Anf 5;
BA_ "GenSigSendType" SG_ 2527679583 Parken_FFB_LED_Anf 4;
BA_ "GenSigActiveRepetitions" SG_ 2527679583 Parken_Lichtnachlauf_Anf 5;
BA_ "GenSigSendType" SG_ 2527679583 Parken_Lichtnachlauf_Anf 4;
BA_ "GenSigActiveRepetitions" SG_ 2527679583 Parken_Schluesselsuche_Anf 5;
BA_ "GenSigSendType" SG_ 2527679583 Parken_Schluesselsuche_Anf 4;
BA_ "GenSigActiveRepetitions" SG_ 2527679583 Parken_Seitenspiegel_Anf 5;
BA_ "GenSigSendType" SG_ 2527679583 Parken_Seitenspiegel_Anf 4;
BA_ "GenSigActiveRepetitions" SG_ 2527679583 Parken_Wegfahrsperren_Anf 5;
BA_ "GenSigSendType" SG_ 2527679583 Parken_Wegfahrsperren_Anf 4;
BA_ "GenSigActiveRepetitions" SG_ 2527679583 Parken_ZR_Sondermodus_Anf 5;
BA_ "GenSigSendType" SG_ 2527679583 Parken_ZR_Sondermodus_Anf 4;
BA_ "GenSigSwitchedByIgnition" SG_ 2527679583 Parken_ZR_Sondermodus_Anf 0;
BA_ "GenSigActiveRepetitions" SG_ 2527679583 Parken_ZV_Schliessen 5;
BA_ "GenSigSendType" SG_ 2527679583 Parken_ZV_Schliessen 4;
BA_ "GenSigSendType" SG_ 1806 ISO_BCM1_Req_Data 3;
BA_ "GenSigFuncType" SG_ 1806 ISO_BCM1_Req_Data 9;
BA_ "GenSigSwitchedByIgnition" SG_ 1806 ISO_BCM1_Req_Data 0;
BA_ "GenSigSendType" SG_ 1912 ISO_BCM1_Resp_Data 3;
BA_ "GenSigFuncType" SG_ 1912 ISO_BCM1_Resp_Data 9;
BA_ "GenSigSwitchedByIgnition" SG_ 1912 ISO_BCM1_Resp_Data 0;
BA_ "GenSigSendType" SG_ 1792 ISO_ALL_01_Req_Data 3;
BA_ "GenSigFuncType" SG_ 1792 ISO_ALL_01_Req_Data 9;
BA_ "GenSigSwitchedByIgnition" SG_ 1792 ISO_ALL_01_Req_Data 0;
BA_ "GenSigSendType" SG_ 1862 ISO_Klima_Req_Data 3;
BA_ "GenSigFuncType" SG_ 1862 ISO_Klima_Req_Data 9;
BA_ "GenSigSwitchedByIgnition" SG_ 1862 ISO_Klima_Req_Data 0;
BA_ "GenSigSendType" SG_ 1968 ISO_Klima_Resp_Data 3;
BA_ "GenSigFuncType" SG_ 1968 ISO_Klima_Resp_Data 9;
BA_ "GenSigSwitchedByIgnition" SG_ 1968 ISO_Klima_Resp_Data 0;
BA_ "GenSigSendType" SG_ 1881 ISO_Lift_Req_Data 3;
BA_ "GenSigFuncType" SG_ 1881 ISO_Lift_Req_Data 9;
BA_ "GenSigSwitchedByIgnition" SG_ 1881 ISO_Lift_Req_Data 0;
BA_ "GenSigSendType" SG_ 1987 ISO_Lift_Resp_Data 3;
BA_ "GenSigFuncType" SG_ 1987 ISO_Lift_Resp_Data 9;
BA_ "GenSigSwitchedByIgnition" SG_ 1987 ISO_Lift_Resp_Data 0;
BA_ "GenSigSendType" SG_ 2549874840 ISOx_DMD_L_Req_Data 3;
BA_ "GenSigFuncType" SG_ 2549874840 ISOx_DMD_L_Req_Data 9;
BA_ "GenSigSwitchedByIgnition" SG_ 2549874840 ISOx_DMD_L_Req_Data 0;
BA_ "GenSigSendType" SG_ 2550005912 ISOx_DMD_L_Resp_Data 3;
BA_ "GenSigFuncType" SG_ 2550005912 ISOx_DMD_L_Resp_Data 9;
BA_ "GenSigSwitchedByIgnition" SG_ 2550005912 ISOx_DMD_L_Resp_Data 0;
BA_ "GenSigSendType" SG_ 2549874841 ISOx_DMD_R_Req_Data 3;
BA_ "GenSigFuncType" SG_ 2549874841 ISOx_DMD_R_Req_Data 9;
BA_ "GenSigSwitchedByIgnition" SG_ 2549874841 ISOx_DMD_R_Req_Data 0;
BA_ "GenSigSendType" SG_ 2550005913 ISOx_DMD_R_Resp_Data 3;
BA_ "GenSigFuncType" SG_ 2550005913 ISOx_DMD_R_Resp_Data 9;
BA_ "GenSigSwitchedByIgnition" SG_ 2550005913 ISOx_DMD_R_Resp_Data 0;
BA_ "GenSigSendType" SG_ 2549874818 ISOx_LCM_L_Req_Data 3;
BA_ "GenSigFuncType" SG_ 2549874818 ISOx_LCM_L_Req_Data 9;
BA_ "GenSigSwitchedByIgnition" SG_ 2549874818 ISOx_LCM_L_Req_Data 0;
BA_ "GenSigSendType" SG_ 2550005890 ISOx_LCM_L_Resp_Data 3;
BA_ "GenSigFuncType" SG_ 2550005890 ISOx_LCM_L_Resp_Data 9;
BA_ "GenSigSwitchedByIgnition" SG_ 2550005890 ISOx_LCM_L_Resp_Data 0;
BA_ "GenSigSendType" SG_ 2549874819 ISOx_LCM_R_Req_Data 3;
BA_ "GenSigFuncType" SG_ 2549874819 ISOx_LCM_R_Req_Data 9;
BA_ "GenSigSwitchedByIgnition" SG_ 2549874819 ISOx_LCM_R_Req_Data 0;
BA_ "GenSigSendType" SG_ 2550005891 ISOx_LCM_R_Resp_Data 3;
BA_ "GenSigFuncType" SG_ 2550005891 ISOx_LCM_R_Resp_Data 9;
BA_ "GenSigSwitchedByIgnition" SG_ 2550005891 ISOx_LCM_R_Resp_Data 0;
BA_ "GenSigSendType" SG_ 2549874838 ISOx_LED_LM_L_Req_Data 3;
BA_ "GenSigFuncType" SG_ 2549874838 ISOx_LED_LM_L_Req_Data 9;
BA_ "GenSigSwitchedByIgnition" SG_ 2549874838 ISOx_LED_LM_L_Req_Data 0;
BA_ "GenSigSendType" SG_ 2550005910 ISOx_LED_LM_L_Resp_Data 3;
BA_ "GenSigFuncType" SG_ 2550005910 ISOx_LED_LM_L_Resp_Data 9;
BA_ "GenSigSwitchedByIgnition" SG_ 2550005910 ISOx_LED_LM_L_Resp_Data 0;
BA_ "GenSigSendType" SG_ 2549874839 ISOx_LED_LM_R_Req_Data 3;
BA_ "GenSigFuncType" SG_ 2549874839 ISOx_LED_LM_R_Req_Data 9;
BA_ "GenSigSwitchedByIgnition" SG_ 2549874839 ISOx_LED_LM_R_Req_Data 0;
BA_ "GenSigSendType" SG_ 2550005911 ISOx_LED_LM_R_Resp_Data 3;
BA_ "GenSigFuncType" SG_ 2550005911 ISOx_LED_LM_R_Resp_Data 9;
BA_ "GenSigSwitchedByIgnition" SG_ 2550005911 ISOx_LED_LM_R_Resp_Data 0;
BA_ "GenSigSendType" SG_ 2549874884 ISOx_VAS_L_Req_Data 3;
BA_ "GenSigFuncType" SG_ 2549874884 ISOx_VAS_L_Req_Data 9;
BA_ "GenSigSwitchedByIgnition" SG_ 2549874884 ISOx_VAS_L_Req_Data 0;
BA_ "GenSigSendType" SG_ 2550005956 ISOx_VAS_L_Resp_Data 3;
BA_ "GenSigFuncType" SG_ 2550005956 ISOx_VAS_L_Resp_Data 9;
BA_ "GenSigSwitchedByIgnition" SG_ 2550005956 ISOx_VAS_L_Resp_Data 0;
BA_ "GenSigSendType" SG_ 2549874885 ISOx_VAS_R_Req_Data 3;
BA_ "GenSigFuncType" SG_ 2549874885 ISOx_VAS_R_Req_Data 9;
BA_ "GenSigSwitchedByIgnition" SG_ 2549874885 ISOx_VAS_R_Req_Data 0;
BA_ "GenSigSendType" SG_ 2550005957 ISOx_VAS_R_Resp_Data 3;
BA_ "GenSigFuncType" SG_ 2550005957 ISOx_VAS_R_Resp_Data 9;
BA_ "GenSigSwitchedByIgnition" SG_ 2550005957 ISOx_VAS_R_Resp_Data 0;
BA_ "GenSigSendType" SG_ 2549874843 ISOx_zDML_Req_Data 3;
BA_ "GenSigFuncType" SG_ 2549874843 ISOx_zDML_Req_Data 9;
BA_ "GenSigSwitchedByIgnition" SG_ 2549874843 ISOx_zDML_Req_Data 0;
BA_ "GenSigSendType" SG_ 2550005915 ISOx_zDML_Resp_Data 3;
BA_ "GenSigFuncType" SG_ 2550005915 ISOx_zDML_Resp_Data 9;
BA_ "GenSigSwitchedByIgnition" SG_ 2550005915 ISOx_zDML_Resp_Data 0;
BA_ "GenSigSendType" SG_ 2463978614 KAS_Anf_Bremsruck 0;
BA_ "GenSigSendType" SG_ 2463978614 KAS_Anf_OPS 0;
BA_ "GenSigSendType" SG_ 2463978614 KAS_Anf_Prefill 0;
BA_ "GenSigSendType" SG_ 2463978614 KAS_Anzeige_Info_links 3;
BA_ "GenSigSendType" SG_ 2463978614 KAS_Anzeige_Info_rechts 3;
BA_ "GenSigSendType" SG_ 2463978614 KAS_Anzeige_Warnung 3;
BA_ "GenSigSendType" SG_ 2463978614 KAS_Kritikalitaetslevel 0;
BA_ "GenSigStartValue" SG_ 2463978614 KAS_Kritikalitaetslevel 7;
BA_ "GenSigSendType" SG_ 2463978614 KAS_PreSense_Modus_System 0;
BA_ "GenSigSendType" SG_ 2463978614 KAS_Status 3;
BA_ "Fehlerwert" SG_ 2463978614 KAS_Status 6;
BA_ "GenSigSendType" SG_ 2463978614 KAS_Texte 3;
BA_ "GenSigSendType" SG_ 2463978614 KAS_Verfuegbarkeit 3;
BA_ "GenSigSendType" SG_ 2463978614 KAS_Verz_Anf 0;
BA_ "GenSigStartValue" SG_ 2463978614 KAS_Verz_Anf 254;
BA_ "Fehlerwert" SG_ 2463978614 KAS_Verz_Anf 255;
BA_ "GenSigActiveRepetitions" SG_ 497 FBS_Aktivierung_Pilot_Parken 7;
BA_ "GenSigSendType" SG_ 497 FBS_Aktivierung_Pilot_Parken 2;
BA_ "GenSigSwitchedByIgnition" SG_ 497 FBS_Aktivierung_Pilot_Parken 0;
BA_ "GenSigActiveRepetitions" SG_ 497 FFB_FDF_Taste 7;
BA_ "GenSigSendType" SG_ 497 FFB_FDF_Taste 2;
BA_ "GenSigSwitchedByIgnition" SG_ 497 FFB_FDF_Taste 0;
BA_ "GenSigActiveRepetitions" SG_ 497 FFB_Joker_Taste 7;
BA_ "GenSigSendType" SG_ 497 FFB_Joker_Taste 2;
BA_ "GenSigSwitchedByIgnition" SG_ 497 FFB_Joker_Taste 0;
BA_ "GenSigActiveRepetitions" SG_ 497 FFB_Park_Taste 7;
BA_ "GenSigSendType" SG_ 497 FFB_Park_Taste 2;
BA_ "GenSigSwitchedByIgnition" SG_ 497 FFB_Park_Taste 0;
BA_ "GenSigActiveRepetitions" SG_ 497 FFB_Remotestart_Taste 7;
BA_ "GenSigSendType" SG_ 497 FFB_Remotestart_Taste 2;
BA_ "GenSigSwitchedByIgnition" SG_ 497 FFB_Remotestart_Taste 0;
BA_ "GenSigActiveRepetitions" SG_ 497 KY_Auf_Taste 7;
BA_ "GenSigSendType" SG_ 497 KY_Auf_Taste 2;
BA_ "GenSigSwitchedByIgnition" SG_ 497 KY_Auf_Taste 0;
BA_ "GenSigActiveRepetitions" SG_ 497 KY_Bereich 7;
BA_ "GenSigSendType" SG_ 497 KY_Bereich 2;
BA_ "GenSigStartValue" SG_ 497 KY_Bereich 7;
BA_ "GenSigSwitchedByIgnition" SG_ 497 KY_Bereich 0;
BA_ "GenSigActiveRepetitions" SG_ 497 KY_BT_Entriegelung_Autorisiert 7;
BA_ "GenSigSendType" SG_ 497 KY_BT_Entriegelung_Autorisiert 2;
BA_ "GenSigSwitchedByIgnition" SG_ 497 KY_BT_Entriegelung_Autorisiert 0;
BA_ "GenSigActiveRepetitions" SG_ 497 KY_BT_Verriegelung_Autorisiert 7;
BA_ "GenSigSendType" SG_ 497 KY_BT_Verriegelung_Autorisiert 2;
BA_ "GenSigSwitchedByIgnition" SG_ 497 KY_BT_Verriegelung_Autorisiert 0;
BA_ "GenSigSendType" SG_ 497 KY_EasyClose_Abbruch 3;
BA_ "GenSigSwitchedByIgnition" SG_ 497 KY_EasyClose_Abbruch 0;
BA_ "GenSigSendType" SG_ 497 KY_EasyClose_Status 3;
BA_ "GenSigSwitchedByIgnition" SG_ 497 KY_EasyClose_Status 0;
BA_ "GenSigActiveRepetitions" SG_ 497 KY_Front_Entr_Autorisiert 7;
BA_ "GenSigSendType" SG_ 497 KY_Front_Entr_Autorisiert 2;
BA_ "GenSigSwitchedByIgnition" SG_ 497 KY_Front_Entr_Autorisiert 0;
BA_ "GenSigActiveRepetitions" SG_ 497 KY_Front_Verr_Autorisiert 7;
BA_ "GenSigSendType" SG_ 497 KY_Front_Verr_Autorisiert 2;
BA_ "GenSigSwitchedByIgnition" SG_ 497 KY_Front_Verr_Autorisiert 0;
BA_ "GenSigActiveRepetitions" SG_ 497 KY_FT_Entriegelung_Autorisiert 7;
BA_ "GenSigSendType" SG_ 497 KY_FT_Entriegelung_Autorisiert 2;
BA_ "GenSigSwitchedByIgnition" SG_ 497 KY_FT_Entriegelung_Autorisiert 0;
BA_ "GenSigActiveRepetitions" SG_ 497 KY_FT_Verriegelung_Autorisiert 7;
BA_ "GenSigSendType" SG_ 497 KY_FT_Verriegelung_Autorisiert 2;
BA_ "GenSigSwitchedByIgnition" SG_ 497 KY_FT_Verriegelung_Autorisiert 0;
BA_ "GenSigActiveRepetitions" SG_ 497 KY_HBFS_Entriegelung_Autorisiert 7;
BA_ "GenSigSendType" SG_ 497 KY_HBFS_Entriegelung_Autorisiert 2;
BA_ "GenSigSwitchedByIgnition" SG_ 497 KY_HBFS_Entriegelung_Autorisiert 0;
BA_ "GenSigActiveRepetitions" SG_ 497 KY_HBFS_Verriegelung_Autorisiert 7;
BA_ "GenSigSendType" SG_ 497 KY_HBFS_Verriegelung_Autorisiert 2;
BA_ "GenSigSwitchedByIgnition" SG_ 497 KY_HBFS_Verriegelung_Autorisiert 0;
BA_ "GenSigActiveRepetitions" SG_ 497 KY_HD_Auffahrt 7;
BA_ "GenSigSendType" SG_ 497 KY_HD_Auffahrt 2;
BA_ "GenSigSwitchedByIgnition" SG_ 497 KY_HD_Auffahrt 0;
BA_ "GenSigActiveRepetitions" SG_ 497 KY_HD_Entriegelung_Autorisiert 7;
BA_ "GenSigSendType" SG_ 497 KY_HD_Entriegelung_Autorisiert 2;
BA_ "GenSigSwitchedByIgnition" SG_ 497 KY_HD_Entriegelung_Autorisiert 0;
BA_ "GenSigActiveRepetitions" SG_ 497 KY_HD_Verriegelung_Autorisiert 7;
BA_ "GenSigSendType" SG_ 497 KY_HD_Verriegelung_Autorisiert 2;
BA_ "GenSigSwitchedByIgnition" SG_ 497 KY_HD_Verriegelung_Autorisiert 0;
BA_ "GenSigActiveRepetitions" SG_ 497 KY_HD_Zufahrt 7;
BA_ "GenSigSendType" SG_ 497 KY_HD_Zufahrt 2;
BA_ "GenSigSwitchedByIgnition" SG_ 497 KY_HD_Zufahrt 0;
BA_ "GenSigActiveRepetitions" SG_ 497 KY_HDF_Taste 7;
BA_ "GenSigSendType" SG_ 497 KY_HDF_Taste 2;
BA_ "GenSigSwitchedByIgnition" SG_ 497 KY_HDF_Taste 0;
BA_ "GenSigActiveRepetitions" SG_ 497 KY_HFS_Entriegelung_Autorisiert 7;
BA_ "GenSigSendType" SG_ 497 KY_HFS_Entriegelung_Autorisiert 2;
BA_ "GenSigSwitchedByIgnition" SG_ 497 KY_HFS_Entriegelung_Autorisiert 0;
BA_ "GenSigActiveRepetitions" SG_ 497 KY_HFS_Verriegelung_Autorisiert 7;
BA_ "GenSigSendType" SG_ 497 KY_HFS_Verriegelung_Autorisiert 2;
BA_ "GenSigSwitchedByIgnition" SG_ 497 KY_HFS_Verriegelung_Autorisiert 0;
BA_ "GenSigActiveRepetitions" SG_ 497 KY_IDG_in_Reichweite 7;
BA_ "GenSigSendType" SG_ 497 KY_IDG_in_Reichweite 2;
BA_ "GenSigSwitchedByIgnition" SG_ 497 KY_IDG_in_Reichweite 0;
BA_ "GenSigActiveRepetitions" SG_ 497 KY_LKL_1_Autorisierung 7;
BA_ "GenSigSendType" SG_ 497 KY_LKL_1_Autorisierung 2;
BA_ "GenSigSwitchedByIgnition" SG_ 497 KY_LKL_1_Autorisierung 0;
BA_ "GenSigActiveRepetitions" SG_ 497 KY_LKL_2_Autorisierung 7;
BA_ "GenSigSendType" SG_ 497 KY_LKL_2_Autorisierung 2;
BA_ "GenSigSwitchedByIgnition" SG_ 497 KY_LKL_2_Autorisierung 0;
BA_ "GenSigActiveRepetitions" SG_ 497 KY_Panik_Taste 7;
BA_ "GenSigSendType" SG_ 497 KY_Panik_Taste 2;
BA_ "GenSigSwitchedByIgnition" SG_ 497 KY_Panik_Taste 0;
BA_ "GenSigActiveRepetitions" SG_ 497 KY_Position 7;
BA_ "GenSigSendType" SG_ 497 KY_Position 2;
BA_ "GenSigStartValue" SG_ 497 KY_Position 7;
BA_ "GenSigSwitchedByIgnition" SG_ 497 KY_Position 0;
BA_ "GenSigActiveRepetitions" SG_ 497 KY_Schluessel_im_Fzg 7;
BA_ "GenSigSendType" SG_ 497 KY_Schluessel_im_Fzg 2;
BA_ "GenSigSwitchedByIgnition" SG_ 497 KY_Schluessel_im_Fzg 0;
BA_ "GenSigActiveRepetitions" SG_ 497 KY_Zu_Taste 7;
BA_ "GenSigSendType" SG_ 497 KY_Zu_Taste 2;
BA_ "GenSigSwitchedByIgnition" SG_ 497 KY_Zu_Taste 0;
BA_ "GenSigActiveRepetitions" SG_ 497 KY_ZV_Signatur 7;
BA_ "GenSigSendType" SG_ 497 KY_ZV_Signatur 2;
BA_ "GenSigSwitchedByIgnition" SG_ 497 KY_ZV_Signatur 0;
BA_ "GenSigActiveRepetitions" SG_ 497 Schluesselnr_Personalisierung 7;
BA_ "GenSigSendType" SG_ 497 Schluesselnr_Personalisierung 2;
BA_ "GenSigStartValue" SG_ 497 Schluesselnr_Personalisierung 14;
BA_ "GenSigSwitchedByIgnition" SG_ 497 Schluesselnr_Personalisierung 0;
BA_ "Fehlerwert" SG_ 497 Schluesselnr_Personalisierung 15;
BA_ "GenSigSendType" SG_ 1424 FBS_Warn_Schluessel_Batt 3;
BA_ "GenSigSwitchedByIgnition" SG_ 1424 FBS_Warn_Schluessel_Batt 0;
BA_ "GenSigSendType" SG_ 1424 KST_Wegstrecke_Challenge 0;
BA_ "GenSigSwitchedByIgnition" SG_ 1424 KST_Wegstrecke_Challenge 0;
BA_ "GenSigSendType" SG_ 1424 KY_FFB_Frequenz 3;
BA_ "GenSigSwitchedByIgnition" SG_ 1424 KY_FFB_Frequenz 0;
BA_ "GenSigSendType" SG_ 1424 KY_Fzg_Verlassen_erkannt 3;
BA_ "GenSigSwitchedByIgnition" SG_ 1424 KY_Fzg_Verlassen_erkannt 0;
BA_ "GenSigSendType" SG_ 1424 KY_Fzg_Zugang_erkannt 3;
BA_ "GenSigSwitchedByIgnition" SG_ 1424 KY_Fzg_Zugang_erkannt 0;
BA_ "GenSigSendType" SG_ 1424 KY_HF_Aktiv 3;
BA_ "GenSigSwitchedByIgnition" SG_ 1424 KY_HF_Aktiv 0;
BA_ "GenSigSendType" SG_ 1424 KY_Indikator_Mehrere_Schluessel 3;
BA_ "GenSigSwitchedByIgnition" SG_ 1424 KY_Indikator_Mehrere_Schluessel 0;
BA_ "GenSigSendType" SG_ 1424 KY_Keyless_Go_Verbau 3;
BA_ "GenSigSwitchedByIgnition" SG_ 1424 KY_Keyless_Go_Verbau 0;
BA_ "GenSigSendType" SG_ 1424 KY_Keyless_Verbau 3;
BA_ "GenSigSwitchedByIgnition" SG_ 1424 KY_Keyless_Verbau 0;
BA_ "GenSigSendType" SG_ 1424 KY_KYL_Fahrer_Hinweise 3;
BA_ "GenSigSwitchedByIgnition" SG_ 1424 KY_KYL_Fahrer_Hinweise 0;
BA_ "GenSigSendType" SG_ 1424 KY_LF_Aktiv 3;
BA_ "GenSigSwitchedByIgnition" SG_ 1424 KY_LF_Aktiv 0;
BA_ "GenSigSendType" SG_ 1424 KY_NFC_Fahrer_Hinweise 0;
BA_ "GenSigSwitchedByIgnition" SG_ 1424 KY_NFC_Fahrer_Hinweise 0;
BA_ "GenSigSendType" SG_ 1424 KY_StartStopp_Info 3;
BA_ "GenSigSwitchedByIgnition" SG_ 1424 KY_StartStopp_Info 0;
BA_ "GenSigSendType" SG_ 1424 KY_Transponder_aktiv 3;
BA_ "GenSigSwitchedByIgnition" SG_ 1424 KY_Transponder_aktiv 0;
BA_ "GenSigSendType" SG_ 1424 KYL_Warn_kein_Schluessel 3;
BA_ "GenSigSwitchedByIgnition" SG_ 1424 KYL_Warn_kein_Schluessel 0;
BA_ "GenSigSendType" SG_ 1424 KYL_Warn_Kessy_defekt 3;
BA_ "GenSigSwitchedByIgnition" SG_ 1424 KYL_Warn_Kessy_defekt 0;
BA_ "GenSigSendType" SG_ 1424 KYL_Warn_Notzuendschloss 3;
BA_ "GenSigSwitchedByIgnition" SG_ 1424 KYL_Warn_Notzuendschloss 0;
BA_ "GenSigSendType" SG_ 960 BCM_Ausparken_Betrieb 3;
BA_ "GenSigSwitchedByIgnition" SG_ 960 BCM_Ausparken_Betrieb 0;
BA_ "GenSigSendType" SG_ 960 BCM_Remotestart_Betrieb 3;
BA_ "GenSigSwitchedByIgnition" SG_ 960 BCM_Remotestart_Betrieb 0;
BA_ "GenSigSendType" SG_ 960 BCM_Remotestart_KL15_Anf 3;
BA_ "GenSigSwitchedByIgnition" SG_ 960 BCM_Remotestart_KL15_Anf 0;
BA_ "GenSigSendType" SG_ 960 BCM_Remotestart_MO_Start 3;
BA_ "GenSigSwitchedByIgnition" SG_ 960 BCM_Remotestart_MO_Start 0;
BA_ "GenSigSendType" SG_ 960 Klemmen_Status_01_BZ 0;
BA_ "GenSigFuncType" SG_ 960 Klemmen_Status_01_BZ 1;
BA_ "GenSigSwitchedByIgnition" SG_ 960 Klemmen_Status_01_BZ 0;
BA_ "GenSigSendType" SG_ 960 Klemmen_Status_01_CRC 0;
BA_ "GenSigFuncType" SG_ 960 Klemmen_Status_01_CRC 2;
BA_ "GenSigSwitchedByIgnition" SG_ 960 Klemmen_Status_01_CRC 0;
BA_ "GenSigSendType" SG_ 960 KST_Fahrerhinweis_1 3;
BA_ "GenSigSwitchedByIgnition" SG_ 960 KST_Fahrerhinweis_1 0;
BA_ "GenSigSendType" SG_ 960 KST_Fahrerhinweis_2 3;
BA_ "GenSigSwitchedByIgnition" SG_ 960 KST_Fahrerhinweis_2 0;
BA_ "GenSigSendType" SG_ 960 KST_Fahrerhinweis_4 3;
BA_ "GenSigSwitchedByIgnition" SG_ 960 KST_Fahrerhinweis_4 0;
BA_ "GenSigSendType" SG_ 960 KST_Fahrerhinweis_5 3;
BA_ "GenSigSwitchedByIgnition" SG_ 960 KST_Fahrerhinweis_5 0;
BA_ "GenSigSendType" SG_ 960 KST_Fahrerhinweis_6 3;
BA_ "GenSigSwitchedByIgnition" SG_ 960 KST_Fahrerhinweis_6 0;
BA_ "GenSigSendType" SG_ 960 KST_Warn_P1_ZST_def 3;
BA_ "GenSigSwitchedByIgnition" SG_ 960 KST_Warn_P1_ZST_def 0;
BA_ "GenSigSendType" SG_ 960 KST_Warn_P2_ZST_def 3;
BA_ "GenSigSwitchedByIgnition" SG_ 960 KST_Warn_P2_ZST_def 0;
BA_ "GenSigSendType" SG_ 960 RSt_Fahrerhinweise 3;
BA_ "GenSigSwitchedByIgnition" SG_ 960 RSt_Fahrerhinweise 0;
BA_ "GenSigSendType" SG_ 960 ZAS_Kl_15 3;
BA_ "NWM-WakeupAllowed" SG_ 960 ZAS_Kl_15 1;
BA_ "GenSigFuncType" SG_ 960 ZAS_Kl_15 6;
BA_ "GenSigSwitchedByIgnition" SG_ 960 ZAS_Kl_15 0;
BA_ "GenSigSendType" SG_ 960 ZAS_Kl_50_Startanforderung 3;
BA_ "GenSigSwitchedByIgnition" SG_ 960 ZAS_Kl_50_Startanforderung 0;
BA_ "GenSigSendType" SG_ 960 ZAS_Kl_Infotainment 3;
BA_ "GenSigSwitchedByIgnition" SG_ 960 ZAS_Kl_Infotainment 0;
BA_ "GenSigSendType" SG_ 960 ZAS_Kl_S 3;
BA_ "GenSigSwitchedByIgnition" SG_ 960 ZAS_Kl_S 0;
BA_ "GenSigSendType" SG_ 960 ZAS_Kl_X 3;
BA_ "GenSigSwitchedByIgnition" SG_ 960 ZAS_Kl_X 0;
BA_ "GenSigSendType" SG_ 1420 Klemmen_Steuerung_01_BZ 0;
BA_ "GenSigFuncType" SG_ 1420 Klemmen_Steuerung_01_BZ 1;
BA_ "GenSigSwitchedByIgnition" SG_ 1420 Klemmen_Steuerung_01_BZ 0;
BA_ "GenSigSendType" SG_ 1420 Klemmen_Steuerung_01_CRC 0;
BA_ "GenSigFuncType" SG_ 1420 Klemmen_Steuerung_01_CRC 2;
BA_ "GenSigSwitchedByIgnition" SG_ 1420 Klemmen_Steuerung_01_CRC 0;
BA_ "GenSigSendType" SG_ 1420 KST_Anf_Klemmenfreigabe_ELV 8;
BA_ "GenSigSwitchedByIgnition" SG_ 1420 KST_Anf_Klemmenfreigabe_ELV 0;
BA_ "GenSigSendType" SG_ 1420 KST_Anf_ZV_Verriegelung 3;
BA_ "GenSigSwitchedByIgnition" SG_ 1420 KST_Anf_ZV_Verriegelung 0;
BA_ "GenSigActiveRepetitions" SG_ 1420 KST_aut_Abschaltung_Zuendung 3;
BA_ "GenSigSendType" SG_ 1420 KST_aut_Abschaltung_Zuendung 4;
BA_ "GenSigSwitchedByIgnition" SG_ 1420 KST_aut_Abschaltung_Zuendung 0;
BA_ "GenSigSendType" SG_ 1420 KST_Txt_Komfortabschaltung 3;
BA_ "GenSigSwitchedByIgnition" SG_ 1420 KST_Txt_Komfortabschaltung 0;
BA_ "GenSigSendType" SG_ 1420 KST_Txt_P_Gang 3;
BA_ "GenSigSwitchedByIgnition" SG_ 1420 KST_Txt_P_Gang 0;
BA_ "GenSigSendType" SG_ 1420 KST_Txt_Panikabschaltung 3;
BA_ "GenSigSwitchedByIgnition" SG_ 1420 KST_Txt_Panikabschaltung 0;
BA_ "GenSigSendType" SG_ 1420 KST_Unterdr_Zuendungsmeldung 3;
BA_ "GenSigSwitchedByIgnition" SG_ 1420 KST_Unterdr_Zuendungsmeldung 0;
BA_ "GenSigSendType" SG_ 1420 KST_ZAT_betaetigt 3;
BA_ "GenSigSwitchedByIgnition" SG_ 1420 KST_ZAT_betaetigt 0;
BA_ "GenSigSendType" SG_ 1420 Relais_VoKo_angesteuert 3;
BA_ "GenSigSwitchedByIgnition" SG_ 1420 Relais_VoKo_angesteuert 0;
BA_ "GenSigSendType" SG_ 1420 RSt_Anforderung_HMS 3;
BA_ "GenSigSwitchedByIgnition" SG_ 1420 RSt_Anforderung_HMS 0;
BA_ "GenSigSendType" SG_ 1646 KL_Anf_AussenspiegelHzg 3;
BA_ "GenSigSwitchedByIgnition" SG_ 1646 KL_Anf_AussenspiegelHzg 0;
BA_ "GenSigSendType" SG_ 1646 KL_BCmE_Livetip_Freigabe 3;
BA_ "GenSigSwitchedByIgnition" SG_ 1646 KL_BCmE_Livetip_Freigabe 0;
BA_ "GenSigSendType" SG_ 1646 KL_ErwVK_Anf 3;
BA_ "GenSigSwitchedByIgnition" SG_ 1646 KL_ErwVK_Anf 0;
BA_ "GenSigSendType" SG_ 1646 KL_ErwVK_Zusatzrelais 3;
BA_ "GenSigSwitchedByIgnition" SG_ 1646 KL_ErwVK_Zusatzrelais 0;
BA_ "GenSigSendType" SG_ 1646 KL_FSH_Automatikbetrieb 3;
BA_ "GenSigSwitchedByIgnition" SG_ 1646 KL_FSH_Automatikbetrieb 0;
BA_ "GenSigSendType" SG_ 1646 KL_Geblaese_Fond_Status 0;
BA_ "GenSigStartValue" SG_ 1646 KL_Geblaese_Fond_Status 14;
BA_ "GenSigSwitchedByIgnition" SG_ 1646 KL_Geblaese_Fond_Status 0;
BA_ "Fehlerwert" SG_ 1646 KL_Geblaese_Fond_Status 15;
BA_ "GenSigSendType" SG_ 1646 KL_Geblaese_Status 0;
BA_ "GenSigStartValue" SG_ 1646 KL_Geblaese_Status 14;
BA_ "GenSigSwitchedByIgnition" SG_ 1646 KL_Geblaese_Status 0;
BA_ "Fehlerwert" SG_ 1646 KL_Geblaese_Status 15;
BA_ "GenSigSendType" SG_ 1646 KL_Heizkreisventilstellung 0;
BA_ "GenSigSwitchedByIgnition" SG_ 1646 KL_Heizkreisventilstellung 0;
BA_ "Fehlerwert" SG_ 1646 KL_Heizkreisventilstellung 3;
BA_ "GenSigSendType" SG_ 1646 KL_HYB_ASV_hinten_schliessen_Anf 3;
BA_ "GenSigSwitchedByIgnition" SG_ 1646 KL_HYB_ASV_hinten_schliessen_Anf 0;
BA_ "GenSigSendType" SG_ 1646 KL_HYB_ASV_vorne_schliessen_Anf 3;
BA_ "GenSigSwitchedByIgnition" SG_ 1646 KL_HYB_ASV_vorne_schliessen_Anf 0;
BA_ "GenSigSendType" SG_ 1646 KL_I_Geblaese_Fond 3;
BA_ "GenSigSwitchedByIgnition" SG_ 1646 KL_I_Geblaese_Fond 0;
BA_ "Fehlerwert" SG_ 1646 KL_I_Geblaese_Fond 255;
BA_ "GenSigSendType" SG_ 1646 KL_Innen_Temp 0;
BA_ "GenSigStartValue" SG_ 1646 KL_Innen_Temp 254;
BA_ "GenSigSwitchedByIgnition" SG_ 1646 KL_Innen_Temp 0;
BA_ "Fehlerwert" SG_ 1646 KL_Innen_Temp 255;
BA_ "GenSigSendType" SG_ 1646 KL_Kompressorkupplung 3;
BA_ "GenSigSwitchedByIgnition" SG_ 1646 KL_Kompressorkupplung 0;
BA_ "GenSigSendType" SG_ 1646 KL_Magnetventil 3;
BA_ "GenSigSwitchedByIgnition" SG_ 1646 KL_Magnetventil 0;
BA_ "GenSigSendType" SG_ 1646 KL_Restwaerme_aktiv 3;
BA_ "GenSigSwitchedByIgnition" SG_ 1646 KL_Restwaerme_aktiv 0;
BA_ "GenSigSendType" SG_ 1646 KL_SIH_LEH_Verteilung_VL 3;
BA_ "GenSigSwitchedByIgnition" SG_ 1646 KL_SIH_LEH_Verteilung_VL 0;
BA_ "GenSigSendType" SG_ 1646 KL_SIH_LEH_Verteilung_VR 3;
BA_ "GenSigSwitchedByIgnition" SG_ 1646 KL_SIH_LEH_Verteilung_VR 0;
BA_ "GenSigSendType" SG_ 1646 KL_SIH_LEL_Verteilung_VL 3;
BA_ "GenSigSwitchedByIgnition" SG_ 1646 KL_SIH_LEL_Verteilung_VL 0;
BA_ "GenSigSendType" SG_ 1646 KL_SIH_LEL_Verteilung_VR 3;
BA_ "GenSigSwitchedByIgnition" SG_ 1646 KL_SIH_LEL_Verteilung_VR 0;
BA_ "GenSigSendType" SG_ 1646 KL_Solarluefter_aktiv 3;
BA_ "GenSigSwitchedByIgnition" SG_ 1646 KL_Solarluefter_aktiv 0;
BA_ "GenSigSendType" SG_ 1646 KL_Status_Beduftung 3;
BA_ "GenSigSwitchedByIgnition" SG_ 1646 KL_Status_Beduftung 0;
BA_ "GenSigSendType" SG_ 1646 KL_Status_Ionisator_Front 3;
BA_ "GenSigSwitchedByIgnition" SG_ 1646 KL_Status_Ionisator_Front 0;
BA_ "GenSigSendType" SG_ 1646 KL_STH_aktiv 3;
BA_ "GenSigSwitchedByIgnition" SG_ 1646 KL_STH_aktiv 0;
BA_ "GenSigSendType" SG_ 1646 KL_STH_Ansteuerung 3;
BA_ "GenSigSwitchedByIgnition" SG_ 1646 KL_STH_Ansteuerung 0;
BA_ "GenSigSendType" SG_ 1646 KL_STH_Betriebsdauer 3;
BA_ "GenSigSwitchedByIgnition" SG_ 1646 KL_STH_Betriebsdauer 0;
BA_ "GenSigSendType" SG_ 1646 KL_STH_Timer_Status 3;
BA_ "GenSigSwitchedByIgnition" SG_ 1646 KL_STH_Timer_Status 0;
BA_ "GenSigSendType" SG_ 1646 KL_STL_aktiv 3;
BA_ "GenSigSwitchedByIgnition" SG_ 1646 KL_STL_aktiv 0;
BA_ "GenSigSendType" SG_ 1646 KL_Umluft_Taste 3;
BA_ "GenSigSwitchedByIgnition" SG_ 1646 KL_Umluft_Taste 0;
BA_ "GenSigSendType" SG_ 1646 KL_WaPu 3;
BA_ "GenSigSwitchedByIgnition" SG_ 1646 KL_WaPu 0;
BA_ "GenSigSendType" SG_ 1663 KL_Absperrventil_Fond 3;
BA_ "GenSigSwitchedByIgnition" SG_ 1663 KL_Absperrventil_Fond 0;
BA_ "GenSigSendType" SG_ 1663 KL_Einheiten 3;
BA_ "GenSigSwitchedByIgnition" SG_ 1663 KL_Einheiten 0;
BA_ "GenSigSendType" SG_ 1663 KL_Fond_li_reduziert 3;
BA_ "GenSigSwitchedByIgnition" SG_ 1663 KL_Fond_li_reduziert 0;
BA_ "GenSigSendType" SG_ 1663 KL_Fond_re_reduziert 3;
BA_ "GenSigSwitchedByIgnition" SG_ 1663 KL_Fond_re_reduziert 0;
BA_ "GenSigSendType" SG_ 1663 KL_Fondbed_vorne_aktiv 3;
BA_ "GenSigSwitchedByIgnition" SG_ 1663 KL_Fondbed_vorne_aktiv 0;
BA_ "GenSigSendType" SG_ 1663 KL_Gebl_Verst_Abs_Modus 0;
BA_ "GenSigSwitchedByIgnition" SG_ 1663 KL_Gebl_Verst_Abs_Modus 0;
BA_ "GenSigSendType" SG_ 1663 KL_Geblaesespg_Fond 3;
BA_ "GenSigStartValue" SG_ 1663 KL_Geblaesespg_Fond 254;
BA_ "GenSigSwitchedByIgnition" SG_ 1663 KL_Geblaesespg_Fond 0;
BA_ "GenSigSendType" SG_ 1663 KL_Heizverbraucher_aus 3;
BA_ "GenSigSwitchedByIgnition" SG_ 1663 KL_Heizverbraucher_aus 0;
BA_ "GenSigSendType" SG_ 1663 KL_Heizverbraucher_Notaus 3;
BA_ "GenSigSwitchedByIgnition" SG_ 1663 KL_Heizverbraucher_Notaus 0;
BA_ "GenSigSendType" SG_ 1663 KL_ICO2_Sensor_defekt 3;
BA_ "GenSigSwitchedByIgnition" SG_ 1663 KL_ICO2_Sensor_defekt 0;
BA_ "GenSigSendType" SG_ 1663 KL_Kindersicherung 3;
BA_ "GenSigSwitchedByIgnition" SG_ 1663 KL_Kindersicherung 0;
BA_ "GenSigSendType" SG_ 1663 KL_Mod_Display_li 3;
BA_ "GenSigSwitchedByIgnition" SG_ 1663 KL_Mod_Display_li 0;
BA_ "GenSigSendType" SG_ 1663 KL_Mod_Display_re 3;
BA_ "GenSigSwitchedByIgnition" SG_ 1663 KL_Mod_Display_re 0;
BA_ "GenSigSendType" SG_ 1663 KL_SH_HL_Lastabschaltung 3;
BA_ "GenSigSwitchedByIgnition" SG_ 1663 KL_SH_HL_Lastabschaltung 0;
BA_ "GenSigSendType" SG_ 1663 KL_SH_HR_Lastabschaltung 3;
BA_ "GenSigSwitchedByIgnition" SG_ 1663 KL_SH_HR_Lastabschaltung 0;
BA_ "GenSigSendType" SG_ 1663 KL_Sollausblastemp_HL 3;
BA_ "GenSigStartValue" SG_ 1663 KL_Sollausblastemp_HL 1022;
BA_ "GenSigSwitchedByIgnition" SG_ 1663 KL_Sollausblastemp_HL 0;
BA_ "Fehlerwert" SG_ 1663 KL_Sollausblastemp_HL 1023;
BA_ "GenSigSendType" SG_ 1663 KL_Sollausblastemp_HR 3;
BA_ "GenSigStartValue" SG_ 1663 KL_Sollausblastemp_HR 1022;
BA_ "GenSigSwitchedByIgnition" SG_ 1663 KL_Sollausblastemp_HR 0;
BA_ "Fehlerwert" SG_ 1663 KL_Sollausblastemp_HR 1023;
BA_ "GenSigSendType" SG_ 1663 KL_Umluft 3;
BA_ "GenSigStartValue" SG_ 1663 KL_Umluft 254;
BA_ "GenSigSwitchedByIgnition" SG_ 1663 KL_Umluft 0;
BA_ "Fehlerwert" SG_ 1663 KL_Umluft 255;
BA_ "GenSigSendType" SG_ 1649 KL_Betriebsmodus_FH 3;
BA_ "GenSigSwitchedByIgnition" SG_ 1649 KL_Betriebsmodus_FH 0;
BA_ "GenSigSendType" SG_ 1649 KL_Stopp_Wiederstart_Anz_01 3;
BA_ "GenSigSwitchedByIgnition" SG_ 1649 KL_Stopp_Wiederstart_Anz_01 0;
BA_ "GenSigSendType" SG_ 1649 KL_Stopp_Wiederstart_Anz_02 3;
BA_ "GenSigSwitchedByIgnition" SG_ 1649 KL_Stopp_Wiederstart_Anz_02 0;
BA_ "GenSigSendType" SG_ 1649 KL_Stopp_Wiederstart_Anz_03 3;
BA_ "GenSigSwitchedByIgnition" SG_ 1649 KL_Stopp_Wiederstart_Anz_03 0;
BA_ "GenSigSendType" SG_ 1649 KL_Stopp_Wiederstart_Anz_04 3;
BA_ "GenSigSwitchedByIgnition" SG_ 1649 KL_Stopp_Wiederstart_Anz_04 0;
BA_ "GenSigSendType" SG_ 1649 KL_Stopp_Wiederstart_Anz_05 3;
BA_ "GenSigSwitchedByIgnition" SG_ 1649 KL_Stopp_Wiederstart_Anz_05 0;
BA_ "GenSigSendType" SG_ 1649 KL_Stopp_Wiederstart_Anz_06 3;
BA_ "GenSigSwitchedByIgnition" SG_ 1649 KL_Stopp_Wiederstart_Anz_06 0;
BA_ "GenSigSendType" SG_ 1649 KL_Stopp_Wiederstart_Anz_07 3;
BA_ "GenSigSwitchedByIgnition" SG_ 1649 KL_Stopp_Wiederstart_Anz_07 0;
BA_ "GenSigSendType" SG_ 1649 KL_Stopp_Wiederstart_Anz_08 3;
BA_ "GenSigSwitchedByIgnition" SG_ 1649 KL_Stopp_Wiederstart_Anz_08 0;
BA_ "GenSigSendType" SG_ 1649 KL_Stopp_Wiederstart_Anz_09 3;
BA_ "GenSigSwitchedByIgnition" SG_ 1649 KL_Stopp_Wiederstart_Anz_09 0;
BA_ "GenSigSendType" SG_ 1649 KL_Stopp_Wiederstart_Anz_Std1 3;
BA_ "GenSigSwitchedByIgnition" SG_ 1649 KL_Stopp_Wiederstart_Anz_Std1 0;
BA_ "GenSigSendType" SG_ 1649 KL_Stopp_Wiederstart_Anz_Std2 3;
BA_ "GenSigSwitchedByIgnition" SG_ 1649 KL_Stopp_Wiederstart_Anz_Std2 0;
BA_ "GenSigSendType" SG_ 1649 KL_ZZ_Betriebsmodus 3;
BA_ "GenSigSwitchedByIgnition" SG_ 1649 KL_ZZ_Betriebsmodus 0;
BA_ "GenSigSendType" SG_ 1649 KL_ZZ_Minute 3;
BA_ "GenSigSwitchedByIgnition" SG_ 1649 KL_ZZ_Minute 0;
BA_ "GenSigSendType" SG_ 1649 KL_ZZ_Monat 3;
BA_ "GenSigSwitchedByIgnition" SG_ 1649 KL_ZZ_Monat 0;
BA_ "GenSigSendType" SG_ 1649 KL_ZZ_Status_Timer 3;
BA_ "GenSigSwitchedByIgnition" SG_ 1649 KL_ZZ_Status_Timer 0;
BA_ "GenSigSendType" SG_ 1649 KL_ZZ_Stunde 3;
BA_ "GenSigSwitchedByIgnition" SG_ 1649 KL_ZZ_Stunde 0;
BA_ "GenSigSendType" SG_ 1649 KL_ZZ_Tag 3;
BA_ "GenSigSwitchedByIgnition" SG_ 1649 KL_ZZ_Tag 0;
BA_ "GenSigSendType" SG_ 1608 KL_AC_Fond_Soll 3;
BA_ "GenSigSwitchedByIgnition" SG_ 1608 KL_AC_Fond_Soll 0;
BA_ "GenSigSendType" SG_ 1608 KL_AUTO_HL_Soll 3;
BA_ "GenSigSwitchedByIgnition" SG_ 1608 KL_AUTO_HL_Soll 0;
BA_ "GenSigSendType" SG_ 1608 KL_AUTO_HR_Soll 3;
BA_ "GenSigSwitchedByIgnition" SG_ 1608 KL_AUTO_HR_Soll 0;
BA_ "GenSigSendType" SG_ 1608 KL_Befehlszaehler_FH 3;
BA_ "GenSigSwitchedByIgnition" SG_ 1608 KL_Befehlszaehler_FH 0;
BA_ "GenSigSendType" SG_ 1608 KL_Fondbedienung_aktiv 3;
BA_ "GenSigSwitchedByIgnition" SG_ 1608 KL_Fondbedienung_aktiv 0;
BA_ "GenSigSendType" SG_ 1608 KL_Luftmenge_HL_max 3;
BA_ "GenSigSwitchedByIgnition" SG_ 1608 KL_Luftmenge_HL_max 0;
BA_ "GenSigSendType" SG_ 1608 KL_Luftmenge_HL_offset 3;
BA_ "GenSigSwitchedByIgnition" SG_ 1608 KL_Luftmenge_HL_offset 0;
BA_ "GenSigSendType" SG_ 1608 KL_Luftmenge_HL_Soll 3;
BA_ "GenSigSwitchedByIgnition" SG_ 1608 KL_Luftmenge_HL_Soll 0;
BA_ "GenSigSendType" SG_ 1608 KL_Luftmenge_HR_max 3;
BA_ "GenSigSwitchedByIgnition" SG_ 1608 KL_Luftmenge_HR_max 0;
BA_ "GenSigSendType" SG_ 1608 KL_Luftmenge_HR_offset 3;
BA_ "GenSigSwitchedByIgnition" SG_ 1608 KL_Luftmenge_HR_offset 0;
BA_ "GenSigSendType" SG_ 1608 KL_Luftmenge_HR_Soll 3;
BA_ "GenSigSwitchedByIgnition" SG_ 1608 KL_Luftmenge_HR_Soll 0;
BA_ "GenSigSendType" SG_ 1608 KL_Luftverteilung_HL_Soll 3;
BA_ "GenSigSwitchedByIgnition" SG_ 1608 KL_Luftverteilung_HL_Soll 0;
BA_ "GenSigSendType" SG_ 1608 KL_Luftverteilung_HR_Soll 3;
BA_ "GenSigSwitchedByIgnition" SG_ 1608 KL_Luftverteilung_HR_Soll 0;
BA_ "GenSigSendType" SG_ 1608 KL_SH_HL_Soll 3;
BA_ "GenSigSwitchedByIgnition" SG_ 1608 KL_SH_HL_Soll 0;
BA_ "GenSigSendType" SG_ 1608 KL_SH_HR_Soll 3;
BA_ "GenSigSwitchedByIgnition" SG_ 1608 KL_SH_HR_Soll 0;
BA_ "GenSigSendType" SG_ 1608 KL_SL_HL_Soll 3;
BA_ "GenSigSwitchedByIgnition" SG_ 1608 KL_SL_HL_Soll 0;
BA_ "GenSigSendType" SG_ 1608 KL_SL_HR_Soll 3;
BA_ "GenSigSwitchedByIgnition" SG_ 1608 KL_SL_HR_Soll 0;
BA_ "GenSigSendType" SG_ 1608 KL_Status_Soll 3;
BA_ "GenSigSwitchedByIgnition" SG_ 1608 KL_Status_Soll 0;
BA_ "GenSigSendType" SG_ 1608 KL_Temp_HL_Soll 3;
BA_ "GenSigSwitchedByIgnition" SG_ 1608 KL_Temp_HL_Soll 0;
BA_ "GenSigSendType" SG_ 1608 KL_Temp_HR_Soll 3;
BA_ "GenSigSwitchedByIgnition" SG_ 1608 KL_Temp_HR_Soll 0;
BA_ "GenSigSendType" SG_ 949 KL_AC_Schalter 0;
BA_ "GenSigSwitchedByIgnition" SG_ 949 KL_AC_Schalter 0;
BA_ "GenSigSendType" SG_ 949 KL_Anf_KL 0;
BA_ "GenSigSwitchedByIgnition" SG_ 949 KL_Anf_KL 0;
BA_ "Fehlerwert" SG_ 949 KL_Anf_KL 255;
BA_ "GenSigSendType" SG_ 949 KL_Ausstattung_Klima 0;
BA_ "GenSigSwitchedByIgnition" SG_ 949 KL_Ausstattung_Klima 0;
BA_ "GenSigSendType" SG_ 949 KL_Charisma_FahrPr 0;
BA_ "GenSigSwitchedByIgnition" SG_ 949 KL_Charisma_FahrPr 0;
BA_ "GenSigSendType" SG_ 949 KL_Charisma_Status 0;
BA_ "GenSigSwitchedByIgnition" SG_ 949 KL_Charisma_Status 0;
BA_ "GenSigSendType" SG_ 949 KL_Drehz_Anh 0;
BA_ "GenSigSwitchedByIgnition" SG_ 949 KL_Drehz_Anh 0;
BA_ "GenSigSendType" SG_ 949 KL_el_Zuheizer_Stufe 0;
BA_ "GenSigSwitchedByIgnition" SG_ 949 KL_el_Zuheizer_Stufe 0;
BA_ "GenSigSendType" SG_ 949 KL_Freilauf_Info 0;
BA_ "GenSigSwitchedByIgnition" SG_ 949 KL_Freilauf_Info 0;
BA_ "GenSigSendType" SG_ 949 KL_Komp_Moment_alt 0;
BA_ "GenSigFuncType" SG_ 949 KL_Komp_Moment_alt 5;
BA_ "GenSigSwitchedByIgnition" SG_ 949 KL_Komp_Moment_alt 0;
BA_ "GenSigSendType" SG_ 949 KL_Kompressorkupplung_linear 0;
BA_ "GenSigStartValue" SG_ 949 KL_Kompressorkupplung_linear 254;
BA_ "GenSigSwitchedByIgnition" SG_ 949 KL_Kompressorkupplung_linear 0;
BA_ "GenSigSendType" SG_ 949 KL_Last_Kompr 0;
BA_ "GenSigSwitchedByIgnition" SG_ 949 KL_Last_Kompr 0;
BA_ "Fehlerwert" SG_ 949 KL_Last_Kompr 255;
BA_ "GenSigSendType" SG_ 949 KL_nachtr_Stopp_Anf 0;
BA_ "GenSigSwitchedByIgnition" SG_ 949 KL_nachtr_Stopp_Anf 0;
BA_ "GenSigSendType" SG_ 949 KL_Spannungs_Anf 0;
BA_ "GenSigSwitchedByIgnition" SG_ 949 KL_Spannungs_Anf 0;
BA_ "GenSigSendType" SG_ 949 KL_StartStopp_Info 0;
BA_ "GenSigSwitchedByIgnition" SG_ 949 KL_StartStopp_Info 0;
BA_ "GenSigSendType" SG_ 949 KL_T_Charge 0;
BA_ "GenSigSwitchedByIgnition" SG_ 949 KL_T_Charge 0;
BA_ "GenSigSendType" SG_ 949 KL_Thermomanagement 0;
BA_ "GenSigSwitchedByIgnition" SG_ 949 KL_Thermomanagement 0;
BA_ "GenSigSendType" SG_ 949 KL_Variante_Standheizung 0;
BA_ "GenSigSwitchedByIgnition" SG_ 949 KL_Variante_Standheizung 0;
BA_ "GenSigSendType" SG_ 949 KL_Vorwarn_Komp_ein 0;
BA_ "GenSigSwitchedByIgnition" SG_ 949 KL_Vorwarn_Komp_ein 0;
BA_ "GenSigSendType" SG_ 949 KL_Vorwarn_Zuheizer_ein 0;
BA_ "GenSigSwitchedByIgnition" SG_ 949 KL_Vorwarn_Zuheizer_ein 0;
BA_ "GenSigSendType" SG_ 949 KL_Zustand 0;
BA_ "GenSigSwitchedByIgnition" SG_ 949 KL_Zustand 0;
BA_ "GenSigActiveRepetitions" SG_ 1640 FSH_Taster 5;
BA_ "GenSigSendType" SG_ 1640 FSH_Taster 4;
BA_ "GenSigSwitchedByIgnition" SG_ 1640 FSH_Taster 0;
BA_ "GenSigActiveRepetitions" SG_ 1640 HSH_Taster 5;
BA_ "GenSigSendType" SG_ 1640 HSH_Taster 4;
BA_ "GenSigSwitchedByIgnition" SG_ 1640 HSH_Taster 0;
BA_ "GenSigSendType" SG_ 1640 KL_Beschlagsgefahr 3;
BA_ "GenSigSwitchedByIgnition" SG_ 1640 KL_Beschlagsgefahr 0;
BA_ "GenSigSendType" SG_ 1640 KL_Geblspng_Fond_Soll 0;
BA_ "GenSigSwitchedByIgnition" SG_ 1640 KL_Geblspng_Fond_Soll 0;
BA_ "Fehlerwert" SG_ 1640 KL_Geblspng_Fond_Soll 255;
BA_ "GenSigSendType" SG_ 1640 KL_Geblspng_Soll 0;
BA_ "GenSigSwitchedByIgnition" SG_ 1640 KL_Geblspng_Soll 0;
BA_ "Fehlerwert" SG_ 1640 KL_Geblspng_Soll 255;
BA_ "GenSigSendType" SG_ 1640 KL_I_Geblaese 0;
BA_ "GenSigSwitchedByIgnition" SG_ 1640 KL_I_Geblaese 0;
BA_ "Fehlerwert" SG_ 1640 KL_I_Geblaese 255;
BA_ "GenSigSendType" SG_ 1640 KL_Kompressorstrom_soll 0;
BA_ "GenSigStartValue" SG_ 1640 KL_Kompressorstrom_soll 1022;
BA_ "GenSigSwitchedByIgnition" SG_ 1640 KL_Kompressorstrom_soll 0;
BA_ "Fehlerwert" SG_ 1640 KL_Kompressorstrom_soll 1023;
BA_ "GenSigSendType" SG_ 1640 KL_LRH_Stufe 0;
BA_ "GenSigStartValue" SG_ 1640 KL_LRH_Stufe 1;
BA_ "GenSigSwitchedByIgnition" SG_ 1640 KL_LRH_Stufe 0;
BA_ "GenSigActiveRepetitions" SG_ 1640 KL_LRH_Taster 5;
BA_ "GenSigSendType" SG_ 1640 KL_LRH_Taster 4;
BA_ "GenSigSwitchedByIgnition" SG_ 1640 KL_LRH_Taster 0;
BA_ "GenSigSendType" SG_ 1640 KL_PTC_Verbauinfo 0;
BA_ "GenSigSwitchedByIgnition" SG_ 1640 KL_PTC_Verbauinfo 0;
BA_ "GenSigSendType" SG_ 1640 KL_SIH_Soll_li 3;
BA_ "GenSigSwitchedByIgnition" SG_ 1640 KL_SIH_Soll_li 0;
BA_ "GenSigSendType" SG_ 1640 KL_SIH_Soll_re 3;
BA_ "GenSigSwitchedByIgnition" SG_ 1640 KL_SIH_Soll_re 0;
BA_ "GenSigSendType" SG_ 1640 KL_SIL_Soll_li 3;
BA_ "GenSigSwitchedByIgnition" SG_ 1640 KL_SIL_Soll_li 0;
BA_ "GenSigSendType" SG_ 1640 KL_SIL_Soll_re 3;
BA_ "GenSigSwitchedByIgnition" SG_ 1640 KL_SIL_Soll_re 0;
BA_ "GenSigSendType" SG_ 1640 KL_Umluftklappe_Status 0;
BA_ "GenSigStartValue" SG_ 1640 KL_Umluftklappe_Status 14;
BA_ "GenSigSwitchedByIgnition" SG_ 1640 KL_Umluftklappe_Status 0;
BA_ "Fehlerwert" SG_ 1640 KL_Umluftklappe_Status 15;
BA_ "GenSigSendType" SG_ 1640 KL_Zuheizer_Freigabe 3;
BA_ "GenSigSwitchedByIgnition" SG_ 1640 KL_Zuheizer_Freigabe 0;
BA_ "GenSigSendType" SG_ 1640 KRH_Soll_li 3;
BA_ "GenSigSwitchedByIgnition" SG_ 1640 KRH_Soll_li 0;
BA_ "GenSigSendType" SG_ 1640 KRH_Soll_re 3;
BA_ "GenSigSwitchedByIgnition" SG_ 1640 KRH_Soll_re 0;
BA_ "GenSigSendType" SG_ 1441 KL_Frischluftklappe_Status 0;
BA_ "GenSigStartValue" SG_ 1441 KL_Frischluftklappe_Status 126;
BA_ "GenSigSwitchedByIgnition" SG_ 1441 KL_Frischluftklappe_Status 0;
BA_ "Fehlerwert" SG_ 1441 KL_Frischluftklappe_Status 127;
BA_ "GenSigSendType" SG_ 1441 KL_PTC_linear_Anf 0;
BA_ "GenSigSwitchedByIgnition" SG_ 1441 KL_PTC_linear_Anf 0;
BA_ "Fehlerwert" SG_ 1441 KL_PTC_linear_Anf 63;
BA_ "GenSigSendType" SG_ 1441 KL_SIH_LEH_Verteilung_HL 0;
BA_ "GenSigSwitchedByIgnition" SG_ 1441 KL_SIH_LEH_Verteilung_HL 0;
BA_ "GenSigSendType" SG_ 1441 KL_SIH_LEH_Verteilung_HR 0;
BA_ "GenSigSwitchedByIgnition" SG_ 1441 KL_SIH_LEH_Verteilung_HR 0;
BA_ "GenSigSendType" SG_ 1441 KL_SIH_Stufe_hl 0;
BA_ "GenSigSwitchedByIgnition" SG_ 1441 KL_SIH_Stufe_hl 0;
BA_ "GenSigSendType" SG_ 1441 KL_SIH_Stufe_hr 0;
BA_ "GenSigSwitchedByIgnition" SG_ 1441 KL_SIH_Stufe_hr 0;
BA_ "GenSigSendType" SG_ 1441 KL_SIL_LEL_Verteilung_HL 0;
BA_ "GenSigSwitchedByIgnition" SG_ 1441 KL_SIL_LEL_Verteilung_HL 0;
BA_ "GenSigSendType" SG_ 1441 KL_SIL_LEL_Verteilung_HR 0;
BA_ "GenSigSwitchedByIgnition" SG_ 1441 KL_SIL_LEL_Verteilung_HR 0;
BA_ "GenSigSendType" SG_ 1441 KL_SIL_Stufe_hl 0;
BA_ "GenSigSwitchedByIgnition" SG_ 1441 KL_SIL_Stufe_hl 0;
BA_ "GenSigSendType" SG_ 1441 KL_SIL_Stufe_hr 0;
BA_ "GenSigSwitchedByIgnition" SG_ 1441 KL_SIL_Stufe_hr 0;
BA_ "GenSigSendType" SG_ 1441 KL_Temp_Soll_hl 0;
BA_ "GenSigStartValue" SG_ 1441 KL_Temp_Soll_hl 31;
BA_ "GenSigSwitchedByIgnition" SG_ 1441 KL_Temp_Soll_hl 0;
BA_ "GenSigSendType" SG_ 1441 KL_Temp_Soll_hr 0;
BA_ "GenSigStartValue" SG_ 1441 KL_Temp_Soll_hr 31;
BA_ "GenSigSwitchedByIgnition" SG_ 1441 KL_Temp_Soll_hr 0;
BA_ "GenSigSendType" SG_ 1441 KL_Temp_Soll_vl 0;
BA_ "GenSigStartValue" SG_ 1441 KL_Temp_Soll_vl 31;
BA_ "GenSigSwitchedByIgnition" SG_ 1441 KL_Temp_Soll_vl 0;
BA_ "GenSigSendType" SG_ 1441 KL_Temp_Soll_vr 0;
BA_ "GenSigStartValue" SG_ 1441 KL_Temp_Soll_vr 31;
BA_ "GenSigSwitchedByIgnition" SG_ 1441 KL_Temp_Soll_vr 0;
BA_ "GenSigSendType" SG_ 2589283469 KL_Geblaese_erw 0;
BA_ "GenSigStartValue" SG_ 2589283469 KL_Geblaese_erw 14;
BA_ "GenSigSwitchedByIgnition" SG_ 2589283469 KL_Geblaese_erw 0;
BA_ "Fehlerwert" SG_ 2589283469 KL_Geblaese_erw 15;
BA_ "GenSigSendType" SG_ 2589283469 KL_Geblaese_Fond_erw 0;
BA_ "GenSigStartValue" SG_ 2589283469 KL_Geblaese_Fond_erw 14;
BA_ "GenSigSwitchedByIgnition" SG_ 2589283469 KL_Geblaese_Fond_erw 0;
BA_ "Fehlerwert" SG_ 2589283469 KL_Geblaese_Fond_erw 15;
BA_ "GenSigSendType" SG_ 2589283469 KL_Heizlstg_Delta_Eingriff 3;
BA_ "GenSigStartValue" SG_ 2589283469 KL_Heizlstg_Delta_Eingriff 254;
BA_ "GenSigSwitchedByIgnition" SG_ 2589283469 KL_Heizlstg_Delta_Eingriff 0;
BA_ "Fehlerwert" SG_ 2589283469 KL_Heizlstg_Delta_Eingriff 255;
BA_ "GenSigSendType" SG_ 2589283469 KL_Kuehllstg_Delta_Eingriff 3;
BA_ "GenSigStartValue" SG_ 2589283469 KL_Kuehllstg_Delta_Eingriff 254;
BA_ "GenSigSwitchedByIgnition" SG_ 2589283469 KL_Kuehllstg_Delta_Eingriff 0;
BA_ "Fehlerwert" SG_ 2589283469 KL_Kuehllstg_Delta_Eingriff 255;
BA_ "GenSigSendType" SG_ 2589283469 KL_Tempklappe_Fond 0;
BA_ "GenSigStartValue" SG_ 2589283469 KL_Tempklappe_Fond 254;
BA_ "GenSigSwitchedByIgnition" SG_ 2589283469 KL_Tempklappe_Fond 0;
BA_ "Fehlerwert" SG_ 2589283469 KL_Tempklappe_Fond 255;
BA_ "GenSigSendType" SG_ 2589283469 KL_Tempklappe_li 0;
BA_ "GenSigStartValue" SG_ 2589283469 KL_Tempklappe_li 254;
BA_ "GenSigSwitchedByIgnition" SG_ 2589283469 KL_Tempklappe_li 0;
BA_ "Fehlerwert" SG_ 2589283469 KL_Tempklappe_li 255;
BA_ "GenSigSendType" SG_ 2589283469 KL_Tempklappe_re 0;
BA_ "GenSigStartValue" SG_ 2589283469 KL_Tempklappe_re 254;
BA_ "GenSigSwitchedByIgnition" SG_ 2589283469 KL_Tempklappe_re 0;
BA_ "Fehlerwert" SG_ 2589283469 KL_Tempklappe_re 255;
BA_ "GenSigSendType" SG_ 2589283469 KL_Verdampferleistung 3;
BA_ "GenSigStartValue" SG_ 2589283469 KL_Verdampferleistung 254;
BA_ "GenSigSwitchedByIgnition" SG_ 2589283469 KL_Verdampferleistung 0;
BA_ "Fehlerwert" SG_ 2589283469 KL_Verdampferleistung 255;
BA_ "GenSigSendType" SG_ 2589283469 KL_Verdampferleistung_Faktor 3;
BA_ "GenSigSwitchedByIgnition" SG_ 2589283469 KL_Verdampferleistung_Faktor 0;
BA_ "GenSigSendType" SG_ 2589283469 KL_VK_Anf 3;
BA_ "GenSigStartValue" SG_ 2589283469 KL_VK_Anf 6;
BA_ "GenSigSwitchedByIgnition" SG_ 2589283469 KL_VK_Anf 0;
BA_ "Fehlerwert" SG_ 2589283469 KL_VK_Anf 7;
BA_ "GenSigSendType" SG_ 2589283469 KL_Vorkond_Strategie 3;
BA_ "GenSigStartValue" SG_ 2589283469 KL_Vorkond_Strategie 15;
BA_ "GenSigSwitchedByIgnition" SG_ 2589283469 KL_Vorkond_Strategie 0;
BA_REL_ "GenSigTimeoutTime" BU_SG_REL_ BCM1 SG_ 1381 HVLM_FreigabeKlimatisierung 1000;
BA_REL_ "GenSigTimeoutTime" BU_SG_REL_ BCM1 SG_ 1340 HVLM_STH_Betriebsmodus 1000;
BA_REL_ "GenSigTimeoutTime" BU_SG_REL_ BCM1 SG_ 1340 HVLM_Standklima_Timer_Status 1000;
BA_REL_ "GenSigTimeoutTime" BU_SG_REL_ BCM1 SG_ 1340 HVLM_VK_STH_Einsatz 1000;
BA_REL_ "GenSigTimeoutTime" BU_SG_REL_ BCM1 SG_ 1340 HVLM_VK_Modus 1000;
BA_REL_ "GenSigTimeoutTime" BU_SG_REL_ BCM1 SG_ 2589283485 HVLM_Dauer_Klima_02 5000;
BA_REL_ "GenSigTimeoutTime" BU_SG_REL_ BCM1 SG_ 2463978610 HVLM_Ladeanzeige_Anf 5000;
BA_REL_ "GenSigTimeoutTime" BU_SG_REL_ BCM1 SG_ 2463978610 HVLM_Ladeanzeige_Status 5000;
BA_REL_ "GenSigTimeoutTime" BU_SG_REL_ BCM1 SG_ 312 Parken_aktives_System 2000;
BA_REL_ "GenSigTimeoutTime" BU_SG_REL_ BCM1 SG_ 312 IPA_Status_IPA_TSK 2000;
BA_REL_ "GenSigTimeoutTime" BU_SG_REL_ BCM1 SG_ 312 IPA_PLA_LED 2000;
BA_REL_ "GenSigTimeoutTime" BU_SG_REL_ BCM1 SG_ 312 IPA_APS_LED 2000;
BA_REL_ "GenSigTimeoutTime" BU_SG_REL_ BCM1 SG_ 2527679583 Parken_Aktivierungslicht_Anf 5000;
BA_REL_ "GenSigTimeoutTime" BU_SG_REL_ BCM1 SG_ 2527679583 Parken_Fahrtrichtungslicht_Anf 5000;
BA_REL_ "GenSigTimeoutTime" BU_SG_REL_ BCM1 SG_ 2527679583 Parken_Lichtnachlauf_Anf 5000;
BA_REL_ "GenSigTimeoutTime" BU_SG_REL_ BCM1 SG_ 2527679583 Parken_Bestaetigungsblinken_Anf 5000;
BA_REL_ "GenSigTimeoutTime" BU_SG_REL_ BCM1 SG_ 2527679583 Parken_Fahrbereitschaftlicht_Anf 5000;
BA_REL_ "GenSigTimeoutTime" BU_SG_REL_ BCM1 SG_ 2463978614 KAS_Kritikalitaetslevel 2000;
BA_REL_ "GenSigTimeoutTime" BU_SG_REL_ BCM1 SG_ 2463978614 KAS_Anf_OPS 2000;
BA_REL_ "GenSigTimeoutTime" BU_SG_REL_ BCM1 SG_ 497 KY_HDF_Taste 5000;
BA_REL_ "GenSigTimeoutTime" BU_SG_REL_ BCM1 SG_ 497 KY_FT_Entriegelung_Autorisiert 5000;
BA_REL_ "GenSigTimeoutTime" BU_SG_REL_ BCM1 SG_ 497 KY_Front_Entr_Autorisiert 5000;
BA_REL_ "GenSigTimeoutTime" BU_SG_REL_ BCM1 SG_ 497 KY_Front_Verr_Autorisiert 5000;
BA_REL_ "GenSigTimeoutTime" BU_SG_REL_ BCM1 SG_ 497 KY_Bereich 5000;
BA_REL_ "GenSigTimeoutTime" BU_SG_REL_ BCM1 SG_ 497 KY_Position 5000;
BA_REL_ "GenSigTimeoutTime" BU_SG_REL_ BCM1 SG_ 497 Schluesselnr_Personalisierung 5000;
BA_REL_ "GenSigTimeoutTime" BU_SG_REL_ BCM1 SG_ 497 FFB_FDF_Taste 5000;
BA_REL_ "GenSigTimeoutTime" BU_SG_REL_ BCM1 SG_ 497 FFB_Joker_Taste 5000;
BA_REL_ "GenSigTimeoutTime" BU_SG_REL_ BCM1 SG_ 1424 KY_Transponder_aktiv 2000;
BA_REL_ "GenSigTimeoutTime" BU_SG_REL_ BCM1 SG_ 960 Klemmen_Status_01_CRC 1000;
BA_REL_ "GenSigTimeoutTime" BU_SG_REL_ BCM1 SG_ 960 Klemmen_Status_01_BZ 1000;
BA_REL_ "GenSigTimeoutTime" BU_SG_REL_ BCM1 SG_ 960 ZAS_Kl_S 1000;
BA_REL_ "GenSigTimeoutTime" BU_SG_REL_ BCM1 SG_ 960 ZAS_Kl_15 1000;
BA_REL_ "GenSigTimeoutTime" BU_SG_REL_ BCM1 SG_ 960 ZAS_Kl_50_Startanforderung 1000;
BA_REL_ "GenSigTimeoutTime" BU_SG_REL_ BCM1 SG_ 960 BCM_Remotestart_Betrieb 1000;
BA_REL_ "GenSigTimeoutTime" BU_SG_REL_ BCM1 SG_ 960 BCM_Remotestart_KL15_Anf 1000;
BA_REL_ "GenSigTimeoutTime" BU_SG_REL_ BCM1 SG_ 1420 KST_aut_Abschaltung_Zuendung 5000;
BA_REL_ "GenSigTimeoutTime" BU_SG_REL_ BCM1 SG_ 1420 Relais_VoKo_angesteuert 5000;
BA_REL_ "GenSigTimeoutTime" BU_SG_REL_ BCM1 SG_ 1646 KL_STH_aktiv 5000;
BA_REL_ "GenSigTimeoutTime" BU_SG_REL_ BCM1 SG_ 1646 KL_Geblaese_Fond_Status 5000;
BA_REL_ "GenSigTimeoutTime" BU_SG_REL_ BCM1 SG_ 1646 KL_Geblaese_Status 5000;
BA_REL_ "GenSigTimeoutTime" BU_SG_REL_ BCM1 SG_ 1646 KL_Kompressorkupplung 5000;
BA_REL_ "GenSigTimeoutTime" BU_SG_REL_ BCM1 SG_ 1646 KL_ErwVK_Anf 5000;
BA_REL_ "GenSigTimeoutTime" BU_SG_REL_ BCM1 SG_ 1646 KL_Innen_Temp 5000;
BA_REL_ "GenSigTimeoutTime" BU_SG_REL_ BCM1 SG_ 1646 KL_SIH_LEL_Verteilung_VL 5000;
BA_REL_ "GenSigTimeoutTime" BU_SG_REL_ BCM1 SG_ 1646 KL_SIH_LEH_Verteilung_VR 5000;
BA_REL_ "GenSigTimeoutTime" BU_SG_REL_ BCM1 SG_ 1608 KL_SL_HL_Soll 5000;
BA_REL_ "GenSigTimeoutTime" BU_SG_REL_ BCM1 SG_ 1608 KL_SL_HR_Soll 5000;
BA_REL_ "GenSigTimeoutTime" BU_SG_REL_ BCM1 SG_ 1608 KL_SH_HR_Soll 5000;
BA_REL_ "GenSigTimeoutTime" BU_SG_REL_ BCM1 SG_ 1608 KL_SH_HL_Soll 5000;
BA_REL_ "GenSigTimeoutTime" BU_SG_REL_ BCM1 SG_ 949 KL_Kompressorkupplung_linear 1000;
BA_REL_ "GenSigTimeoutTime" BU_SG_REL_ BCM1 SG_ 949 KL_el_Zuheizer_Stufe 1000;
BA_REL_ "GenSigTimeoutTime" BU_SG_REL_ BCM1 SG_ 949 KL_Ausstattung_Klima 1000;
BA_REL_ "GenSigTimeoutTime" BU_SG_REL_ BCM1 SG_ 1640 KL_SIH_Soll_li 2000;
BA_REL_ "GenSigTimeoutTime" BU_SG_REL_ BCM1 SG_ 1640 KL_SIH_Soll_re 2000;
BA_REL_ "GenSigTimeoutTime" BU_SG_REL_ BCM1 SG_ 1640 KL_SIL_Soll_li 2000;
BA_REL_ "GenSigTimeoutTime" BU_SG_REL_ BCM1 SG_ 1640 KL_SIL_Soll_re 2000;
BA_REL_ "GenSigTimeoutTime" BU_SG_REL_ BCM1 SG_ 1640 KL_Kompressorstrom_soll 2000;
BA_REL_ "GenSigTimeoutTime" BU_SG_REL_ BCM1 SG_ 1441 KL_Temp_Soll_hl 5000;
BA_REL_ "GenSigTimeoutTime" BU_SG_REL_ BCM1 SG_ 1441 KL_Temp_Soll_hr 5000;
BA_REL_ "GenSigTimeoutTime" BU_SG_REL_ BCM1 SG_ 1441 KL_Temp_Soll_vl 5000;
BA_REL_ "GenSigTimeoutTime" BU_SG_REL_ BCM1 SG_ 1441 KL_Temp_Soll_vr 5000;
BA_REL_ "GenSigTimeoutTime" BU_SG_REL_ BCM1 SG_ 1441 KL_SIL_LEL_Verteilung_HR 5000;
BA_REL_ "GenSigTimeoutTime" BU_SG_REL_ BCM1 SG_ 1441 KL_SIL_LEL_Verteilung_HL 5000;
BA_REL_ "GenSigTimeoutTime" BU_SG_REL_ BCM1 SG_ 1441 KL_SIH_LEH_Verteilung_HR 5000;
BA_REL_ "GenSigTimeoutTime" BU_SG_REL_ BCM1 SG_ 1441 KL_SIH_LEH_Verteilung_HL 5000;
BA_REL_ "GenSigTimeoutTime" BU_SG_REL_ Gateway SG_ 1524 IL_Innenlicht_aktiv 5000;
BA_REL_ "GenSigTimeoutTime" BU_SG_REL_ Gateway SG_ 1524 AMB_Charisma_FahrPr 5000;
BA_REL_ "GenSigTimeoutTime" BU_SG_REL_ Gateway SG_ 1524 AMB_Charisma_Status 5000;
BA_REL_ "GenSigTimeoutTime" BU_SG_REL_ Gateway SG_ 1646 KL_STH_aktiv 5000;
BA_REL_ "GenSigTimeoutTime" BU_SG_REL_ Gateway SG_ 1646 KL_Geblaese_Fond_Status 5000;
BA_REL_ "GenSigTimeoutTime" BU_SG_REL_ Gateway SG_ 1646 KL_Geblaese_Status 5000;
BA_REL_ "GenSigTimeoutTime" BU_SG_REL_ Gateway SG_ 1646 KL_BCmE_Livetip_Freigabe 5000;
BA_REL_ "GenSigTimeoutTime" BU_SG_REL_ Gateway SG_ 1646 KL_Status_Beduftung 5000;
BA_REL_ "GenSigTimeoutTime" BU_SG_REL_ Gateway SG_ 1646 KL_Status_Ionisator_Front 5000;
BA_REL_ "GenSigTimeoutTime" BU_SG_REL_ Gateway SG_ 1646 KL_ErwVK_Anf 5000;
BA_REL_ "GenSigTimeoutTime" BU_SG_REL_ Gateway SG_ 1646 KL_Innen_Temp 5000;
BA_REL_ "GenSigTimeoutTime" BU_SG_REL_ Gateway SG_ 1646 KL_SIH_LEH_Verteilung_VL 5000;
BA_REL_ "GenSigTimeoutTime" BU_SG_REL_ Gateway SG_ 1646 KL_SIH_LEL_Verteilung_VL 5000;
BA_REL_ "GenSigTimeoutTime" BU_SG_REL_ Gateway SG_ 1646 KL_SIH_LEH_Verteilung_VR 5000;
BA_REL_ "GenSigTimeoutTime" BU_SG_REL_ Gateway SG_ 1646 KL_SIH_LEL_Verteilung_VR 5000;
BA_REL_ "GenSigTimeoutTime" BU_SG_REL_ Gateway SG_ 1649 KL_Stopp_Wiederstart_Anz_01 5000;
BA_REL_ "GenSigTimeoutTime" BU_SG_REL_ Gateway SG_ 1649 KL_Stopp_Wiederstart_Anz_02 5000;
BA_REL_ "GenSigTimeoutTime" BU_SG_REL_ Gateway SG_ 1649 KL_Stopp_Wiederstart_Anz_03 5000;
BA_REL_ "GenSigTimeoutTime" BU_SG_REL_ Gateway SG_ 1649 KL_Stopp_Wiederstart_Anz_04 5000;
BA_REL_ "GenSigTimeoutTime" BU_SG_REL_ Gateway SG_ 1649 KL_Stopp_Wiederstart_Anz_05 5000;
BA_REL_ "GenSigTimeoutTime" BU_SG_REL_ Gateway SG_ 1649 KL_Stopp_Wiederstart_Anz_06 5000;
BA_REL_ "GenSigTimeoutTime" BU_SG_REL_ Gateway SG_ 1649 KL_Stopp_Wiederstart_Anz_07 5000;
BA_REL_ "GenSigTimeoutTime" BU_SG_REL_ Gateway SG_ 1649 KL_Stopp_Wiederstart_Anz_08 5000;
BA_REL_ "GenSigTimeoutTime" BU_SG_REL_ Gateway SG_ 1649 KL_Stopp_Wiederstart_Anz_09 5000;
BA_REL_ "GenSigTimeoutTime" BU_SG_REL_ Gateway SG_ 1649 KL_Stopp_Wiederstart_Anz_Std1 5000;
BA_REL_ "GenSigTimeoutTime" BU_SG_REL_ Gateway SG_ 1649 KL_Stopp_Wiederstart_Anz_Std2 5000;
BA_REL_ "GenSigTimeoutTime" BU_SG_REL_ Gateway SG_ 1608 KL_SL_HL_Soll 5000;
BA_REL_ "GenSigTimeoutTime" BU_SG_REL_ Gateway SG_ 1608 KL_SL_HR_Soll 5000;
BA_REL_ "GenSigTimeoutTime" BU_SG_REL_ Gateway SG_ 1608 KL_SH_HR_Soll 5000;
BA_REL_ "GenSigTimeoutTime" BU_SG_REL_ Gateway SG_ 1608 KL_SH_HL_Soll 5000;
BA_REL_ "GenSigTimeoutTime" BU_SG_REL_ Gateway SG_ 949 KL_AC_Schalter 1000;
BA_REL_ "GenSigTimeoutTime" BU_SG_REL_ Gateway SG_ 949 KL_Zustand 1000;
BA_REL_ "GenSigTimeoutTime" BU_SG_REL_ Gateway SG_ 949 KL_Charisma_FahrPr 1000;
BA_REL_ "GenSigTimeoutTime" BU_SG_REL_ Gateway SG_ 949 KL_Charisma_Status 1000;
BA_REL_ "GenSigTimeoutTime" BU_SG_REL_ Gateway SG_ 949 KL_Spannungs_Anf 1000;
BA_REL_ "GenSigTimeoutTime" BU_SG_REL_ Gateway SG_ 949 KL_StartStopp_Info 1000;
BA_REL_ "GenSigTimeoutTime" BU_SG_REL_ Gateway SG_ 949 KL_Anf_KL 1000;
BA_REL_ "GenSigTimeoutTime" BU_SG_REL_ Gateway SG_ 949 KL_el_Zuheizer_Stufe 1000;
BA_REL_ "GenSigTimeoutTime" BU_SG_REL_ Gateway SG_ 949 KL_Ausstattung_Klima 1000;
BA_REL_ "GenSigTimeoutTime" BU_SG_REL_ Gateway SG_ 1640 KL_LRH_Taster 2000;
BA_REL_ "GenSigTimeoutTime" BU_SG_REL_ Gateway SG_ 1640 KL_LRH_Stufe 2000;
BA_REL_ "GenSigTimeoutTime" BU_SG_REL_ Gateway SG_ 1640 HSH_Taster 2000;
BA_REL_ "GenSigTimeoutTime" BU_SG_REL_ Gateway SG_ 1640 FSH_Taster 2000;
BA_REL_ "GenSigTimeoutTime" BU_SG_REL_ Gateway SG_ 1640 KL_Beschlagsgefahr 2000;
BA_REL_ "GenSigTimeoutTime" BU_SG_REL_ Gateway SG_ 1640 KL_SIH_Soll_li 2000;
BA_REL_ "GenSigTimeoutTime" BU_SG_REL_ Gateway SG_ 1640 KL_SIH_Soll_re 2000;
BA_REL_ "GenSigTimeoutTime" BU_SG_REL_ Gateway SG_ 1640 KRH_Soll_li 2000;
BA_REL_ "GenSigTimeoutTime" BU_SG_REL_ Gateway SG_ 1640 KL_SIL_Soll_li 2000;
BA_REL_ "GenSigTimeoutTime" BU_SG_REL_ Gateway SG_ 1640 KL_SIL_Soll_re 2000;
BA_REL_ "GenSigTimeoutTime" BU_SG_REL_ Gateway SG_ 1640 KRH_Soll_re 2000;
BA_REL_ "GenSigTimeoutTime" BU_SG_REL_ Gateway SG_ 1640 KL_I_Geblaese 2000;
BA_REL_ "GenSigTimeoutTime" BU_SG_REL_ Gateway SG_ 1441 KL_SIH_Stufe_hl 5000;
BA_REL_ "GenSigTimeoutTime" BU_SG_REL_ Gateway SG_ 1441 KL_SIH_Stufe_hr 5000;
BA_REL_ "GenSigTimeoutTime" BU_SG_REL_ Gateway SG_ 1441 KL_SIL_Stufe_hl 5000;
BA_REL_ "GenSigTimeoutTime" BU_SG_REL_ Gateway SG_ 1441 KL_SIL_Stufe_hr 5000;
BA_REL_ "GenSigTimeoutTime" BU_SG_REL_ Gateway SG_ 1441 KL_PTC_linear_Anf 5000;
BA_REL_ "GenSigTimeoutTime" BU_SG_REL_ Gateway SG_ 2589283469 KL_VK_Anf 5000;
BA_REL_ "GenSigTimeoutTime" BU_SG_REL_ Gateway SG_ 2589283469 KL_Geblaese_Fond_erw 5000;
BA_REL_ "GenSigTimeoutTime" BU_SG_REL_ Gateway SG_ 2589283469 KL_Geblaese_erw 5000;
BA_REL_ "GenSigTimeoutTime" BU_SG_REL_ Gateway SG_ 2589283469 KL_Vorkond_Strategie 5000;
BA_REL_ "GenSigTimeoutTime" BU_SG_REL_ Gateway_PAG SG_ 1524 IL_Innenlicht_aktiv 5000;
BA_REL_ "GenSigTimeoutTime" BU_SG_REL_ Gateway_PAG SG_ 1524 AMB_Charisma_FahrPr 5000;
BA_REL_ "GenSigTimeoutTime" BU_SG_REL_ Gateway_PAG SG_ 1524 AMB_Charisma_Status 5000;
BA_REL_ "GenSigTimeoutTime" BU_SG_REL_ Gateway_PAG SG_ 1646 KL_STH_aktiv 5000;
BA_REL_ "GenSigTimeoutTime" BU_SG_REL_ Gateway_PAG SG_ 1646 KL_Geblaese_Fond_Status 5000;
BA_REL_ "GenSigTimeoutTime" BU_SG_REL_ Gateway_PAG SG_ 1646 KL_Geblaese_Status 5000;
BA_REL_ "GenSigTimeoutTime" BU_SG_REL_ Gateway_PAG SG_ 1646 KL_BCmE_Livetip_Freigabe 5000;
BA_REL_ "GenSigTimeoutTime" BU_SG_REL_ Gateway_PAG SG_ 1646 KL_Status_Beduftung 5000;
BA_REL_ "GenSigTimeoutTime" BU_SG_REL_ Gateway_PAG SG_ 1646 KL_Status_Ionisator_Front 5000;
BA_REL_ "GenSigTimeoutTime" BU_SG_REL_ Gateway_PAG SG_ 1646 KL_ErwVK_Anf 5000;
BA_REL_ "GenSigTimeoutTime" BU_SG_REL_ Gateway_PAG SG_ 1646 KL_Innen_Temp 5000;
BA_REL_ "GenSigTimeoutTime" BU_SG_REL_ Gateway_PAG SG_ 1646 KL_SIH_LEH_Verteilung_VL 5000;
BA_REL_ "GenSigTimeoutTime" BU_SG_REL_ Gateway_PAG SG_ 1646 KL_SIH_LEL_Verteilung_VL 5000;
BA_REL_ "GenSigTimeoutTime" BU_SG_REL_ Gateway_PAG SG_ 1646 KL_SIH_LEH_Verteilung_VR 5000;
BA_REL_ "GenSigTimeoutTime" BU_SG_REL_ Gateway_PAG SG_ 1646 KL_SIH_LEL_Verteilung_VR 5000;
BA_REL_ "GenSigTimeoutTime" BU_SG_REL_ Gateway_PAG SG_ 1649 KL_Stopp_Wiederstart_Anz_01 5000;
BA_REL_ "GenSigTimeoutTime" BU_SG_REL_ Gateway_PAG SG_ 1649 KL_Stopp_Wiederstart_Anz_02 5000;
BA_REL_ "GenSigTimeoutTime" BU_SG_REL_ Gateway_PAG SG_ 1649 KL_Stopp_Wiederstart_Anz_03 5000;
BA_REL_ "GenSigTimeoutTime" BU_SG_REL_ Gateway_PAG SG_ 1649 KL_Stopp_Wiederstart_Anz_04 5000;
BA_REL_ "GenSigTimeoutTime" BU_SG_REL_ Gateway_PAG SG_ 1649 KL_Stopp_Wiederstart_Anz_05 5000;
BA_REL_ "GenSigTimeoutTime" BU_SG_REL_ Gateway_PAG SG_ 1649 KL_Stopp_Wiederstart_Anz_06 5000;
BA_REL_ "GenSigTimeoutTime" BU_SG_REL_ Gateway_PAG SG_ 1649 KL_Stopp_Wiederstart_Anz_07 5000;
BA_REL_ "GenSigTimeoutTime" BU_SG_REL_ Gateway_PAG SG_ 1649 KL_Stopp_Wiederstart_Anz_08 5000;
BA_REL_ "GenSigTimeoutTime" BU_SG_REL_ Gateway_PAG SG_ 1649 KL_Stopp_Wiederstart_Anz_09 5000;
BA_REL_ "GenSigTimeoutTime" BU_SG_REL_ Gateway_PAG SG_ 1649 KL_Stopp_Wiederstart_Anz_Std1 5000;
BA_REL_ "GenSigTimeoutTime" BU_SG_REL_ Gateway_PAG SG_ 1649 KL_Stopp_Wiederstart_Anz_Std2 5000;
BA_REL_ "GenSigTimeoutTime" BU_SG_REL_ Gateway_PAG SG_ 1608 KL_SL_HL_Soll 5000;
BA_REL_ "GenSigTimeoutTime" BU_SG_REL_ Gateway_PAG SG_ 1608 KL_SL_HR_Soll 5000;
BA_REL_ "GenSigTimeoutTime" BU_SG_REL_ Gateway_PAG SG_ 1608 KL_SH_HR_Soll 5000;
BA_REL_ "GenSigTimeoutTime" BU_SG_REL_ Gateway_PAG SG_ 1608 KL_SH_HL_Soll 5000;
BA_REL_ "GenSigTimeoutTime" BU_SG_REL_ Gateway_PAG SG_ 949 KL_AC_Schalter 1000;
BA_REL_ "GenSigTimeoutTime" BU_SG_REL_ Gateway_PAG SG_ 949 KL_Zustand 1000;
BA_REL_ "GenSigTimeoutTime" BU_SG_REL_ Gateway_PAG SG_ 949 KL_Charisma_FahrPr 1000;
BA_REL_ "GenSigTimeoutTime" BU_SG_REL_ Gateway_PAG SG_ 949 KL_Charisma_Status 1000;
BA_REL_ "GenSigTimeoutTime" BU_SG_REL_ Gateway_PAG SG_ 949 KL_Spannungs_Anf 1000;
BA_REL_ "GenSigTimeoutTime" BU_SG_REL_ Gateway_PAG SG_ 949 KL_StartStopp_Info 1000;
BA_REL_ "GenSigTimeoutTime" BU_SG_REL_ Gateway_PAG SG_ 949 KL_Anf_KL 1000;
BA_REL_ "GenSigTimeoutTime" BU_SG_REL_ Gateway_PAG SG_ 949 KL_el_Zuheizer_Stufe 1000;
BA_REL_ "GenSigTimeoutTime" BU_SG_REL_ Gateway_PAG SG_ 949 KL_Ausstattung_Klima 1000;
BA_REL_ "GenSigTimeoutTime" BU_SG_REL_ Gateway_PAG SG_ 1640 KL_LRH_Taster 2000;
BA_REL_ "GenSigTimeoutTime" BU_SG_REL_ Gateway_PAG SG_ 1640 KL_LRH_Stufe 2000;
BA_REL_ "GenSigTimeoutTime" BU_SG_REL_ Gateway_PAG SG_ 1640 HSH_Taster 2000;
BA_REL_ "GenSigTimeoutTime" BU_SG_REL_ Gateway_PAG SG_ 1640 FSH_Taster 2000;
BA_REL_ "GenSigTimeoutTime" BU_SG_REL_ Gateway_PAG SG_ 1640 KL_SIH_Soll_li 2000;
BA_REL_ "GenSigTimeoutTime" BU_SG_REL_ Gateway_PAG SG_ 1640 KL_SIH_Soll_re 2000;
BA_REL_ "GenSigTimeoutTime" BU_SG_REL_ Gateway_PAG SG_ 1640 KRH_Soll_li 2000;
BA_REL_ "GenSigTimeoutTime" BU_SG_REL_ Gateway_PAG SG_ 1640 KL_SIL_Soll_li 2000;
BA_REL_ "GenSigTimeoutTime" BU_SG_REL_ Gateway_PAG SG_ 1640 KL_SIL_Soll_re 2000;
BA_REL_ "GenSigTimeoutTime" BU_SG_REL_ Gateway_PAG SG_ 1640 KRH_Soll_re 2000;
BA_REL_ "GenSigTimeoutTime" BU_SG_REL_ Gateway_PAG SG_ 1640 KL_I_Geblaese 2000;
BA_REL_ "GenSigTimeoutTime" BU_SG_REL_ Gateway_PAG SG_ 1441 KL_SIH_Stufe_hl 5000;
BA_REL_ "GenSigTimeoutTime" BU_SG_REL_ Gateway_PAG SG_ 1441 KL_SIH_Stufe_hr 5000;
BA_REL_ "GenSigTimeoutTime" BU_SG_REL_ Gateway_PAG SG_ 1441 KL_SIL_Stufe_hl 5000;
BA_REL_ "GenSigTimeoutTime" BU_SG_REL_ Gateway_PAG SG_ 1441 KL_SIL_Stufe_hr 5000;
BA_REL_ "GenSigTimeoutTime" BU_SG_REL_ Gateway_PAG SG_ 1441 KL_PTC_linear_Anf 5000;
BA_REL_ "GenSigTimeoutTime" BU_SG_REL_ Gateway_PAG SG_ 2589283469 KL_VK_Anf 5000;
BA_REL_ "GenSigTimeoutTime" BU_SG_REL_ Gateway_PAG SG_ 2589283469 KL_Geblaese_Fond_erw 5000;
BA_REL_ "GenSigTimeoutTime" BU_SG_REL_ Gateway_PAG SG_ 2589283469 KL_Geblaese_erw 5000;
BA_REL_ "GenSigTimeoutTime" BU_SG_REL_ Gateway_PAG SG_ 2589283469 KL_Vorkond_Strategie 5000;
BA_REL_ "GenSigTimeoutTime" BU_SG_REL_ Klima_MSB SG_ 1381 HVLM_FreigabeKlimatisierung 1000;
BA_REL_ "GenSigTimeoutTime" BU_SG_REL_ Klima_MSB SG_ 1340 HVLM_STH_Betriebsmodus 1000;
BA_REL_ "GenSigTimeoutTime" BU_SG_REL_ Klima_MSB SG_ 1340 HVLM_Standklima_Timer_Status 1000;
BA_REL_ "GenSigTimeoutTime" BU_SG_REL_ Klima_MSB SG_ 1340 HVLM_VK_Modus 1000;
BA_REL_ "GenSigTimeoutTime" BU_SG_REL_ Klima_MSB SG_ 2589283485 HVLM_Dauer_Klima_02 5000;
BA_REL_ "GenSigTimeoutTime" BU_SG_REL_ Klima_MSB SG_ 497 Schluesselnr_Personalisierung 5000;
BA_REL_ "GenSigTimeoutTime" BU_SG_REL_ Klima_MSB SG_ 960 ZAS_Kl_S 1000;
BA_REL_ "GenSigTimeoutTime" BU_SG_REL_ Klima_MSB SG_ 960 ZAS_Kl_15 1000;
BA_REL_ "GenSigTimeoutTime" BU_SG_REL_ Klima_MSB SG_ 960 ZAS_Kl_50_Startanforderung 1000;
BA_REL_ "GenSigTimeoutTime" BU_SG_REL_ Klima_MSB SG_ 960 BCM_Remotestart_Betrieb 1000;
BA_REL_ "GenSigTimeoutTime" BU_SG_REL_ Lift_VA SG_ 960 Klemmen_Status_01_BZ 1000;
BA_REL_ "GenSigTimeoutTime" BU_SG_REL_ Lift_VA SG_ 960 ZAS_Kl_15 1000;
BA_REL_ "GenSigTimeoutTime" BU_SG_REL_ VAS_L SG_ 960 ZAS_Kl_S 1000;
BA_REL_ "GenSigTimeoutTime" BU_SG_REL_ VAS_L SG_ 960 ZAS_Kl_15 1000;
BA_REL_ "GenSigTimeoutTime" BU_SG_REL_ VAS_L SG_ 1646 KL_Anf_AussenspiegelHzg 5000;
BA_REL_ "GenSigTimeoutTime" BU_SG_REL_ VAS_L SG_ 1640 HSH_Taster 2000;
BA_REL_ "GenSigTimeoutTime" BU_SG_REL_ VAS_L SG_ 1640 FSH_Taster 2000;
BA_REL_ "GenSigTimeoutTime" BU_SG_REL_ VAS_R SG_ 960 ZAS_Kl_S 1000;
BA_REL_ "GenSigTimeoutTime" BU_SG_REL_ VAS_R SG_ 960 ZAS_Kl_15 1000;
BA_REL_ "GenSigTimeoutTime" BU_SG_REL_ VAS_R SG_ 1646 KL_Anf_AussenspiegelHzg 5000;
BA_REL_ "GenSigTimeoutTime" BU_SG_REL_ VAS_R SG_ 1640 HSH_Taster 2000;
BA_REL_ "GenSigTimeoutTime" BU_SG_REL_ VAS_R SG_ 1640 FSH_Taster 2000;
VAL_ 1381 HVLM_HV_Abstellzeit 254 "Init" 255 "Fehler" ;
VAL_ 1381 HVLM_Ladesystemhinweise 0 "kein_Hinweis" 1 "Ladesystem_defekt" 2 "Ladesaeule_inkompatibel" 3 "DC_Laden_nicht_moeglich" ;
VAL_ 1381 HVLM_Schluessel_Anfrage 0 "Keine_Anfrage_Init" 1 "Suchanfrage_LKL_1_aktiv" 2 "Suchanfrage_LKL_2_aktiv" 3 "Reserve" ;
VAL_ 1381 HVLM_Zustand_LED 0 "Farbe_1__aus" 1 "Farbe_2__weiss" 2 "Farbe_3__gelb" 3 "Farbe_4__gruen" 4 "Farbe_5__rot" 5 "Farbe_3_pulsierend" 6 "Farbe_4_pulsierend" 7 "Farbe_5_pulsierend" 8 "Farbe_4_5_pulsierend" 9 "Farbe_4__gruen_blinkend" 14 "Init" 15 "Fehler" ;
VAL_ 1381 HVLM_MaxStrom_Netz 126 "Init" 127 "Fehler" ;
VAL_ 1381 HVLM_LG_Sollmodus 0 "Standby" 1 "Netzladung" ;
VAL_ 1381 HVLM_FreigabeTankdeckel 0 "keine_Freigabe" 1 "Freigabe" 2 "Init" 3 "Fehler" ;
VAL_ 1381 HVLM_Stecker_Verriegeln 0 "Stecker_entriegeln" 1 "Stecker_verriegeln" 2 "Init" 3 "keine_Anforderung" ;
VAL_ 1381 HVLM_Start_Spannungsmessung_DCLS 0 "inaktiv" 1 "DCLS_mit_Diode_Start_Messung" 2 "DCLS_ohne_Diode_Start_Messung" 3 "reserve" ;
VAL_ 1381 PnC_Trigger_OBC_cGW 0 "PnC_Init" 1 "PnC_NoNeeds" 2 "PnC_ReportUnknownRootCert" 3 "PnC_CreateVehicleCert" 4 "PnC_DP_RootCertContainer" 5 "PnC_DP_CapabilityIsoTpInfo" 6 "PnC_DP_Contract" 7 "PnC_DP_VehicleCert" 15 "PnC_Error" ;
VAL_ 1381 HVLM_FreigabeKlimatisierung 0 "keine_Freigabe" 1 "Freigabe" 2 "Init" 3 "Fehler" ;
VAL_ 1381 HVLM_Freigabe_Lastabwurf 0 "keine_Freigabe_Lastabwurf" 1 "Freigabe_Lastabwurf" ;
VAL_ 1381 HVLM_Ladetexte 0 "Keine_Anzeige" 1 "AC_Laden_nicht_moeglich" 2 "DC_Laden_nicht_moeglich" 3 "AC_und_DC_Laden_nicht_moeglich" ;
VAL_ 1381 HVLM_IsoMessung_Anf 0 "Laden_mit_Isomessung" 1 "Laden_ohne_Isomessung" ;
VAL_ 1381 HVLM_IstSpannung_HV 1022 "Init" 1023 "Fehler" ;
VAL_ 1340 HVLM_STH_Betriebsmodus 0 "Keine_Klimatisierung" 1 "Heizen" 2 "Abtauen" 6 "Init" 7 "Fehler" ;
VAL_ 1340 HVLM_Standklima_Timer_Status 0 "Standklimatimer_nicht_aktiv" 1 "Standklimatimer_aktiv" ;
VAL_ 1340 HVLM_HVEM_MaxLeistung 510 "Init" 511 "Fehler" ;
VAL_ 1340 HVLM_Status_Netz 0 "Fzg_nicht_am_Netz" 1 "Fzg_ist_am_Stromnetz" ;
VAL_ 1340 HVLM_Anf_Ladescreen 0 "Ladescreen_off" 1 "Ladescreen_on" ;
VAL_ 1340 HVLM_Ladeart 0 "keine_Auswahl" 1 "AC_Laden" 2 "DC_Laden" 3 "Konditionierung" ;
VAL_ 1340 HVLM_VK_STH_Einsatz 0 "Verbrennerstandheizung verbieten" 1 "Automatik (Verbrennerstandheizung erlauben)" 2 "Verbrennerstandheizung erzwingen" 3 "reserviert" 4 "reserviert" 5 "reserviert" 6 "Init" 7 "Fehler" ;
VAL_ 1340 HVLM_VK_Modus 0 "keine Vorkonditionierung" 1 "Sofort-Konditionierung" 2 "zeitversetzte Konditionierung" 3 "Fehler" ;
VAL_ 1340 HVLM_IstModus_02 0 "inaktiv" 1 "aktiv" 2 "Init" 3 "Fehler" ;
VAL_ 1340 HVLM_HV_Anf 0 "keine_Anforderung" 1 "Laden_angefordert" 2 "Batteriekonditionierung_angefordert" 3 "Standklimatisierung_angefordert" ;
VAL_ 1340 HVLM_Fehlerstatus 0 "Komponente_IO" 1 "Eingeschr_KompFkt_DC_Lad_NIO" 2 "Eingeschr_KompFkt_AC_Lad_NIO" 3 "Eingeschr_KompFkt_Interlock" 4 "Eingeschr_KompFkt_reserve" 5 "Eingeschr_KompFkt_reserve" 6 "Keine_Komponentenfunktion" 7 "Init" ;
VAL_ 1340 HVLM_Anforderung_HMS 0 "keine_Anforderung" 1 "halten" 2 "parken" 3 "halten_Standby" 4 "anfahren" 5 "Loesen_ueber_Rampe" ;
VAL_ 1340 HVLM_Parken_beibehalten_HMS 0 "Parken_nicht_beibehalten" 1 "Parken_beibehalten" 2 "Init" 3 "Fehler" ;
VAL_ 1340 HVLM_Status_Tankklappe 0 "geschlossen" 1 "offen" 2 "Init" 3 "Fehler" ;
VAL_ 1340 HVLM_AWC_Sollmodus 0 "init" 1 "Inaktiv" 2 "Standby" 3 "AWCLaden" 4 "Notabschaltung" 5 "Reserve" 6 "Reserve" 7 "Fehler" ;
VAL_ 1340 HVLM_Stecker_Status 0 "Init" 1 "kein_Stecker_gesteckt" 2 "Stecker_erkannt_nicht_verriegelt" 3 "Stecker_erkannt_und_verriegelt" ;
VAL_ 1340 HVLM_LadeAnforderung 0 "keine_Anforderung" 1 "AC_Laden" 2 "DC_Laden" 3 "Nachladen_12V" 4 "AC_Laden_AWC" 5 "Reserve" 6 "Init" 7 "Fehler" ;
VAL_ 1340 HVLM_MaxBatLadestromHV 254 "Init" 255 "Fehler" ;
VAL_ 2589283485 HVLM_Funktion_Dauer_BattKond 0 "inaktiv" 1 "aktiv" ;
VAL_ 2589283485 HVLM_BattKond_Anf 0 "keine_Anforderung" 1 "Anforderung_Heizstufe_1" 2 "Anforderung_Heizstufe_2" 6 "Init" 7 "Fehler" ;
VAL_ 2589283485 HVLM_Dauer_Klima_02 61 "default" 62 "Init" 63 "Fehler" ;
VAL_ 2463978610 HVLM_RtmWarnLadeverbindung 0 "kein_Fehler" 1 "Fehler_Stufe_1" 2 "Fehler_Stufe_2" 3 "Fehler_Stufe_3" 4 "reserviert" 5 "reserviert" 6 "reserviert" 7 "reserviert" ;
VAL_ 2463978610 HVLM_RtmWarnLadesystem 0 "kein_Fehler" 1 "Fehler_Stufe_1" 2 "Fehler_Stufe_2" 3 "Fehler_Stufe_3" 4 "reserviert" 5 "reserviert" 6 "reserviert" 7 "reserviert" ;
VAL_ 2463978610 HVLM_RtmWarnLadestatus 0 "kein_Fehler" 1 "Fehler_Stufe_1" 2 "Fehler_Stufe_2" 3 "Fehler_Stufe_3" 4 "reserviert" 5 "reserviert" 6 "reserviert" 7 "reserviert" ;
VAL_ 2463978610 HVLM_RtmWarnLadeKommunikation 0 "kein_Fehler" 1 "Fehler_Stufe_1" 2 "Fehler_Stufe_2" 3 "Fehler_Stufe_3" 4 "reserviert" 5 "reserviert" 6 "reserviert" 7 "reserviert" ;
VAL_ 2463978610 HVLM_Ladeanzeige_Anf 0 "Licht_Aus" 1 "Licht_An" ;
VAL_ 2463978610 HVLM_Ladeanzeige_Status 0 "Funktion_Aus" 1 "Funktion_Ein_ohne_SOC" 2 "Funktion_Ein_mit_SOC" 3 "Reserve" ;
VAL_ 2463978610 HVLM_Ladeanzeige_Intens_Heck 126 "Init" 127 "Fehler" ;
VAL_ 2463978610 HVLM_Ladeanzeige_Intens_Front 126 "Init" 127 "Fehler" ;
VAL_ 1524 IL_Bel_FS_Ausstieg 0 "inaktiv" 1 "aktiv" ;
VAL_ 1524 IL_Bel_BFS_Ausstieg 0 "inaktiv" 1 "aktiv" ;
VAL_ 1524 IL_Bel_HFS_Ausstieg 0 "inaktiv" 1 "aktiv" ;
VAL_ 1524 IL_Bel_HBFS_Ausstieg 0 "inaktiv" 1 "aktiv" ;
VAL_ 1524 BCM1_Innenlicht_gedimmt_V 0 "100% Innenlicht" 1 "gedimmtes Innenlicht" ;
VAL_ 1524 BCM1_Innenlicht_gedimmt_H 0 "100% Innenlicht" 1 "gedimmtes Innenlicht" ;
VAL_ 1524 IL_Innenlicht_aktiv 0 "Innenlicht inaktiv" 1 "Innenlicht aktiv" ;
VAL_ 1524 IL_Klemme_30G_aktiv 0 "Kl_30G_abgeschaltet" 1 "eingeschaltet" ;
VAL_ 1524 BCM1_DI_Rampe_Innenlicht 0 "Dimmrampe 0" 1 "Dimmrampe 1" ;
VAL_ 1524 BCM1_DI_Rampe_Leselicht 0 "Dimmrampe 0" 1 "Dimmrampe 1" ;
VAL_ 1524 BCM1_Innenlicht_H 0 "Aus" 1 "Ein" ;
VAL_ 1524 BCM1_Innenlicht_V 0 "Aus" 1 "Ein" ;
VAL_ 1524 BCM1_Leselicht_Anf_hl 0 "Aus" 1 "Ein" ;
VAL_ 1524 BCM1_Leselicht_Anf_hr 0 "Aus" 1 "Ein" ;
VAL_ 1524 BCM1_Leselicht_Anf_vl 0 "Aus" 1 "Ein" ;
VAL_ 1524 BCM1_Leselicht_Anf_vr 0 "Aus" 1 "Ein" ;
VAL_ 1524 BCM1_Leuchten_Aus 0 "keine Aenderung" 1 "Aus" ;
VAL_ 1524 AMB_Charisma_FahrPr 0 "keine_Funktion" 1 "Programm_1" 2 "Programm_2" 3 "Programm_3" 4 "Programm_4" 5 "Programm_5" 6 "Programm_6" 7 "Programm_7" 8 "Programm_8" 9 "Programm_9" 10 "Programm_10" 11 "Programm_11" 12 "Programm_12" 13 "Programm_13" 14 "Programm_14" 15 "Programm_15" ;
VAL_ 1524 AMB_Charisma_Status 0 "Init" 1 "verfuegbar" 2 "nicht_verfuegbar" 3 "asynchron_durch_Fahrerwunsch" ;
VAL_ 312 IPA_Anforderung_HMS 0 "keine_Anforderung" 1 "halten" 2 "parken" 3 "halten_Standby" 4 "anfahren" 5 "Loesen_ueber_Rampe" 6 "Parken_mit_P" ;
VAL_ 312 Parken_aktives_System 0 "kein_aktives_System" 1 "Manoevrierassistent_Ueberwachung" 2 "IPA" 3 "fernbedientes_Parken" 4 "Manoevrierassistent" 5 "Manoevrierassistent_quer" 6 "Anhaengerrangierassistent" 7 "fernbedienter_Anhaengerrangierassistent" ;
VAL_ 312 Parken_erhoehtes_Moment 0 "keine_Anforderung" 1 "Anforderung_Rampe1" 2 "Anforderung_Rampe2" 3 "Anforderung_Rampe3" 4 "Anforderung_Rampe4" 5 "Anforderung_Rampe5" 6 "Anforderung_Rampe6" 7 "Anforderung_Rampe7" 8 "Anforderung_Rampe8" 9 "Anforderung_Rampe9" 10 "Anforderung_Rampe10" 11 "Anforderung_Rampe11" 12 "Anforderung_Rampe12" 13 "Anforderung_Rampe13" 14 "Anforderung_Rampe14" 15 "Anforderung_Rampe15" ;
VAL_ 312 Parken_Motorlauf_Anf 0 "Keine_Anforderung" 1 "Motor_aus" 2 "Motor_an" 3 "Weiterlauf_Fahreruebernahme" ;
VAL_ 312 IPA_Fahrstufenwunsch 0 "Init" 1 "Fahrstufe_beibehalten" 2 "Position_R" 3 "Position_D" 4 "Position_N" ;
VAL_ 312 IPA_Status 0 "Init" 4 "IPA_Anzeige_Aktiv" 5 "IPA_Fahreruebernahme" 6 "IPA_Aktiv" 7 "IPA_Standby" 8 "IPA_Funktionsbereit" 9 "IPA_PP_Aktivierung" 10 "IPA_Abbruch" 11 "IPA_Aktivierend" 15 "IPA_PP_Start" ;
VAL_ 312 IPA_Status_IPA_GE 0 "Init" 1 "Neustart" 2 "Funktionsbereit" 3 "Aktiv" 7 "Fehler" ;
VAL_ 312 IPA_Status_IPA_TSK 1 "IPA_TSK_Init" 2 "IPA_TSK_Fehler" 4 "IPA_TSK_aktivierbar" 5 "IPA_TSK_pausiert" 6 "IPA_TSK_aktiv" 8 "IPA_TSK_funktionsbereit" ;
VAL_ 312 IPA_Sollbeschleunigung 0 "Neutralwert" ;
VAL_ 312 Parken_Fahrbereitschaft_Anf 0 "keine_Anforderung" 1 "Anforderung_Fahrbereitschaft" ;
VAL_ 312 IPA_Parken_beibehalten_HMS 0 "Parken_nicht_beibehalten" 1 "Parken_beibehalten" 2 "Init" 3 "Fehler" ;
VAL_ 312 IPA_Status_EDR 0 "Faulted" 1 "Off" 2 "On_but_not_controlling" 3 "On_actively_controlling" ;
VAL_ 312 IPA_PLA_LED 0 "LED_aus" 1 "LED_ein" 2 "LED_blinken" 3 "Funktion_gesperrt__LED_aus" 6 "Init" ;
VAL_ 312 IPA_APS_LED 0 "LED_aus" 1 "LED_ein" 2 "LED_blinken" 3 "Funktion_gesperrt__LED_aus" 6 "Init" ;
VAL_ 2527679583 Parken_Seitenspiegel_Anf 0 "Keine_Anforderung" 1 "Seitenspiegel_anklappen" 2 "Seitenspiegel_abklappen" ;
VAL_ 2527679583 Parken_ZV_Schliessen 0 "Keine_Anforderung" 1 "ZV_verriegeln" 2 "ZV_safen" ;
VAL_ 2527679583 Parken_ZR_Sondermodus_Anf 0 "Init" 1 "Keine_Anforderung" 2 "Anforderung_Sondermodus" ;
VAL_ 2527679583 Parken_Schluesselsuche_Anf 0 "keine_Anforderung" 1 "Anforderung_Schluesselsuche" ;
VAL_ 2527679583 Parken_FFB_LED_Anf 0 "keine_Anforderung" 1 "Abbruch_Fehler" 2 "Bereit_OK" 3 "Beendet" ;
VAL_ 2527679583 Parken_Wegfahrsperren_Anf 0 "keine_Anforderung" 1 "Anforderung_Fahreruebernahme" 2 "Anforderung_Fahreruebergabe" ;
VAL_ 2527679583 Parken_Aktivierungslicht_Anf 0 "keine_Anforderung" 1 "Aktivierungslicht" ;
VAL_ 2527679583 Parken_Fahrtrichtungslicht_Anf 0 "keine_Anforderung" 1 "Vorwaerts" 2 "Rueckwaerts" ;
VAL_ 2527679583 Parken_Lichtnachlauf_Anf 0 "keine_Anforderung" 1 "Anforderung_Lichtnachlauf" ;
VAL_ 2527679583 Parken_Fahrerhinweise_Anf 0 "keine_Anforderung" 1 "Fahrerhinweise_anzeigen" ;
VAL_ 2527679583 Parken_Bestaetigungsblinken_Anf 0 "keine_Anforderung" 1 "Erfolgsblinken_Einparken" 2 "Abbruchsblinken" 3 "Erfolgsblinken_Ausparken" ;
VAL_ 2527679583 Parken_Fahrbereitschaftlicht_Anf 0 "keine_Anforderung" 1 "Fahrbereitschaftslicht" ;
VAL_ 2463978614 KAS_Verfuegbarkeit 0 "Init" 1 "verfuegbar" 2 "nicht_verfuegbar" ;
VAL_ 2463978614 KAS_Kritikalitaetslevel 0 "unkritisch" 1 "Kritikalitaetslevel_1" 2 "Kritikalitaetslevel_2" 3 "Kritikalitaetslevel_3" 4 "Kritikalitaetslevel_4" 5 "Kritikalitaetslevel_5" 6 "reserviert" 7 "nicht_bewertbar" ;
VAL_ 2463978614 KAS_Anf_OPS 0 "Aus" 1 "An" ;
VAL_ 2463978614 KAS_PreSense_Modus_System 0 "deaktiviert" 1 "aktiviert" ;
VAL_ 2463978614 KAS_Status 0 "Init" 1 "Nicht_verfuegbar" 2 "Deaktiviert" 3 "Aktiv" 4 "Passiv" 5 "Blindheit" 6 "Fehler" 7 "reserviert" ;
VAL_ 2463978614 KAS_Anzeige_Info_links 0 "Keine_Anzeige" 1 "Info" 2 "Info_kritisch" ;
VAL_ 2463978614 KAS_Anzeige_Info_rechts 0 "Keine_Anzeige" 1 "Info" 2 "Info_kritisch" ;
VAL_ 2463978614 KAS_Anzeige_Warnung 0 "keine_Anzeige" 1 "Warnung_links" 2 "Warnung_rechts" 3 "Warnung_beidseitig" 4 "Bremsung" ;
VAL_ 2463978614 KAS_Texte 0 "keine_Anzeige" 1 "Stoerung_Bitte_Service_aufsuchen" 2 "Zurzeit_nicht_verfuegbar" 3 "Sensorsicht_umgebungsbedingt_eingeschraenkt" 4 "Eingeschraenkt_Stabilisierungskontrolle_ESC_ausgeschaltet" 5 "In_aktuellem_Audi_drive_select_modus_eingeschraenkt" 6 "Bremsung_erfolgt_Hindernis_erkannt_Bitte_uebernehmen" 7 "Bitte_uebernehmen" ;
VAL_ 2463978614 KAS_Anf_Prefill 0 "Prefill_nicht_angefordert" 1 "Prefill_angefordert" ;
VAL_ 2463978614 KAS_Anf_Bremsruck 0 "keine_Ruckanforderung" 1 "Bremsruck_Profil_01_angefordert" 2 "Bremsruck_Profil_02_angefordert" 3 "Bremsruck_Profil_03_angefordert" 4 "Bremsruck_Profil_04_angefordert" 5 "Bremsruck_Profil_05_angefordert" 6 "Bremsruck_Profil_06_angefordert" 7 "Bremsruck_Profil_07_angefordert" ;
VAL_ 2463978614 KAS_Verz_Anf 254 "Init" 255 "Fehler" ;
VAL_ 497 KY_IDG_in_Reichweite 0 "ausser_Reichweite_bzw_nicht_ermittelbar" 1 "innerhalb_Reichweite" ;
VAL_ 497 KY_Auf_Taste 0 "Taste_nicht_betaetigt" 1 "Oeffnentaste_betaetigt" ;
VAL_ 497 KY_HDF_Taste 0 "Taste_nicht_betaetigt" 1 "HDF_Taste_am_Funkschluessel_betaetigt" ;
VAL_ 497 KY_Panik_Taste 0 "Taste_nicht_betaetigt" 1 "Panik_Taste_am_Funkschluessel_betaetigt" ;
VAL_ 497 KY_Zu_Taste 0 "Taste_nicht_betaetigt" 1 "Zu_Taste_am_Funkschluessel_betaetigt" ;
VAL_ 497 KY_FT_Entriegelung_Autorisiert 0 "kein_Keylessschluessel_erkannt" 1 "Keyless_Schluessel_erkannt_und_authorisiert" ;
VAL_ 497 KY_FT_Verriegelung_Autorisiert 0 "kein_Verriegelungssensor_erkannt" 1 "Verriegelungssensor_erkannt_und_authorisiert" ;
VAL_ 497 KY_BT_Entriegelung_Autorisiert 0 "kein_Keylessschluessel_erkannt" 1 "Keyless_Schluessel_erkannt_und_authorisiert" ;
VAL_ 497 KY_BT_Verriegelung_Autorisiert 0 "kein_Verriegelungssensor_erkannt" 1 "Verriegelungssensor_erkannt_und_authorisiert" ;
VAL_ 497 KY_HFS_Entriegelung_Autorisiert 0 "kein_Keylessschluessel_erkannt" 1 "Keyless_Schluessel_erkannt_und_authorisiert" ;
VAL_ 497 KY_HFS_Verriegelung_Autorisiert 0 "kein_Verriegelungssensor_erkannt" 1 "Verriegelungssensor_erkannt_und_authorisiert" ;
VAL_ 497 KY_HBFS_Entriegelung_Autorisiert 0 "kein_Keylessschluessel_erkannt" 1 "Keyless_Schluessel_erkannt_und_authorisiert" ;
VAL_ 497 KY_HBFS_Verriegelung_Autorisiert 0 "kein_Verriegelungssensor_erkannt" 1 "Verriegelungssensor_erkannt_und_authorisiert" ;
VAL_ 497 KY_Front_Entr_Autorisiert 0 "kein_Keylessschluessel_erkannt" 1 "Keyless_Schluessel_erkannt_und_authorisiert" ;
VAL_ 497 KY_Front_Verr_Autorisiert 0 "kein_Verriegelungssensor_erkannt" 1 "Verriegelungssensor_erkannt_und_authorisiert" ;
VAL_ 497 KY_HD_Entriegelung_Autorisiert 0 "kein_Keylessschluessel_erkannt" 1 "Keyless_Schluessel_erkannt_und_authorisiert" ;
VAL_ 497 KY_HD_Verriegelung_Autorisiert 0 "nicht_autorisiert" 1 "autorisiert" ;
VAL_ 497 KY_Bereich 0 "Bereich_0" 1 "Bereich_1" 2 "Bereich_2" 3 "Bereich_3" 4 "Bereich_4" 5 "Bereich_5" 6 "Kein_Schluessel_gefunden" 7 "Init" ;
VAL_ 497 KY_Position 0 "Position_0" 1 "Postition_1" 2 "Postition_2" 3 "Postition_3" 4 "Postition_4" 6 "Kein_Schluessel_gefunden" 7 "Init" ;
VAL_ 497 Schluesselnr_Personalisierung 1 "Schluesselnummer_eins_aktiv" 2 "Schluesselnummer_zwei_aktiv" 3 "Schluesselnummer_drei_aktiv" 4 "Schluesselnummer_vier_aktiv" 5 "Schluesselnummer_fuenf_aktiv" 6 "Schluesselnummer_sechs_aktiv" 7 "Schluesselnummer_sieben_aktiv" 8 "Schluesselnummer_acht_aktiv" 14 "Init" 15 "Fehler" ;
VAL_ 497 FFB_FDF_Taste 0 "Taste_nicht_betaetigt" 1 "FDF_Taste_am_Funkschluessel_betaetigt" ;
VAL_ 497 FFB_Joker_Taste 0 "Taste_nicht_betaetigt" 1 "Joker_Taste_an_FFFB_betaetigt" ;
VAL_ 497 FFB_Park_Taste 0 "Taste_nicht_betaetigt" 1 "Park_Taste_betaetigt" ;
VAL_ 497 FFB_Remotestart_Taste 0 "Taste_nicht_betaetigt" 1 "Remotestart_Taste_betaetigt" ;
VAL_ 497 FBS_Aktivierung_Pilot_Parken 0 "keine_Funktionsaktivierung" 1 "Aktivierung_FFB_erkannt" ;
VAL_ 497 KY_Schluessel_im_Fzg 0 "Schluessel_nicht_im_Fahrzeug" 1 "Schluessel_im_Fahrzeug" ;
VAL_ 497 KY_EasyClose_Abbruch 0 "EasyClose_kein_Abbruch" 1 "EasyClose_Abbruch" ;
VAL_ 497 KY_EasyClose_Status 0 "Lampe_AUS" 1 "Lampe_EIN" 2 "Lampe_NORMAL" 3 "Lampe_HEKTIK" 4 "Akustik_Verweigerung" ;
VAL_ 497 KY_HD_Auffahrt 0 "keine_Anforderung" 1 "HD_Auffahrt_angefordert" ;
VAL_ 497 KY_HD_Zufahrt 0 "keine_Anforderung" 1 "HD_Zufahrt_angefordert" ;
VAL_ 497 KY_LKL_1_Autorisierung 0 "Kein_Zugang_LKL_1_erkannt" 1 "Zugang_LKL_1_erkannt" ;
VAL_ 497 KY_LKL_2_Autorisierung 0 "Kein_Zugang_LKL_2_erkannt" 1 "Zugang_LKL_2_erkannt" ;
VAL_ 1424 FBS_Warn_Schluessel_Batt 0 "i.O." 1 "defekt" ;
VAL_ 1424 KY_FFB_Frequenz 0 "Init" 1 "433 MHz" 2 "315 MHz" 3 "868 MHz" ;
VAL_ 1424 KY_HF_Aktiv 0 "Funktempfang_nicht_aktiv" 1 "HF_Funkempfang_aktiv" ;
VAL_ 1424 KY_LF_Aktiv 0 "Funktempfang_nicht_aktiv" 1 "LF_Funkempfang_aktiv" ;
VAL_ 1424 KY_KYL_Fahrer_Hinweise 0 "keine_Anzeige" 1 "FZG_Zugang_Kein_Schluessel_erkannt" 2 "Schluessel_im_Innenraum_gefunden" 3 "Schluessel_im_Kofferraum_gefunden" 4 "FZG_Start_Kein_Schluessel_erkannt" 5 "FZG_Start_Kein_Schluessel_oder_NFC_erkannt" 6 "Warn_kein_NFC_erkannt" 7 "KL15_Keine_Autom_Aktivierung" ;
VAL_ 1424 KY_StartStopp_Info 0 "Motorlauf_nicht_notwendig_(Stoppfreigabe)" 1 "Motoranlauf_nicht_zwingend_notwendig_(Stoppverbot,keine_Startanforderung)" 2 "Motoranlauf_zwingend_notwendig_(Startanforderung)" 3 "Systemfehler" ;
VAL_ 1424 KY_Keyless_Verbau 0 "nicht_verbaut" 1 "verbaut" ;
VAL_ 1424 KY_Keyless_Go_Verbau 0 "nicht_verbaut" 1 "verbaut" ;
VAL_ 1424 KY_Transponder_aktiv 0 "nicht_aktiv" 1 "aktiv" ;
VAL_ 1424 KYL_Warn_kein_Schluessel 1 "kein Schluessel erkannt" ;
VAL_ 1424 KYL_Warn_Kessy_defekt 0 "Kessy_i.O." 1 "Kessy defekt" ;
VAL_ 1424 KYL_Warn_Notzuendschloss 0 "Aus" 1 "Ein" ;
VAL_ 1424 KY_Fzg_Verlassen_erkannt 0 "nicht_erkannt" 1 "erkannt" ;
VAL_ 1424 KY_Fzg_Zugang_erkannt 0 "nicht_erkannt" 1 "erkannt" ;
VAL_ 1424 KY_Indikator_Mehrere_Schluessel 0 "Init" 1 "Mehrere_Schluessel_im_Fahrzeug_gefunden" ;
VAL_ 1424 KY_NFC_Fahrer_Hinweise 0 "Init" 1 "Warn_kein_Keyless_gueltiges_NFC" 2 "Warn_gueltiges_Keyless_kein_NFC" ;
VAL_ 1424 KST_Wegstrecke_Challenge 0 "Init" ;
VAL_ 960 RSt_Fahrerhinweise 0 "Init" 1 "Fahreruebernahme_Hinweis_ZAT_Automat_ohne_Gong" 2 "Fahreruebernahme_Hinweis_ZAT_Automat_mit_Gong" 3 "Fahreruebernahme_Hinweis_ZAT_Handschalter_ohne_Gong" 4 "Fahreruebernahme_Hinweis_ZAT_Handschalter_mit_Gong" 5 "Fahreruebernahme_Hinweis_ZAS_Automat_ohne_Gong" 6 "Fahreruebernahme_Hinweis_ZAS_Automat_mit_Gong" 7 "Fahreruebernahme_Hinweis_ZAS_Handschalter_ohne_Gong" 8 "Fahreruebernahme_Hinweis_ZAS_Handschalter_mit_Gong" 9 "RemoteStart_aktiv_ohne_Gong" 10 "RemoteStart_aktiv_mit_Gong" 11 "void" 12 "void" 13 "void" 14 "void" 15 "void" ;
VAL_ 960 ZAS_Kl_S 0 "aus" 1 "S_Kontakt_ein" ;
VAL_ 960 ZAS_Kl_15 0 "aus" 1 "ein" ;
VAL_ 960 ZAS_Kl_X 0 "aus" 1 "ein" ;
VAL_ 960 ZAS_Kl_50_Startanforderung 0 "aus" 1 "KL50_ein_Startwunsch_Fahrer" ;
VAL_ 960 BCM_Remotestart_Betrieb 0 "kein_RS_Betrieb" 1 "RS_Betrieb" ;
VAL_ 960 ZAS_Kl_Infotainment 0 "inaktiv" 1 "aktiv" ;
VAL_ 960 BCM_Remotestart_KL15_Anf 0 "inaktiv" 1 "aktiv" ;
VAL_ 960 BCM_Remotestart_MO_Start 0 "nicht_angefordert" 1 "angefordert" ;
VAL_ 960 KST_Warn_P1_ZST_def 0 "nicht_defekt" 1 "defekt" ;
VAL_ 960 KST_Warn_P2_ZST_def 0 "nicht_defekt" 1 "defekt" ;
VAL_ 960 KST_Fahrerhinweis_1 0 "inaktiv" 1 "aktiv" ;
VAL_ 960 KST_Fahrerhinweis_2 0 "inaktiv" 1 "aktiv" ;
VAL_ 960 BCM_Ausparken_Betrieb 0 "kein_Betrieb" 1 "Ausparkvorgang_aktiv" ;
VAL_ 960 KST_Fahrerhinweis_4 0 "inaktiv" 1 "aktiv" ;
VAL_ 960 KST_Fahrerhinweis_5 0 "inaktiv" 1 "aktiv" ;
VAL_ 960 KST_Fahrerhinweis_6 0 "inaktiv" 1 "aktiv" ;
VAL_ 1420 KST_Txt_P_Gang 0 "Aus" 1 "Ein" ;
VAL_ 1420 KST_Txt_Panikabschaltung 0 "Aus" 1 "Ein" ;
VAL_ 1420 KST_Anf_Klemmenfreigabe_ELV 0 "nicht_angefordert" 1 "angefordert" ;
VAL_ 1420 KST_Txt_Komfortabschaltung 0 "inaktiv" 1 "aktiv" ;
VAL_ 1420 KST_ZAT_betaetigt 0 "Aus" 1 "Ein" ;
VAL_ 1420 KST_Unterdr_Zuendungsmeldung 0 "keine_Unterdr_der_Zuendungsmeldung" 1 "Unterdr_der_Zuendungsmeldung_aktiv" ;
VAL_ 1420 KST_aut_Abschaltung_Zuendung 0 "Zuendung_wird_bei_Verl_nicht_deaktiviert" 1 "Zuendung_wird_bei_Verl_deaktiviert" ;
VAL_ 1420 KST_Anf_ZV_Verriegelung 0 "inaktiv" 1 "aktiv" ;
VAL_ 1420 Relais_VoKo_angesteuert 0 "nicht_angesteuert" 1 "angesteuert" ;
VAL_ 1420 RSt_Anforderung_HMS 0 "keine_Anforderung" 1 "halten" 2 "parken" 3 "halten_Standby" 4 "anfahren" 5 "Loesen_ueber_Rampe" 6 "Parken_mit_P" ;
VAL_ 1646 KL_STL_aktiv 0 "Standlueftung_nicht_aktiv" 1 "Standlueftung_aktiv" ;
VAL_ 1646 KL_STH_aktiv 0 "Standheizung_nicht_aktiv" 1 "Standheizung_aktiv" ;
VAL_ 1646 KL_Solarluefter_aktiv 0 "Solarluefter_nicht_aktiv" 1 "Solarluefter_aktiv__auto" ;
VAL_ 1646 KL_Umluft_Taste 0 "Taste_nicht_gedrueckt" 1 "Taste_gedrueckt" ;
VAL_ 1646 KL_Geblaese_Fond_Status 0 "Geblaese_aus" 1 "Geblaesestufe_10" 2 "Geblaesestufe_20" 3 "Geblaesestufe_30" 4 "Geblaesestufe_40" 5 "Geblaesestufe_50" 6 "Geblaesestufe_60" 7 "Geblaesestufe_70" 8 "Geblaesestufe_80" 9 "Geblaesestufe_90" 10 "Geblaesestufe_100" 14 "Init" 15 "Fehler" ;
VAL_ 1646 KL_STH_Ansteuerung 0 "Aus" 1 "Ein" 2 "Ein_mit_Motorvorwaermung" 3 "Heizleistung_reduziert" ;
VAL_ 1646 KL_Magnetventil 0 "Aus" 1 "Ein" ;
VAL_ 1646 KL_WaPu 0 "Wasserpumpe_aus" 1 "Wasserpumpe_aktiv" ;
VAL_ 1646 KL_Geblaese_Status 0 "Geblaese_aus" 1 "Geblaesestufe_10" 2 "Geblaesestufe_20" 3 "Geblaesestufe_30" 4 "Geblaesestufe_40" 5 "Geblaesestufe_50" 6 "Geblaesestufe_60" 7 "Geblaesestufe_70" 8 "Geblaesestufe_80" 9 "Geblaesestufe_90" 10 "Geblaesestufe_100" 14 "Init" 15 "Fehler" ;
VAL_ 1646 KL_Restwaerme_aktiv 0 "inaktiv" 1 "aktiv" ;
VAL_ 1646 KL_Kompressorkupplung 0 "oeffnen" 1 "schliessen" ;
VAL_ 1646 KL_BCmE_Livetip_Freigabe 0 "Anzeige_Livetip_nicht_zulaessig" 1 "Anzeige_Livetip_zulaessig" ;
VAL_ 1646 KL_HYB_ASV_hinten_schliessen_Anf 0 "keine_Anforderung" 1 "Ventil_schliessen" ;
VAL_ 1646 KL_HYB_ASV_vorne_schliessen_Anf 0 "keine_Anforderung" 1 "Ventil_schliessen" ;
VAL_ 1646 KL_ErwVK_Zusatzrelais 0 "nicht_angefordert" 1 "angefordert" ;
VAL_ 1646 KL_Status_Beduftung 0 "inaktiv" 1 "aktiv" ;
VAL_ 1646 KL_Status_Ionisator_Front 0 "inaktiv" 1 "aktiv" ;
VAL_ 1646 KL_STH_Timer_Status 0 "TimerInaktiv" 1 "TimerAktiv" ;
VAL_ 1646 KL_ErwVK_Anf 0 "nicht_angefordert" 1 "angefordert" ;
VAL_ 1646 KL_Innen_Temp 253 "nicht_verbaut" 254 "nicht_verfuegbar" 255 "Fehler" ;
VAL_ 1646 KL_I_Geblaese_Fond 255 "Fehler" ;
VAL_ 1646 KL_Anf_AussenspiegelHzg 0 "nicht_angefordert" 1 "angefordert" ;
VAL_ 1646 KL_Heizkreisventilstellung 0 "Init" 1 "Ventilstellung_gem_Anforderung" 2 "Ventilstellung_abweichend_Anf" 3 "Fehler" ;
VAL_ 1646 KL_FSH_Automatikbetrieb 0 "aus" 1 "angefordert_durch_Regelung" ;
VAL_ 1646 KL_SIH_LEH_Verteilung_VL 0 "gleichmaessige_Verteilung" 1 "Sitz_Prio_Hoch" 2 "Sitz_Prio_Mittel" 3 "Sitz_Prio_Niedrig" 4 "Lehne_Prio_Niedrig" 5 "Lehne_Prio_Mittel" 6 "Lehne_Prio_Hoch" ;
VAL_ 1646 KL_SIH_LEL_Verteilung_VL 0 "gleichmaessige_Verteilung" 1 "Sitz_Prio_Hoch" 2 "Sitz_Prio_Mittel" 3 "Sitz_Prio_Niedrig" 4 "Lehne_Prio_Niedrig" 5 "Lehne_Prio_Mittel" 6 "Lehne_Prio_Hoch" ;
VAL_ 1646 KL_SIH_LEH_Verteilung_VR 0 "gleichmaessige_Verteilung" 1 "Sitz_Prio_Hoch" 2 "Sitz_Prio_Mittel" 3 "Sitz_Prio_Niedrig" 4 "Lehne_Prio_Niedrig" 5 "Lehne_Prio_Mittel" 6 "Lehne_Prio_Hoch" ;
VAL_ 1646 KL_SIH_LEL_Verteilung_VR 0 "gleichmaessige_Verteilung" 1 "Sitz_Prio_Hoch" 2 "Sitz_Prio_Mittel" 3 "Sitz_Prio_Niedrig" 4 "Lehne_Prio_Niedrig" 5 "Lehne_Prio_Mittel" 6 "Lehne_Prio_Hoch" ;
VAL_ 1663 KL_Mod_Display_li 0 "Solltemperatur" 1 "Luftverteilung" 2 "Sitzheizung" 3 "Sitzlueftung" 4 "Luftmenge" 9 "OBD" 10 "Display_off" ;
VAL_ 1663 KL_Mod_Display_re 0 "Solltemperatur" 1 "Luftverteilung" 2 "Sitzheizung" 3 "Sitzlueftung" 4 "Luftmenge" 9 "OBD" 10 "Display_off" ;
VAL_ 1663 KL_Fondbed_vorne_aktiv 0 "nicht_aktiv" 1 "Bedienung_von_vorne_ist_aktiv" ;
VAL_ 1663 KL_Fond_re_reduziert 1 "Leistungsreduzierung" ;
VAL_ 1663 KL_Fond_li_reduziert 1 "Leistungsreduzierung" ;
VAL_ 1663 KL_Absperrventil_Fond 0 "nicht_ansteuern" 1 "ansteuern" ;
VAL_ 1663 KL_SH_HL_Lastabschaltung 0 "keine_Einschraenkung" 1 "Taktung" 2 "Abschaltung" ;
VAL_ 1663 KL_SH_HR_Lastabschaltung 0 "keine_Einschraenkung" 1 "Taktung" 2 "Abschaltung" ;
VAL_ 1663 KL_Sollausblastemp_HL 1023 "Fehler" ;
VAL_ 1663 KL_Einheiten 0 "°C" 1 "°F" ;
VAL_ 1663 KL_Kindersicherung 0 "nicht_aktiv" 1 "aktiv" ;
VAL_ 1663 KL_Heizverbraucher_aus 0 "keine_Einschraenkung" 1 "Heizverbraucher_deaktivieren" ;
VAL_ 1663 KL_Heizverbraucher_Notaus 0 "keine_Einschraenkung" 1 "Heizverbraucher_sofort_deaktivieren" ;
VAL_ 1663 KL_Gebl_Verst_Abs_Modus 0 "Aus" 1 "Ein" ;
VAL_ 1663 KL_Sollausblastemp_HR 1023 "Fehler" ;
VAL_ 1663 KL_ICO2_Sensor_defekt 0 "Init" 1 "nicht_defekt" 2 "defekt" 3 "CO2_Warnung" ;
VAL_ 1663 KL_Umluft 254 "Init" 255 "Fehler" ;
VAL_ 1649 KL_ZZ_Status_Timer 0 "Timer_n_aktiv_bzw_loeschen" 1 "Timer_aktiv_bzw_aktivieren" ;
VAL_ 1649 KL_ZZ_Monat 0 "Init" ;
VAL_ 1649 KL_ZZ_Betriebsmodus 0 "Do_not_Care" 1 "ECO" 2 "Standard" 3 "Standard_plus" 4 "Comfort" ;
VAL_ 1649 KL_ZZ_Tag 0 "Init" ;
VAL_ 1649 KL_Betriebsmodus_FH 0 "undefined__init" 1 "Klemme15" 2 "Standheizung" 3 "Restwaerme" 4 "Nachlauf" 5 "Standlueften" 6 "Betriebsart_X" 7 "Betriebsart_Y" ;
VAL_ 1649 KL_Stopp_Wiederstart_Anz_01 0 "keine_Anzeige" 1 "Geblaese" ;
VAL_ 1649 KL_Stopp_Wiederstart_Anz_02 0 "keine_Anzeige" 1 "Differenz_Soll_Ausblas_zu_Ist_Ausblastemperatur" ;
VAL_ 1649 KL_Stopp_Wiederstart_Anz_03 0 "keine_Anzeige" 1 "Beschlagsgefahr" ;
VAL_ 1649 KL_Stopp_Wiederstart_Anz_04 0 "keine_Anzeige" 1 "Differenz_Soll_Innentemperatur_zu_Ist_Innenraumtemperatur" ;
VAL_ 1649 KL_Stopp_Wiederstart_Anz_05 0 "keine_Anzeige" 1 "Komfortfeuchte" ;
VAL_ 1649 KL_Stopp_Wiederstart_Anz_06 0 "keine_Anzeige" 1 "Aussentemperatur" ;
VAL_ 1649 KL_Stopp_Wiederstart_Anz_07 0 "keine_Anzeige" 1 "Defrost" ;
VAL_ 1649 KL_Stopp_Wiederstart_Anz_08 0 "keine_Anzeige" 1 "High_Low" ;
VAL_ 1649 KL_Stopp_Wiederstart_Anz_09 0 "keine_Anzeige" 1 "Frontscheibenheizung" ;
VAL_ 1649 KL_Stopp_Wiederstart_Anz_Std1 0 "keine_Anzeige" 1 "maxA/C" ;
VAL_ 1649 KL_Stopp_Wiederstart_Anz_Std2 0 "keine_Anzeige" 1 "Sitzlueftung" ;
VAL_ 1608 KL_AUTO_HL_Soll 0 "AUTO_nicht_aktiv" 1 "AUTO_aktiv" ;
VAL_ 1608 KL_AUTO_HR_Soll 0 "AUTO_nicht_aktiv" 1 "AUTO_aktiv" ;
VAL_ 1608 KL_AC_Fond_Soll 0 "AC_nicht_aktiv" 1 "AC_aktiv" ;
VAL_ 1608 KL_Fondbedienung_aktiv 0 "nicht_aktiv" 1 "aktiv" ;
VAL_ 1608 KL_Status_Soll 0 "AUS" 1 "EIN" ;
VAL_ 1608 KL_Luftverteilung_HR_Soll 0 "MA" 1 "Fussraum" 2 "PfostenB" 3 "MA+Fuß" 4 "MA+PfostenB" 5 "Fuß+PfostenB" 6 "MA+Fuß+PfostenB" 7 "AUTO-LV" ;
VAL_ 1608 KL_Luftverteilung_HL_Soll 0 "MA" 1 "Fussraum" 2 "PfostenB" 3 "MA+Fuß" 4 "MA+PfostenB" 5 "Fuß+PfostenB" 6 "MA+Fuß+PfostenB" 7 "AUTO-LV" ;
VAL_ 949 KL_Drehz_Anh 0 "keine_Anhebung" 1 "Drehzahlanhebung_vom_Motor_angefordert" ;
VAL_ 949 KL_Vorwarn_Komp_ein 0 "Init" 1 "Vorwarnung_Kompressor_ein" ;
VAL_ 949 KL_AC_Schalter 0 "aus" 1 "ein" ;
VAL_ 949 KL_Komp_Moment_alt 1 "veraltet_bzw_Ermittlung_des_Moments_nicht_moeglich__zB_keine_Drehzahl_kein_Kaeltemitteldruck" ;
VAL_ 949 KL_Vorwarn_Zuheizer_ein 0 "keine_Vorwarnung" 1 "Vorwarnung_Zuheizer_ein" ;
VAL_ 949 KL_Zustand 0 "Aus" 1 "Ein" ;
VAL_ 949 KL_Kompressorkupplung_linear 253 "volle_Ansteuerung" 254 "Init__nicht_bedient" ;
VAL_ 949 KL_Charisma_FahrPr 0 "keine_Funktion" 1 "Programm_1" 2 "Programm_2" 3 "Programm_3" 4 "Programm_4" 5 "Programm_5" 6 "Programm_6" 7 "Programm_7" 8 "Programm_8" 9 "Programm_9" 10 "Programm_10" 11 "Programm_11" 12 "Programm_12" 13 "Programm_13" 14 "Programm_14" 15 "Programm_15" ;
VAL_ 949 KL_Charisma_Status 0 "Init" 1 "verfuegbar" 2 "nicht_verfuegbar" 3 "asynchron_durch_Fahrerwunsch" ;
VAL_ 949 KL_nachtr_Stopp_Anf 0 "nicht_angefordert" 1 "angefordert" ;
VAL_ 949 KL_T_Charge 0 "Taster_nicht_betaetigt" 1 "Taster_betaetigt" ;
VAL_ 949 KL_Last_Kompr 255 "Fehler" ;
VAL_ 949 KL_Spannungs_Anf 0 "keine_Anforderung" 1 "Anforderung_Stufe_1" 2 "Anforderung_Stufe_2" 3 "Anforderung_Stufe_3" ;
VAL_ 949 KL_Thermomanagement 0 "keine_Freigabe_TMM__max_Heizbedarf" 1 "kleine_Freigabe_TMM" 2 "mittlere_Freigabe_TMM" 3 "volle_Freigabe_TMM__kein_Heizbedarf" ;
VAL_ 949 KL_StartStopp_Info 0 "Motorlauf_nicht_notwendig_(Stoppfreigabe)" 1 "Motoranlauf_nicht_zwingend_notwendig_(Stoppverbot,keine_Startanforderung)" 2 "Motoranlauf_zwingend_notwendig_(Startanforderung)" 3 "Systemfehler" ;
VAL_ 949 KL_Freilauf_Info 0 "Freilauf_freigegeben" 1 "Uebergang_in_Freilauf_unzulaessig" 2 "Freilauf_nicht_freigegeben_Abbruch" 3 "Freilauf_Anforderung" ;
VAL_ 949 KL_Anf_KL 255 "Fehler" ;
VAL_ 949 KL_el_Zuheizer_Stufe 0 "Aus" 1 "Stufe_1" 2 "Stufe_2" 3 "Stufe_3" ;
VAL_ 949 KL_Ausstattung_Klima 0 "Heizung_elektrisch" 1 "Klimamanuell_elektrisch" 2 "Climatic__1_Zone" 3 "Climatronic__1_Zone" 4 "Climatronic__2_Zonen" 5 "Climatronic__3_Zonen" 6 "Climatronic__4_Zonen" 7 "reserviert" ;
VAL_ 949 KL_Variante_Standheizung 0 "Wasserstandheizung_60_min_Laufzeit" 1 "Luftstandheizung_120_min_Laufzeit" 2 "Wasserstandheizung_120_min_Laufzeit" 3 "Wasser_und_Luftstandheizung_120_min_Laufzeit" ;
VAL_ 1640 KL_LRH_Taster 0 "nicht_betaetigt" 1 "betaetigt" ;
VAL_ 1640 KL_LRH_Stufe 0 "Stufe_niedrig" 1 "Stufe_mittel" 2 "Stufe_hoch" 3 "AUS" ;
VAL_ 1640 HSH_Taster 0 "nicht_betaetigt" 1 "short_push" 2 "long_push" 3 "tbd" ;
VAL_ 1640 FSH_Taster 0 "nicht_betaetigt" 1 "betaetigt" ;
VAL_ 1640 KL_Zuheizer_Freigabe 0 "keine_Freigabe_Zuheizer" 1 "Zuheizerfreigabe" ;
VAL_ 1640 KL_Beschlagsgefahr 0 "keine_Beschlagsgefahr" 1 "Beschlagsgefahr" ;
VAL_ 1640 KRH_Soll_li 0 "aus" 1 "Stufe_1" 2 "Stufe_2" 3 "Stufe_3" ;
VAL_ 1640 KRH_Soll_re 0 "aus" 1 "Stufe_1" 2 "Stufe_2" 3 "Stufe_3" ;
VAL_ 1640 KL_Geblspng_Soll 0 "0V_Motorspannung" 252 "0V_sofort_Abschalten" 253 "0V_senken_mit_Rampe" 254 "reserviert" 255 "Fehler" ;
VAL_ 1640 KL_Geblspng_Fond_Soll 0 "0V_Motorspannung" 252 "0V_sofort_Abschalten" 253 "0V_senken_mit_Rampe" 254 "reserviert" 255 "Fehler" ;
VAL_ 1640 KL_I_Geblaese 255 "Fehler" ;
VAL_ 1640 KL_Kompressorstrom_soll 1022 "Init" 1023 "Fehler" ;
VAL_ 1640 KL_Umluftklappe_Status 0 "Frischluft" 1 "Teilumluft_10" 2 "Teilumluft_20" 3 "Teilumluft_30" 4 "Teilumluft_40" 5 "Teilumluft_50" 6 "Teilumluft_60" 7 "Teilumluft_70" 8 "Teilumluft_80" 9 "Teilumluft_90" 10 "Umluft" 14 "Init" 15 "Fehler" ;
VAL_ 1640 KL_PTC_Verbauinfo 0 "kein_PTC" 1 "600W_geschaltet" 2 "1000W_geschaltet" 3 "1400W_LIN" ;
VAL_ 1441 KL_Temp_Soll_hl 30 "Klima_OFF" 31 "Init" ;
VAL_ 1441 KL_Temp_Soll_hr 30 "Klima_OFF" 31 "Init" ;
VAL_ 1441 KL_Temp_Soll_vl 30 "Klima_OFF" 31 "Init" ;
VAL_ 1441 KL_Temp_Soll_vr 30 "Klima_OFF" 31 "Init" ;
VAL_ 1441 KL_SIH_Stufe_hl 7 "nicht_verbaut" ;
VAL_ 1441 KL_SIH_Stufe_hr 7 "nicht_verbaut" ;
VAL_ 1441 KL_SIL_Stufe_hl 7 "nicht_verbaut" ;
VAL_ 1441 KL_SIL_Stufe_hr 7 "nicht_verbaut" ;
VAL_ 1441 KL_SIL_LEL_Verteilung_HR 0 "gleichmaessige_Verteilung" 1 "Sitz_Prio_Hoch" 2 "Sitz_Prio_Mittel" 3 "Sitz_Prio_Niedrig" 4 "Lehne_Prio_Niedrig" 5 "Lehne_Prio_Mittel" 6 "Lehne_Prio_Hoch" ;
VAL_ 1441 KL_SIL_LEL_Verteilung_HL 0 "gleichmaessige_Verteilung" 1 "Sitz_Prio_Hoch" 2 "Sitz_Prio_Mittel" 3 "Sitz_Prio_Niedrig" 4 "Lehne_Prio_Niedrig" 5 "Lehne_Prio_Mittel" 6 "Lehne_Prio_Hoch" ;
VAL_ 1441 KL_SIH_LEH_Verteilung_HR 0 "gleichmaessige_Verteilung" 1 "Sitz_Prio_Hoch" 2 "Sitz_Prio_Mittel" 3 "Sitz_Prio_Niedrig" 4 "Lehne_Prio_Niedrig" 5 "Lehne_Prio_Mittel" 6 "Lehne_Prio_Hoch" ;
VAL_ 1441 KL_PTC_linear_Anf 0 "Init" 63 "Fehler" ;
VAL_ 1441 KL_SIH_LEH_Verteilung_HL 0 "gleichmaessige_Verteilung" 1 "Sitz_Prio_Hoch" 2 "Sitz_Prio_Mittel" 3 "Sitz_Prio_Niedrig" 4 "Lehne_Prio_Niedrig" 5 "Lehne_Prio_Mittel" 6 "Lehne_Prio_Hoch" ;
VAL_ 1441 KL_Frischluftklappe_Status 126 "Init" 127 "Fehler" ;
VAL_ 2589283469 KL_Verdampferleistung 254 "Init" 255 "Fehler" ;
VAL_ 2589283469 KL_VK_Anf 0 "keine_Startanf_von_Climatronic" 1 "Startanf_via_FFB" 2 "Startanf_via_Sofortheiztaste" 3 "VK_Strategie_STH" 4 "Startanf_via_ZV_FFB" 5 "VK_Abbruch" 6 "Init" 7 "Fehler" ;
VAL_ 2589283469 KL_Verdampferleistung_Faktor 0 "Faktor_1" 1 "Faktor_2" ;
VAL_ 2589283469 KL_Geblaese_Fond_erw 0 "Geblaese_aus" 1 "Geblaesestufe_10" 2 "Geblaesestufe_20" 3 "Geblaesestufe_30" 4 "Geblaesestufe_40" 5 "Geblaesestufe_50" 6 "Geblaesestufe_60" 7 "Geblaesestufe_70" 8 "Geblaesestufe_80" 9 "Geblaesestufe_90" 10 "Geblaesestufe_100" 14 "Init" 15 "Fehler" ;
VAL_ 2589283469 KL_Geblaese_erw 0 "Geblaese_aus" 1 "Geblaesestufe_10" 2 "Geblaesestufe_20" 3 "Geblaesestufe_30" 4 "Geblaesestufe_40" 5 "Geblaesestufe_50" 6 "Geblaesestufe_60" 7 "Geblaesestufe_70" 8 "Geblaesestufe_80" 9 "Geblaesestufe_90" 10 "Geblaesestufe_100" 14 "Init" 15 "Fehler" ;
VAL_ 2589283469 KL_Vorkond_Strategie 0 "Aus" 1 "Spülen" 2 "Kanalkühlung" 3 "Kühlwasserzirkulation" 4 "Aktive Kühlung" 5 "Heizen" 6 "Reheat" 7 "Heizen_elektrisch" 8 "Heizen_verbrennungstechnisch" 13 "Strategie_nicht_berechnet" 14 "Konditionierung_nicht_moeglich" 15 "Init" ;
VAL_ 2589283469 KL_Tempklappe_re 254 "Init" 255 "Fehler" ;
VAL_ 2589283469 KL_Tempklappe_li 254 "Init" 255 "Fehler" ;
VAL_ 2589283469 KL_Tempklappe_Fond 254 "Init" 255 "Fehler" ;
VAL_ 2589283469 KL_Kuehllstg_Delta_Eingriff 254 "Init" 255 "Fehler" ;
VAL_ 2589283469 KL_Heizlstg_Delta_Eingriff 254 "Init" 255 "Fehler" ;
